VERSION "2021.24.4"

NS_ :

BS_:

BU_: VEH CH Receiver X

BO_ 691 VCRIGHT_logging1Hz: 8 VEH
 SG_ VCRIGHT_logging1HzIndex M : 0|4@1+ (1,0) [0|11] "" X
 SG_ VCRIGHT_LHPanelAirflowBlocked m3 : 54|1@1+ (1,0) [0|1] "" X
 SG_ VCRIGHT_RHPanelAirflowBlocked m3 : 55|1@1+ (1,0) [0|1] "" X
 SG_ VCRIGHT_cabinTempBreathLevel m1 : 56|8@1+ (0.5,-40) [-40|80] "C" X
 SG_ VCRIGHT_cabinTempFanCurrent m9 : 15|6@1- (0.001,0) [-0.01|0.05] "A" X
 SG_ VCRIGHT_cabinTempFanOutput m9 : 14|1@1+ (1,0) [0|1] "" X
 SG_ VCRIGHT_cabinTempGlassRoof m1 : 8|8@1+ (0.5,-40) [-40|80] "C" X
 SG_ VCRIGHT_cabinTempInterior m1 : 24|8@1+ (0.5,-40) [-40|80] "C" X
 SG_ VCRIGHT_cabinTempInteriorL2 m0 : 24|8@1+ (0.5,-40) [-40|80] "C" X
 SG_ VCRIGHT_cabinTempInteriorL3 m9 : 40|8@1+ (0.5,-40) [-40|80] "C" X
 SG_ VCRIGHT_cabinTempInteriorSunny m1 : 32|8@1+ (0.6,-40) [-40|100] "C" X
 SG_ VCRIGHT_cabinTempInteriorSunnyL2 m0 : 40|8@1+ (0.6,-40) [-40|100] "C" X
 SG_ VCRIGHT_cabinTempInteriorSunnyL3 m9 : 48|8@1+ (0.6,-40) [-40|100] "C" X
 SG_ VCRIGHT_cabinTempSideGlassLeft m1 : 40|8@1+ (0.5,-40) [-40|80] "C" X
 SG_ VCRIGHT_cabinTempSideGlassRight m1 : 48|8@1+ (0.5,-40) [-40|80] "C" X
 SG_ VCRIGHT_cabinTempTopPadAir m9 : 56|8@1+ (0.6,-40) [-40|100] "C" X
 SG_ VCRIGHT_cabinTempWindshield m1 : 16|8@1+ (0.5,-40) [-40|80] "C" X
 SG_ VCRIGHT_cloudinessProbability m9 : 33|7@1+ (1,0) [0|100] "%" X
 SG_ VCRIGHT_convectionDeliveredLeft m4 : 24|8@1+ (2,-254) [-254|256] "W/m2" X
 SG_ VCRIGHT_convectionDeliveredRight m4 : 32|8@1+ (2,-254) [-254|256] "W/m2" X
 SG_ VCRIGHT_convectionTargetLeft m4 : 8|8@1+ (2,-254) [-254|256] "W/m2" X
 SG_ VCRIGHT_convectionTargetRight m4 : 16|8@1+ (2,-254) [-254|256] "W/m2" X
 SG_ VCRIGHT_defrostAirflowBlocked m3 : 57|1@1+ (1,0) [0|1] "" X
 SG_ VCRIGHT_evapCondensationRate m10 : 47|9@1- (0.007,0) [-1|1] "g/s" X
 SG_ VCRIGHT_evapDryingRoutineRuntime m10 : 56|5@1+ (2,0) [0|60] "" X
 SG_ VCRIGHT_evapLoadInFresh m5 : 32|8@1+ (35,0) [0|8000] "W" X
 SG_ VCRIGHT_evapLoadInRecirc m5 : 40|8@1+ (35,0) [0|8000] "W" X
 SG_ VCRIGHT_evapWaterMass m10 : 40|7@1+ (6,0) [0|380] "Grams" X
 SG_ VCRIGHT_filterLifeBlowerTorque m9 : 4|10@1+ (0.006,-1.5) [-1.5|4.5] "Nm" X
 SG_ VCRIGHT_floorAirflowBlocked m3 : 56|1@1+ (1,0) [0|1] "" X
 SG_ VCRIGHT_hvacAirFlowModeRow1 m3 : 29|3@1+ (1,0) [0|7] "" X
 SG_ VCRIGHT_hvacAirFlowModeRow2 m3 : 32|3@1+ (1,0) [0|7] "" X
 SG_ VCRIGHT_hvacAirflowReason m3 : 48|4@1+ (1,0) [0|14] "" X
 SG_ VCRIGHT_hvacAutoTransitionReason m3 : 24|5@1+ (1,0) [0|19] "" X
 SG_ VCRIGHT_hvacCabOvrheatProtActive m9 : 30|1@1+ (1,0) [0|1] "" X
 SG_ VCRIGHT_hvacCabOvrheatProtAllowe m9 : 32|1@1+ (1,0) [0|1] "" X
 SG_ VCRIGHT_hvacCabinPurgeActive m9 : 29|1@1+ (1,0) [0|1] "" X
 SG_ VCRIGHT_hvacCabinPurgeAllowed m9 : 31|1@1+ (1,0) [0|1] "" X
 SG_ VCRIGHT_hvacIntakeEndStop m7 : 56|8@1+ (0.02,0) [0|5] "V" X
 SG_ VCRIGHT_hvacIntakeVoltage m6 : 56|8@1+ (0.02,0) [0|5] "V" X
 SG_ VCRIGHT_hvacIntakeZeroStop m8 : 56|8@1+ (0.02,0) [0|5] "V" X
 SG_ VCRIGHT_hvacLHBleedEndStop m7 : 8|8@1+ (0.02,0) [0|5] "V" X
 SG_ VCRIGHT_hvacLHBleedVoltage m6 : 8|8@1+ (0.02,0) [0|5] "V" X
 SG_ VCRIGHT_hvacLHBleedZeroStop m8 : 8|8@1+ (0.02,0) [0|5] "V" X
 SG_ VCRIGHT_hvacLHVaneEndStop m7 : 24|8@1+ (0.02,0) [0|5] "V" X
 SG_ VCRIGHT_hvacLHVaneVoltage m6 : 24|8@1+ (0.02,0) [0|5] "V" X
 SG_ VCRIGHT_hvacLHVaneZeroStop m8 : 24|8@1+ (0.02,0) [0|5] "V" X
 SG_ VCRIGHT_hvacLowerModeEndStop m7 : 48|8@1+ (0.02,0) [0|5] "V" X
 SG_ VCRIGHT_hvacLowerModeVoltage m6 : 48|8@1+ (0.02,0) [0|5] "V" X
 SG_ VCRIGHT_hvacLowerModeZeroStop m8 : 48|8@1+ (0.02,0) [0|5] "V" X
 SG_ VCRIGHT_hvacMassflowTarget m3 : 40|8@1+ (1,0) [0|200] "g/s" X
 SG_ VCRIGHT_hvacQdotFeedforward m5 : 16|16@1+ (1,-32767) [-32767|32767] "W" X
 SG_ VCRIGHT_hvacQdotLimitedLeft m3 : 52|1@1+ (1,0) [0|1] "" X
 SG_ VCRIGHT_hvacQdotLimitedRight m3 : 53|1@1+ (1,0) [0|1] "" X
 SG_ VCRIGHT_hvacRHBleedEndStop m7 : 16|8@1+ (0.02,0) [0|5] "V" X
 SG_ VCRIGHT_hvacRHBleedVoltage m6 : 16|8@1+ (0.02,0) [0|5] "V" X
 SG_ VCRIGHT_hvacRHBleedZeroStop m8 : 16|8@1+ (0.02,0) [0|5] "V" X
 SG_ VCRIGHT_hvacRHVaneEndStop m7 : 32|8@1+ (0.02,0) [0|5] "V" X
 SG_ VCRIGHT_hvacRHVaneVoltage m6 : 32|8@1+ (0.02,0) [0|5] "V" X
 SG_ VCRIGHT_hvacRHVaneZeroStop m8 : 32|8@1+ (0.02,0) [0|5] "V" X
 SG_ VCRIGHT_hvacSetTempActualLeft m3 : 8|8@1+ (0.1,15) [15|28] "C" X
 SG_ VCRIGHT_hvacSetTempActualRight m3 : 16|8@1+ (0.1,15) [15|28] "C" X
 SG_ VCRIGHT_hvacUpperModeEndStop m7 : 40|8@1+ (0.02,0) [0|5] "V" X
 SG_ VCRIGHT_hvacUpperModeVoltage m6 : 40|8@1+ (0.02,0) [0|5] "V" X
 SG_ VCRIGHT_hvacUpperModeZeroStop m8 : 40|8@1+ (0.02,0) [0|5] "V" X
 SG_ VCRIGHT_leftHeatOvertempProtect m10 : 61|1@1+ (1,0) [0|1] "" X
 SG_ VCRIGHT_pcbaTemperature m2 : 4|11@1+ (0.125,-40) [-40|150] "C" X
 SG_ VCRIGHT_ptcHeaterHvacActNotReady m5 : 7|1@1+ (1,0) [0|1] "" X
 SG_ VCRIGHT_ptcHeaterLAirPathBlocked m5 : 10|1@1+ (1,0) [0|1] "" X
 SG_ VCRIGHT_ptcHeaterNoAirflow m5 : 6|1@1+ (1,0) [0|1] "" X
 SG_ VCRIGHT_ptcHeaterNoHighVoltage m5 : 9|1@1+ (1,0) [0|1] "" X
 SG_ VCRIGHT_ptcHeaterNoUiRequest m5 : 8|1@1+ (1,0) [0|1] "" X
 SG_ VCRIGHT_ptcHeaterPwrDemandLeft m2 : 40|8@1+ (20,0) [0|5000] "W" X
 SG_ VCRIGHT_ptcHeaterPwrDemandRight m2 : 48|8@1+ (20,0) [0|5000] "W" X
 SG_ VCRIGHT_ptcHeaterRAirPathBlocked m5 : 11|1@1+ (1,0) [0|1] "" X
 SG_ VCRIGHT_ptcHeaterReqAirpathBlock m5 : 12|1@1+ (1,0) [0|1] "" X
 SG_ VCRIGHT_ptcHeaterTempDuctFault m5 : 5|1@1+ (1,0) [0|1] "" X
 SG_ VCRIGHT_ptcHeaterTempDuctHigh m5 : 4|1@1+ (1,0) [0|1] "" X
 SG_ VCRIGHT_rightHeatOvertempProtect m10 : 62|1@1+ (1,0) [0|1] "" X
 SG_ VCRIGHT_solarLoadLeftOccupant m4 : 48|7@1+ (2,0) [0|254] "W/m2" X
 SG_ VCRIGHT_solarLoadOnVehFiltered m9 : 21|8@1+ (4,0) [0|1020] "W/m2" X
 SG_ VCRIGHT_solarLoadOnVehicle m4 : 56|8@1+ (4,0) [0|1020] "W/m2" X
 SG_ VCRIGHT_solarLoadRightOccupant m4 : 40|7@1+ (2,0) [0|254] "W/m2" X
 SG_ VCRIGHT_tempDuctModeledLeft m10 : 4|9@1+ (0.3,-40) [-40|105] "C" X
 SG_ VCRIGHT_tempDuctModeledRight m10 : 13|9@1+ (0.3,-40) [-40|105] "C" X
 SG_ VCRIGHT_tempHtrSurfaceModeledL m10 : 22|9@1+ (0.3,-40) [-40|105] "C" X
 SG_ VCRIGHT_tempHtrSurfaceModeledR m10 : 31|9@1+ (0.3,-40) [-40|105] "C" X
 SG_ VCRIGHT_tempIncarCabinDeep m0 : 16|8@1+ (0.5,-40) [-40|85] "C" X
 SG_ VCRIGHT_tempIncarCabinMid m0 : 32|8@1+ (0.5,-40) [-40|85] "C" X
 SG_ VCRIGHT_tempIncarCabinProbe m0 : 8|8@1+ (0.5,-40) [-40|85] "C" X
 SG_ VCRIGHT_wattsHeaterLeftTotal m2 : 16|10@1+ (5,0) [0|4000] "W" X
 SG_ VCRIGHT_wattsHeaterRightTotal m2 : 26|10@1+ (5,0) [0|4000] "W" X

BO_ 1859 VCRIGHT_recallStatus: 1 VEH
 SG_ VCRIGHT_mirrorRecallStatus: 4|2@1+ (1,0) [0|0] "" X
 SG_ VCRIGHT_seatRecallStatus: 2|2@1+ (1,0) [0|0] "" X
 SG_ VCRIGHT_systemRecallStatus: 0|2@1+ (1,0) [0|0] "" X

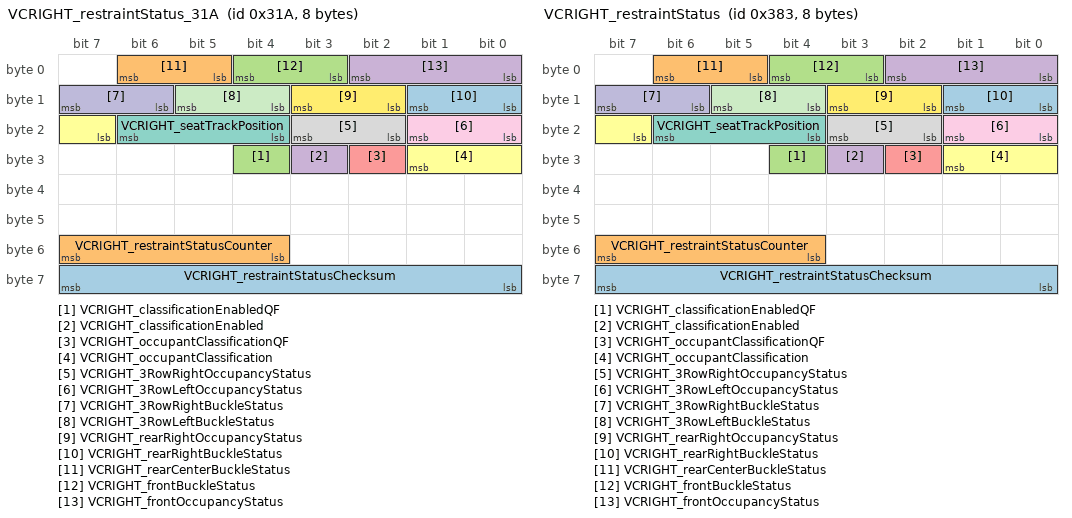
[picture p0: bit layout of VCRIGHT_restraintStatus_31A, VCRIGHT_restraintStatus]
BO_ 794 VCRIGHT_restraintStatus_31A: 8 Vector__XXX
 SG_ VCRIGHT_restraintStatusChecksum : 56|8@1+ (1,0) [0|0] "" Vector__XXX
 SG_ VCRIGHT_restraintStatusCounter : 52|4@1+ (1,0) [0|0] "" Vector__XXX
 SG_ VCRIGHT_classificationEnabledQF : 28|1@1+ (1,0) [0|0] "" Vector__XXX
 SG_ VCRIGHT_classificationEnabled : 27|1@1+ (1,0) [0|0] "" Vector__XXX
 SG_ VCRIGHT_occupantClassificationQF : 26|1@1+ (1,0) [0|0] "" Vector__XXX
 SG_ VCRIGHT_occupantClassification : 23|3@1+ (1,0) [0|0] "" Vector__XXX
 SG_ VCRIGHT_seatTrackPosition : 20|3@1+ (1,0) [0|0] "" Vector__XXX
 SG_ VCRIGHT_3RowRightOccupancyStatus : 18|2@1+ (1,0) [0|0] "" Vector__XXX
 SG_ VCRIGHT_3RowLeftOccupancyStatus : 16|2@1+ (1,0) [0|0] "" Vector__XXX
 SG_ VCRIGHT_3RowRightBuckleStatus : 14|2@1+ (1,0) [0|0] "" Vector__XXX
 SG_ VCRIGHT_3RowLeftBuckleStatus : 12|2@1+ (1,0) [0|0] "" Vector__XXX
 SG_ VCRIGHT_rearRightOccupancyStatus : 10|2@1+ (1,0) [0|0] "" Vector__XXX
 SG_ VCRIGHT_rearRightBuckleStatus : 8|2@1+ (1,0) [0|0] "" Vector__XXX
 SG_ VCRIGHT_rearCenterBuckleStatus : 5|2@1+ (1,0) [0|0] "" Vector__XXX
 SG_ VCRIGHT_frontBuckleStatus : 3|2@1+ (1,0) [0|0] "" Vector__XXX
 SG_ VCRIGHT_frontOccupancyStatus : 0|3@1+ (1,0) [0|0] "" Vector__XXX

BO_ 1251 VCRIGHT_seatStatus: 8 Vector__XXX
 SG_ VCRIGHT_lumbarDevMaxPumpPressB m4 : 60|1@1+ (1,0) [0|0] "" Vector__XXX
 SG_ VCRIGHT_lumbarDevMaxPumpPressA m4 : 59|1@1+ (1,0) [0|0] "" Vector__XXX
 SG_ VCRIGHT_lumbarGeneralErr m4 : 58|1@1+ (1,0) [0|0] "" Vector__XXX
 SG_ VCRIGHT_lumbarMinPErr m4 : 57|1@1+ (1,0) [0|0] "" Vector__XXX
 SG_ VCRIGHT_lumbarMaxOperatingPErr m4 : 56|1@1+ (1,0) [0|0] "" Vector__XXX
 SG_ VCRIGHT_frontSeatBackPercentage m1 : 55|7@1+ (1,0) [0|0] "" Vector__XXX
 SG_ VCRIGHT_frontSeatLiftPercentage m2 : 55|7@1+ (1,0) [0|0] "" Vector__XXX
 SG_ VCRIGHT_frontSeatTiltPercentage m3 : 55|7@1+ (1,0) [0|0] "" Vector__XXX
 SG_ VCRIGHT_frontSeatTrackPercentage m0 : 55|7@1+ (1,0) [0|0] "" Vector__XXX
 SG_ VCRIGHT_lumbarOvercurrentErr m4 : 55|1@1+ (1,0) [0|0] "" Vector__XXX
 SG_ VCRIGHT_lumbarMaxPErr m4 : 54|1@1+ (1,0) [0|0] "" Vector__XXX
 SG_ VCRIGHT_frontSeatBackBridgeSt m1 : 53|2@1+ (1,0) [0|0] "" Vector__XXX
 SG_ VCRIGHT_frontSeatLiftBridgeSt m2 : 53|2@1+ (1,0) [0|0] "" Vector__XXX
 SG_ VCRIGHT_frontSeatTiltBridgeSt m3 : 53|2@1+ (1,0) [0|0] "" Vector__XXX
 SG_ VCRIGHT_frontSeatTrackBridgeSt m0 : 53|2@1+ (1,0) [0|0] "" Vector__XXX
 SG_ VCRIGHT_lumbarActiveTooLongErr m4 : 53|1@1+ (1,0) [0|0] "" Vector__XXX
 SG_ VCRIGHT_frontSeatBackLog m1 : 52|1@1+ (1,0) [0|0] "" Vector__XXX
 SG_ VCRIGHT_frontSeatLiftLog m2 : 52|1@1+ (1,0) [0|0] "" Vector__XXX
 SG_ VCRIGHT_frontSeatTiltLog m3 : 52|1@1+ (1,0) [0|0] "" Vector__XXX
 SG_ VCRIGHT_frontSeatTrackLog m0 : 52|1@1+ (1,0) [0|0] "" Vector__XXX
 SG_ VCRIGHT_frontSeatBackCalibrated m1 : 51|1@1+ (1,0) [0|0] "" Vector__XXX
 SG_ VCRIGHT_frontSeatLiftCalibrated m2 : 51|1@1+ (1,0) [0|0] "" Vector__XXX
 SG_ VCRIGHT_frontSeatTiltCalibrated m3 : 51|1@1+ (1,0) [0|0] "" Vector__XXX
 SG_ VCRIGHT_frontSeatTrackCalibrated m0 : 51|1@1+ (1,0) [0|0] "" Vector__XXX
 SG_ VCRIGHT_frontSeatBackState m1 : 48|3@1+ (1,0) [0|0] "" Vector__XXX
 SG_ VCRIGHT_frontSeatLiftState m2 : 48|3@1+ (1,0) [0|0] "" Vector__XXX
 SG_ VCRIGHT_frontSeatTiltState m3 : 48|3@1+ (1,0) [0|0] "" Vector__XXX
 SG_ VCRIGHT_frontSeatTrackState m0 : 48|3@1+ (1,0) [0|0] "" Vector__XXX
 SG_ VCRIGHT_lumbarBPressureHpaFilt m4 : 43|10@1+ (1,0) [0|0] "" Vector__XXX
 SG_ VCRIGHT_frontSeatTiltPosOffset m6 : 40|12@1- (0.1,0) [0|0] "" Vector__XXX
 SG_ VCRIGHT_frontSeatTiltPosReal m5 : 40|12@1- (0.1,0) [0|0] "" Vector__XXX
 SG_ VCRIGHT_frontSeatBackDuty m1 : 36|12@1- (0.1,0) [0|0] "" Vector__XXX
 SG_ VCRIGHT_frontSeatLiftDuty m2 : 36|12@1- (0.1,0) [0|0] "" Vector__XXX
 SG_ VCRIGHT_frontSeatTiltDuty m3 : 36|12@1- (0.1,0) [0|0] "" Vector__XXX
 SG_ VCRIGHT_frontSeatTrackDuty m0 : 36|12@1- (0.1,0) [0|0] "" Vector__XXX
 SG_ VCRIGHT_lumbarBPressureHpa m4 : 31|12@1+ (1,0) [0|0] "" Vector__XXX
 SG_ VCRIGHT_frontSeatLiftPosOffset m6 : 28|12@1- (1,0) [0|0] "" Vector__XXX
 SG_ VCRIGHT_frontSeatLiftPosReal m5 : 28|12@1- (1,0) [0|0] "" Vector__XXX
 SG_ VCRIGHT_frontSeatBackCurrent m1 : 24|12@1- (0.01,0) [0|0] "" Vector__XXX
 SG_ VCRIGHT_frontSeatLiftCurrent m2 : 24|12@1- (0.01,0) [0|0] "" Vector__XXX
 SG_ VCRIGHT_frontSeatTiltCurrent m3 : 24|12@1- (0.01,0) [0|0] "" Vector__XXX
 SG_ VCRIGHT_frontSeatTrackCurrent m0 : 24|12@1- (0.01,0) [0|0] "" Vector__XXX
 SG_ VCRIGHT_lumbarAPressureHpaFilt m4 : 21|10@1+ (1,0) [0|0] "" Vector__XXX
 SG_ VCRIGHT_frontSeatBackPosOffset m6 : 16|12@1- (0.1,0) [0|0] "" Vector__XXX
 SG_ VCRIGHT_frontSeatBackPosReal m5 : 16|12@1- (0.1,0) [0|0] "" Vector__XXX
 SG_ VCRIGHT_lumbarBPressurePercentage m7 : 10|7@1+ (1,0) [0|0] "" Vector__XXX
 SG_ VCRIGHT_lumbarAPressureHpa m4 : 9|12@1+ (1,0) [0|0] "" Vector__XXX
 SG_ VCRIGHT_frontSeatBackPos m1 : 8|16@1- (1,0) [0|0] "" Vector__XXX
 SG_ VCRIGHT_frontSeatLiftPos m2 : 8|16@1- (1,0) [0|0] "" Vector__XXX
 SG_ VCRIGHT_frontSeatTiltPos m3 : 8|16@1- (1,0) [0|0] "" Vector__XXX
 SG_ VCRIGHT_frontSeatTrackPos m0 : 8|16@1- (1,0) [0|0] "" Vector__XXX
 SG_ VCRIGHT_lumbarBState m4 : 6|3@1+ (1,0) [0|0] "" Vector__XXX
 SG_ VC_AH_1RowRightSeatMovementHealth m0 : 5|3@1+ (1,0) [0|0] "" Vector__XXX
 SG_ VCRIGHT_frontSeatTrackPosOffset m6 : 3|12@1- (1,0) [0|0] "" Vector__XXX
 SG_ VCRIGHT_frontSeatTrackPosReal m5 : 3|12@1- (1,0) [0|0] "" Vector__XXX
 SG_ VCRIGHT_lumbarAPressurePercentage m7 : 3|7@1+ (1,0) [0|0] "" Vector__XXX
 SG_ VCRIGHT_lumbarAState m4 : 3|3@1+ (1,0) [0|0] "" Vector__XXX
 SG_ VCRIGHT_seatStatusIndex M : 0|3@1+ (1,0) [0|0] "" Vector__XXX

BO_ 899 VCRIGHT_restraintStatus: 8 Vector__XXX
 SG_ VCRIGHT_restraintStatusChecksum : 56|8@1+ (1,0) [0|0] "" Vector__XXX
 SG_ VCRIGHT_restraintStatusCounter : 52|4@1+ (1,0) [0|0] "" Vector__XXX
 SG_ VCRIGHT_classificationEnabledQF : 28|1@1+ (1,0) [0|0] "" Vector__XXX
 SG_ VCRIGHT_classificationEnabled : 27|1@1+ (1,0) [0|0] "" Vector__XXX
 SG_ VCRIGHT_occupantClassificationQF : 26|1@1+ (1,0) [0|0] "" Vector__XXX
 SG_ VCRIGHT_occupantClassification : 23|3@1+ (1,0) [0|0] "" Vector__XXX
 SG_ VCRIGHT_seatTrackPosition : 20|3@1+ (1,0) [0|0] "" Vector__XXX
 SG_ VCRIGHT_3RowRightOccupancyStatus : 18|2@1+ (1,0) [0|0] "" Vector__XXX
 SG_ VCRIGHT_3RowLeftOccupancyStatus : 16|2@1+ (1,0) [0|0] "" Vector__XXX
 SG_ VCRIGHT_3RowRightBuckleStatus : 14|2@1+ (1,0) [0|0] "" Vector__XXX
 SG_ VCRIGHT_3RowLeftBuckleStatus : 12|2@1+ (1,0) [0|0] "" Vector__XXX
 SG_ VCRIGHT_rearRightOccupancyStatus : 10|2@1+ (1,0) [0|0] "" Vector__XXX
 SG_ VCRIGHT_rearRightBuckleStatus : 8|2@1+ (1,0) [0|0] "" Vector__XXX
 SG_ VCRIGHT_rearCenterBuckleStatus : 5|2@1+ (1,0) [0|0] "" Vector__XXX
 SG_ VCRIGHT_frontBuckleStatus : 3|2@1+ (1,0) [0|0] "" Vector__XXX
 SG_ VCRIGHT_frontOccupancyStatus : 0|3@1+ (1,0) [0|0] "" Vector__XXX

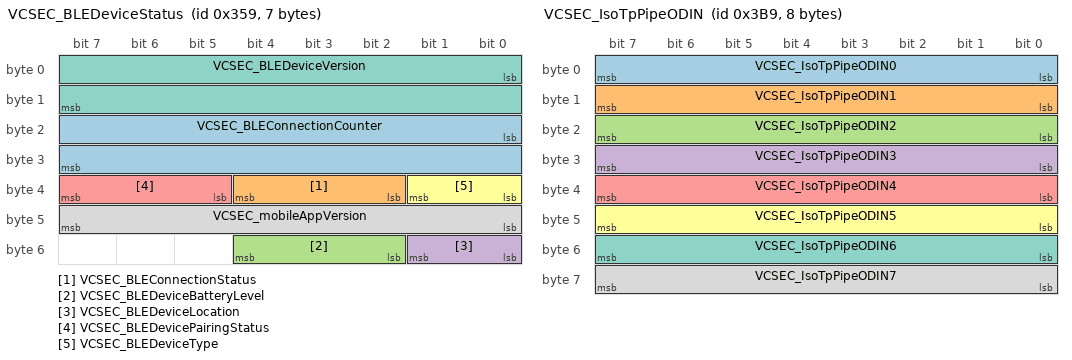
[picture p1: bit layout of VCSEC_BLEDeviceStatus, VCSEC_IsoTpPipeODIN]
BO_ 857 VCSEC_BLEDeviceStatus: 7 VEH
 SG_ VCSEC_BLEConnectionCounter: 16|16@1+ (1,0) [0|0] "" X
 SG_ VCSEC_BLEConnectionStatus: 34|3@1+ (1,0) [0|0] "" X
 SG_ VCSEC_BLEDeviceBatteryLevel: 50|3@1+ (1,0) [0|0] "" X
 SG_ VCSEC_BLEDeviceLocation: 48|2@1+ (1,0) [0|0] "" X
 SG_ VCSEC_BLEDevicePairingStatus: 37|3@1+ (1,0) [0|0] "" X
 SG_ VCSEC_BLEDeviceType: 32|2@1+ (1,0) [0|0] "" X
 SG_ VCSEC_BLEDeviceVersion: 0|16@1+ (1,0) [0|0] "" X
 SG_ VCSEC_mobileAppVersion: 40|8@1+ (1,0) [0|0] "" X

BO_ 969 VCSEC_BLEEndpointInfo: 8 Vector__XXX
 SG_ VCSEC_BLECENTERUsageID m1 : 40|16@1+ (1,0) [0|0] "" Vector__XXX
 SG_ VCSEC_BLELEFTUsageID m4 : 40|16@1+ (1,0) [0|0] "" Vector__XXX
 SG_ VCSEC_BLEREARUsageID m10 : 40|16@1+ (1,0) [0|0] "" Vector__XXX
 SG_ VCSEC_BLERIGHTUsageID m7 : 40|16@1+ (1,0) [0|0] "" Vector__XXX
 SG_ VCSEC_BLECENTERAssemblyID m1 : 32|8@1+ (1,0) [0|0] "" Vector__XXX
 SG_ VCSEC_BLELEFTAssemblyID m4 : 32|8@1+ (1,0) [0|0] "" Vector__XXX
 SG_ VCSEC_BLEREARAssemblyID m10 : 32|8@1+ (1,0) [0|0] "" Vector__XXX
 SG_ VCSEC_BLERIGHTAssemblyID m7 : 32|8@1+ (1,0) [0|0] "" Vector__XXX
 SG_ VCSEC_BLECENTERPcbaID m1 : 24|8@1+ (1,0) [0|0] "" Vector__XXX
 SG_ VCSEC_BLELEFTPcbaID m4 : 24|8@1+ (1,0) [0|0] "" Vector__XXX
 SG_ VCSEC_BLEREARPcbaID m10 : 24|8@1+ (1,0) [0|0] "" Vector__XXX
 SG_ VCSEC_BLERIGHTPcbaID m7 : 24|8@1+ (1,0) [0|0] "" Vector__XXX
 SG_ VCSEC_BLECENTERAppGitHashByte m0 : 8|56@1+ (1,0) [0|0] "" Vector__XXX
 SG_ VCSEC_BLECENTERComponentID m1 : 8|16@1+ (1,0) [0|0] "" Vector__XXX
 SG_ VCSEC_BLECENTERCrc m2 : 8|32@1+ (1,0) [0|0] "" Vector__XXX
 SG_ VCSEC_BLELEFTAppGitHashByte m3 : 8|56@1+ (1,0) [0|0] "" Vector__XXX
 SG_ VCSEC_BLELEFTComponentID m4 : 8|16@1+ (1,0) [0|0] "" Vector__XXX
 SG_ VCSEC_BLELEFTCrc m5 : 8|32@1+ (1,0) [0|0] "" Vector__XXX
 SG_ VCSEC_BLEREARAppGitHashByte m9 : 8|56@1+ (1,0) [0|0] "" Vector__XXX
 SG_ VCSEC_BLEREARComponentID m10 : 8|16@1+ (1,0) [0|0] "" Vector__XXX
 SG_ VCSEC_BLEREARCrc m11 : 8|32@1+ (1,0) [0|0] "" Vector__XXX
 SG_ VCSEC_BLERIGHTAppGitHashByte m6 : 8|56@1+ (1,0) [0|0] "" Vector__XXX
 SG_ VCSEC_BLERIGHTComponentID m7 : 8|16@1+ (1,0) [0|0] "" Vector__XXX
 SG_ VCSEC_BLERIGHTCrc m8 : 8|32@1+ (1,0) [0|0] "" Vector__XXX
 SG_ VCSEC_BLEEndpointInfoIndex M : 0|8@1+ (1,0) [0|0] "" Vector__XXX

BO_ 953 VCSEC_IsoTpPipeODIN: 8 VEH
 SG_ VCSEC_IsoTpPipeODIN0: 0|8@1+ (1,0) [0|0] "" X
 SG_ VCSEC_IsoTpPipeODIN1: 8|8@1+ (1,0) [0|0] "" X
 SG_ VCSEC_IsoTpPipeODIN2: 16|8@1+ (1,0) [0|0] "" X
 SG_ VCSEC_IsoTpPipeODIN3: 24|8@1+ (1,0) [0|0] "" X
 SG_ VCSEC_IsoTpPipeODIN4: 32|8@1+ (1,0) [0|0] "" X
 SG_ VCSEC_IsoTpPipeODIN5: 40|8@1+ (1,0) [0|0] "" X
 SG_ VCSEC_IsoTpPipeODIN6: 48|8@1+ (1,0) [0|0] "" X
 SG_ VCSEC_IsoTpPipeODIN7: 56|8@1+ (1,0) [0|0] "" X

BO_ 473 VCSEC_IsoTpUDPPipeUI: 3 Vector__XXX
 SG_ VCSEC_IsoTpUDPPipeUI2 : 16|8@1+ (1,0) [0|0] "" Vector__XXX
 SG_ VCSEC_IsoTpUDPPipeUI1 : 8|8@1+ (1,0) [0|0] "" Vector__XXX
 SG_ VCSEC_IsoTpUDPPipeUI0 : 0|8@1+ (1,0) [0|0] "" Vector__XXX

BO_ 1017 VCSEC_alertMatrix: 8 VEH
 SG_ VCSEC_matrixIndex M: 0|4@1+ (1,0) [0|0] "" X
 SG_ VCSEC_a001_WatchdogReset m0: 4|1@1+ (1,0) [0|0] "" X
 SG_ VCSEC_a002_PowerLossReset m0: 5|1@1+ (1,0) [0|0] "" X
 SG_ VCSEC_a003_SWAssertion m0: 6|1@1+ (1,0) [0|0] "" X
 SG_ VCSEC_a010_ExtSupplyVoltError m0: 13|1@1+ (1,0) [0|0] "" X
 SG_ VCSEC_a012_CPUReset m0: 15|1@1+ (1,0) [0|0] "" X
 SG_ VCSEC_a013_AlertManagerFault m0: 16|1@1+ (1,0) [0|0] "" X
 SG_ VCSEC_a015_NVMMAlert m0: 18|1@1+ (1,0) [0|0] "" X
 SG_ VCSEC_a021_TaskSchedulerError m0: 24|1@1+ (1,0) [0|0] "" X
 SG_ VCSEC_a022_TaskInitError m0: 25|1@1+ (1,0) [0|0] "" X
 SG_ VCSEC_a031_UDSActive m0: 34|1@1+ (1,0) [0|0] "" X
 SG_ VCSEC_a041_HighCPULoad m0: 44|1@1+ (1,0) [0|0] "" X
 SG_ VCSEC_a042_HighStackUsage m0: 45|1@1+ (1,0) [0|0] "" X
 SG_ VCSEC_a043_Task1msError m0: 46|1@1+ (1,0) [0|0] "" X
 SG_ VCSEC_a044_Task10msError m0: 47|1@1+ (1,0) [0|0] "" X
 SG_ VCSEC_a045_Task100msError m0: 48|1@1+ (1,0) [0|0] "" X
 SG_ VCSEC_a046_Task1000msError m0: 49|1@1+ (1,0) [0|0] "" X
 SG_ VCSEC_a059_inputResistanceHigh m0: 62|1@1+ (1,0) [0|0] "" X
 SG_ VCSEC_a060_engineeringBuild m0: 63|1@1+ (1,0) [0|0] "" X
 SG_ VCSEC_a061_XCPConnected m1: 4|1@1+ (1,0) [0|0] "" X
 SG_ VCSEC_a062_XCPWasConnected m1: 5|1@1+ (1,0) [0|0] "" X
 SG_ VCSEC_a063_SwitchFault m1: 6|1@1+ (1,0) [0|0] "" X
 SG_ VCSEC_a064_busSleepReqTimeout m1: 7|1@1+ (1,0) [0|0] "" X
 SG_ VCSEC_a097_CMP_MIA m1: 40|1@1+ (1,0) [0|0] "" X
 SG_ VCSEC_a098_DI_THERMAL_MIA m1: 41|1@1+ (1,0) [0|0] "" X
 SG_ VCSEC_a099_PARK_MIA m1: 42|1@1+ (1,0) [0|0] "" X
 SG_ VCSEC_a100_CANbus_MIA m1: 43|1@1+ (1,0) [0|0] "" X
 SG_ VCSEC_a101_PM_MIA m1: 44|1@1+ (1,0) [0|0] "" X
 SG_ VCSEC_a102_PTC_MIA m1: 45|1@1+ (1,0) [0|0] "" X
 SG_ VCSEC_a103_CP_MIA m1: 46|1@1+ (1,0) [0|0] "" X
 SG_ VCSEC_a104_DAS_MIA m1: 47|1@1+ (1,0) [0|0] "" X
 SG_ VCSEC_a105_TAS_MIA m1: 48|1@1+ (1,0) [0|0] "" X
 SG_ VCSEC_a106_PCS_MIA m1: 49|1@1+ (1,0) [0|0] "" X
 SG_ VCSEC_a107_BMS_MIA m1: 50|1@1+ (1,0) [0|0] "" X
 SG_ VCSEC_a108_DIS_MIA m1: 51|1@1+ (1,0) [0|0] "" X
 SG_ VCSEC_a109_RCM_MIA m1: 52|1@1+ (1,0) [0|0] "" X
 SG_ VCSEC_a110_GTW_MIA m1: 53|1@1+ (1,0) [0|0] "" X
 SG_ VCSEC_a111_EPBR_MIA m1: 54|1@1+ (1,0) [0|0] "" X
 SG_ VCSEC_a112_EPBL_MIA m1: 55|1@1+ (1,0) [0|0] "" X
 SG_ VCSEC_a113_UI_MIA m1: 56|1@1+ (1,0) [0|0] "" X
 SG_ VCSEC_a114_ESP_MIA m1: 57|1@1+ (1,0) [0|0] "" X
 SG_ VCSEC_a115_VCSEC_MIA m1: 58|1@1+ (1,0) [0|0] "" X
 SG_ VCSEC_a116_VCRIGHT_MIA m1: 59|1@1+ (1,0) [0|0] "" X
 SG_ VCSEC_a117_VCLEFT_MIA m1: 60|1@1+ (1,0) [0|0] "" X
 SG_ VCSEC_a118_VCFRONT_MIA m1: 61|1@1+ (1,0) [0|0] "" X
 SG_ VCSEC_a119_SCCM_MIA m1: 62|1@1+ (1,0) [0|0] "" X
 SG_ VCSEC_a120_DI_DRIVE_MIA m1: 63|1@1+ (1,0) [0|0] "" X
 SG_ VCSEC_a133_alarmTriggered m2: 16|1@1+ (1,0) [0|0] "" X
 SG_ VCSEC_a134_badCertificate m2: 17|1@1+ (1,0) [0|0] "" X
 SG_ VCSEC_a135_centerEndpointMIA m2: 18|1@1+ (1,0) [0|0] "" X
 SG_ VCSEC_a136_leftEndpointMIA m2: 19|1@1+ (1,0) [0|0] "" X
 SG_ VCSEC_a137_rightEndpointMIA m2: 20|1@1+ (1,0) [0|0] "" X
 SG_ VCSEC_a138_rearEndpointMIA m2: 21|1@1+ (1,0) [0|0] "" X
 SG_ VCSEC_a140_nfcAuthentication m2: 23|1@1+ (1,0) [0|0] "" X
 SG_ VCSEC_a141_tooFewKeysOnWhitelist m2: 24|1@1+ (1,0) [0|0] "" X
 SG_ VCSEC_a142_bleGattAlertC m2: 25|1@1+ (1,0) [0|0] "" X
 SG_ VCSEC_a143_bleGattAlertL m2: 26|1@1+ (1,0) [0|0] "" X
 SG_ VCSEC_a144_bleGattAlertR m2: 27|1@1+ (1,0) [0|0] "" X
 SG_ VCSEC_a145_bleGattAlertRe m2: 28|1@1+ (1,0) [0|0] "" X
 SG_ VCSEC_a147_protobufRXTimeout m2: 30|1@1+ (1,0) [0|0] "" X
 SG_ VCSEC_a148_keyWhitelistFull m2: 31|1@1+ (1,0) [0|0] "" X
 SG_ VCSEC_a149_attrsWentMissingL m2: 32|1@1+ (1,0) [0|0] "" X
 SG_ VCSEC_a150_attrsWentMissingR m2: 33|1@1+ (1,0) [0|0] "" X
 SG_ VCSEC_a151_attrsWentMissingRe m2: 34|1@1+ (1,0) [0|0] "" X
 SG_ VCSEC_a153_srvcCmdTimeoutC m2: 36|1@1+ (1,0) [0|0] "" X
 SG_ VCSEC_a154_srvcCmdTimeoutL m2: 37|1@1+ (1,0) [0|0] "" X
 SG_ VCSEC_a155_srvcCmdTimeoutR m2: 38|1@1+ (1,0) [0|0] "" X
 SG_ VCSEC_a156_srvcCmdTimeoutRe m2: 39|1@1+ (1,0) [0|0] "" X
 SG_ VCSEC_a158_hciFaultC m2: 41|1@1+ (1,0) [0|0] "" X
 SG_ VCSEC_a159_hciFaultL m2: 42|1@1+ (1,0) [0|0] "" X
 SG_ VCSEC_a161_hciFaultR m2: 44|1@1+ (1,0) [0|0] "" X
 SG_ VCSEC_a162_hciFaultRe m2: 45|1@1+ (1,0) [0|0] "" X
 SG_ VCSEC_a164_attrsWentMissingC m2: 47|1@1+ (1,0) [0|0] "" X
 SG_ VCSEC_a165_ephemeralKeyGenerated m2: 48|1@1+ (1,0) [0|0] "" X
 SG_ VCSEC_a166_BLECenterPowerCycled m2: 49|1@1+ (1,0) [0|0] "" X
 SG_ VCSEC_a167_BLECenterSoftReset m2: 50|1@1+ (1,0) [0|0] "" X
 SG_ VCSEC_a168_BLELeftSoftReset m2: 51|1@1+ (1,0) [0|0] "" X
 SG_ VCSEC_a169_BLERightSoftReset m2: 52|1@1+ (1,0) [0|0] "" X
 SG_ VCSEC_a170_BLERearSoftReset m2: 53|1@1+ (1,0) [0|0] "" X
 SG_ VCSEC_a172_BLEUnexpectedResetC m2: 55|1@1+ (1,0) [0|0] "" X
 SG_ VCSEC_a173_BLEUnexpectedResetL m2: 56|1@1+ (1,0) [0|0] "" X
 SG_ VCSEC_a174_BLEUnexpectedResetRi m2: 57|1@1+ (1,0) [0|0] "" X
 SG_ VCSEC_a175_BLEUnexpectedResetRe m2: 58|1@1+ (1,0) [0|0] "" X
 SG_ VCSEC_a177_whitelistAddedKey m2: 60|1@1+ (1,0) [0|0] "" X
 SG_ VCSEC_a178_whitelistRemovedKey m2: 61|1@1+ (1,0) [0|0] "" X
 SG_ VCSEC_a179_wlistAddedPermission m2: 62|1@1+ (1,0) [0|0] "" X
 SG_ VCSEC_a180_wlistRemovedPermission m2: 63|1@1+ (1,0) [0|0] "" X
 SG_ VCSEC_a181_signedMessageFault m3: 4|1@1+ (1,0) [0|0] "" X
 SG_ VCSEC_a182_cryptoHighStackUsage m3: 5|1@1+ (1,0) [0|0] "" X
 SG_ VCSEC_a183_centerEndpointRFMia m3: 6|1@1+ (1,0) [0|0] "" X
 SG_ VCSEC_a184_driverEndpointRFMia m3: 7|1@1+ (1,0) [0|0] "" X
 SG_ VCSEC_a185_passengerEndpointRFMia m3: 8|1@1+ (1,0) [0|0] "" X
 SG_ VCSEC_a186_rearEndpointRFMia m3: 9|1@1+ (1,0) [0|0] "" X
 SG_ VCSEC_a187_badConnectionDropped m3: 10|1@1+ (1,0) [0|0] "" X
 SG_ VCSEC_a188_protobufDecodeError m3: 11|1@1+ (1,0) [0|0] "" X
 SG_ VCSEC_a189_protoExpLengthTooLarge m3: 12|1@1+ (1,0) [0|0] "" X
 SG_ VCSEC_a190_protoTooManyBytes m3: 13|1@1+ (1,0) [0|0] "" X
 SG_ VCSEC_a191_macIDWlistingFailedC m3: 14|1@1+ (1,0) [0|0] "" X
 SG_ VCSEC_a192_macIDWlistingFailedL m3: 15|1@1+ (1,0) [0|0] "" X
 SG_ VCSEC_a193_macIDWlistingFailedRi m3: 16|1@1+ (1,0) [0|0] "" X
 SG_ VCSEC_a194_macIDWlistingFailedRe m3: 17|1@1+ (1,0) [0|0] "" X
 SG_ VCSEC_a195_keyMissingInDrive m3: 18|1@1+ (1,0) [0|0] "" X
 SG_ VCSEC_a196_protobufTXTimeout m3: 19|1@1+ (1,0) [0|0] "" X
 SG_ VCSEC_a197_indicationFault m3: 20|1@1+ (1,0) [0|0] "" X
 SG_ VCSEC_a198_BPillarNFCReaderMIA m3: 21|1@1+ (1,0) [0|0] "" X
 SG_ VCSEC_a199_CenterNFCReaderMIA m3: 22|1@1+ (1,0) [0|0] "" X
 SG_ VCSEC_a200_centerEndpointLostComm m3: 23|1@1+ (1,0) [0|0] "" X
 SG_ VCSEC_a201_leftEndpointLostComm m3: 24|1@1+ (1,0) [0|0] "" X
 SG_ VCSEC_a202_rightEndpointLostComm m3: 25|1@1+ (1,0) [0|0] "" X
 SG_ VCSEC_a203_rearEndpointLostComm m3: 26|1@1+ (1,0) [0|0] "" X
 SG_ VCSEC_a204_SharedSecretsWritten m3: 27|1@1+ (1,0) [0|0] "" X
 SG_ VCSEC_a205_MTUUpdateNotConfirmed m3: 28|1@1+ (1,0) [0|0] "" X
 SG_ VCSEC_a206_BLELeftAssertFailure m3: 29|1@1+ (1,0) [0|0] "" X
 SG_ VCSEC_a207_BLERightAssertFailure m3: 30|1@1+ (1,0) [0|0] "" X
 SG_ VCSEC_a208_BLERearAssertFailure m3: 31|1@1+ (1,0) [0|0] "" X
 SG_ VCSEC_a209_BLECenterAssertFailure m3: 32|1@1+ (1,0) [0|0] "" X

BO_ 825 VCSEC_authentication: 8 VEH
 SG_ VCSEC_MCUCommandType: 36|3@1+ (1,0) [0|0] "" X
 SG_ VCSEC_alarmStatus: 43|4@1+ (1,0) [0|0] "" X
 SG_ VCSEC_authRequested: 60|1@1+ (1,0) [0|0] "" X
 SG_ VCSEC_authenticationStatus: 16|2@1+ (1,0) [0|0] "" X
 SG_ VCSEC_chargePortLockStatus: 18|1@1+ (1,0) [0|0] "" X
 SG_ VCSEC_frunkRequest: 34|2@1+ (1,0) [0|0] "" X
 SG_ VCSEC_immobilizerState: 48|3@1+ (1,0) [0|0] "" X
 SG_ VCSEC_keyChannelIndexed: 56|4@1+ (1,0) [0|0] "" X
 SG_ VCSEC_leftFrontLockStatus: 19|1@1+ (1,0) [0|0] "" X
 SG_ VCSEC_leftRearLockStatus: 20|1@1+ (1,0) [0|0] "" X
 SG_ VCSEC_lockIndicationRequest: 51|3@1+ (1,0) [0|0] "" X
 SG_ VCSEC_lockRequestType: 24|5@1+ (1,0) [0|0] "" X
 SG_ VCSEC_numberOfPubKeysOnWhitelist: 6|5@1+ (1,0) [0|0] "" X
 SG_ VCSEC_prsntRsnDeltaD: 3|1@1+ (1,0) [0|0] "" X
 SG_ VCSEC_prsntRsnDeltaP: 39|1@1+ (1,0) [0|0] "" X
 SG_ VCSEC_prsntRsnDeltaR: 4|1@1+ (1,0) [0|0] "" X
 SG_ VCSEC_prsntRsnHighThresholdC: 0|1@1+ (1,0) [0|0] "" X
 SG_ VCSEC_prsntRsnHighThresholdD: 1|1@1+ (1,0) [0|0] "" X
 SG_ VCSEC_prsntRsnHighThresholdP: 2|1@1+ (1,0) [0|0] "" X
 SG_ VCSEC_prsntRsnHighThresholdR: 5|1@1+ (1,0) [0|0] "" X
 SG_ VCSEC_rightFrontLockStatus: 21|1@1+ (1,0) [0|0] "" X
 SG_ VCSEC_rightRearLockStatus: 22|1@1+ (1,0) [0|0] "" X
 SG_ VCSEC_simpleLockStatus: 54|2@1+ (1,0) [0|0] "" X
 SG_ VCSEC_summonRequest: 29|3@1+ (1,0) [0|0] "" X
 SG_ VCSEC_trunkLockStatus: 23|1@1+ (1,0) [0|0] "" X
 SG_ VCSEC_trunkRequest: 32|2@1+ (1,0) [0|0] "" X
 SG_ VCSEC_usingModifiedMACAddress: 40|1@1+ (1,0) [0|0] "" X
 SG_ VCSEC_vehicleLockStatus: 12|4@1+ (1,0) [0|0] "" X

BO_ 793 VCSEC_info: 8 Vector__XXX
 SG_ VCSEC_infoComponentId m10 : 48|16@1+ (1,0) [0|0] "" Vector__XXX
 SG_ VCSEC_infoSubUsageId m11 : 48|16@1+ (1,0) [0|0] "" Vector__XXX
 SG_ VCSEC_infoAppCrc m13 : 32|32@1+ (1,0) [0|0] "" Vector__XXX
 SG_ VCSEC_infoHardwareId m10 : 32|16@1+ (1,0) [0|0] "" Vector__XXX
 SG_ VCSEC_infoSubcomponent1 m16 : 32|32@1+ (1,0) [0|0] "" Vector__XXX
 SG_ VCSEC_infoSubcomponent10 m37 : 32|32@1+ (1,0) [0|0] "" Vector__XXX
 SG_ VCSEC_infoSubcomponent11 m38 : 32|32@1+ (1,0) [0|0] "" Vector__XXX
 SG_ VCSEC_infoSubcomponent12 m39 : 32|32@1+ (1,0) [0|0] "" Vector__XXX
 SG_ VCSEC_infoSubcomponent13 m40 : 32|32@1+ (1,0) [0|0] "" Vector__XXX
 SG_ VCSEC_infoSubcomponent14 m41 : 32|32@1+ (1,0) [0|0] "" Vector__XXX
 SG_ VCSEC_infoSubcomponent2 m23 : 32|32@1+ (1,0) [0|0] "" Vector__XXX
 SG_ VCSEC_infoSubcomponent3 m24 : 32|32@1+ (1,0) [0|0] "" Vector__XXX
 SG_ VCSEC_infoSubcomponent4 m31 : 32|32@1+ (1,0) [0|0] "" Vector__XXX
 SG_ VCSEC_infoSubcomponent5 m32 : 32|32@1+ (1,0) [0|0] "" Vector__XXX
 SG_ VCSEC_infoSubcomponent6 m33 : 32|32@1+ (1,0) [0|0] "" Vector__XXX
 SG_ VCSEC_infoSubcomponent7 m34 : 32|32@1+ (1,0) [0|0] "" Vector__XXX
 SG_ VCSEC_infoSubcomponent8 m35 : 32|32@1+ (1,0) [0|0] "" Vector__XXX
 SG_ VCSEC_infoSubcomponent9 m36 : 32|32@1+ (1,0) [0|0] "" Vector__XXX
 SG_ VCSEC_infoUsageId m11 : 32|16@1+ (1,0) [0|0] "" Vector__XXX
 SG_ VCSEC_infoBootCrc m20 : 24|32@1+ (1,0) [0|0] "" Vector__XXX
 SG_ VCSEC_infoAssemblyId m11 : 16|8@1+ (1,0) [0|0] "" Vector__XXX
 SG_ VCSEC_infoBuildConfigId m10 : 16|16@1+ (1,0) [0|0] "" Vector__XXX
 SG_ VCSEC_infoAppGitHash m17 : 8|56@1+ (1,0) [0|0] "" Vector__XXX
 SG_ VCSEC_infoBootGitHash m18 : 8|56@1+ (1,0) [0|0] "" Vector__XXX
 SG_ VCSEC_infoBootUdsProtoVersion m20 : 8|16@1+ (1,0) [0|0] "" Vector__XXX
 SG_ VCSEC_infoBuildType m10 : 8|3@1+ (1,0) [0|0] "" Vector__XXX
 SG_ VCSEC_infoPcbaId m11 : 8|8@1+ (1,0) [0|0] "" Vector__XXX
 SG_ VCSEC_infoPlatformType m19 : 8|8@1+ (1,0) [0|0] "" Vector__XXX
 SG_ VCSEC_infoIndex M : 0|8@1+ (1,0) [0|0] "" Vector__XXX

BO_ 505 VCSEC_requests: 8 Vector__XXX
 SG_ VCSEC_frontTrunkRequestReason : 54|3@1+ (1,0) [0|0] "" Vector__XXX
 SG_ VCSEC_frontTrunkClosureRequest : 51|3@1+ (1,0) [0|0] "" Vector__XXX
 SG_ VCSEC_chargeportRequestReason : 47|3@1+ (1,0) [0|0] "" Vector__XXX
 SG_ VCSEC_snapshotRequested : 43|4@1+ (1,0) [0|0] "" Vector__XXX
 SG_ VCSEC_closeAllStatus : 41|2@1+ (1,0) [0|0] "" Vector__XXX
 SG_ VCSEC_driveAttemptedWithoutAuth : 36|4@1+ (1,0) [0|0] "" Vector__XXX
 SG_ VCSEC_rdMapDumpRequested : 35|1@1+ (1,0) [0|0] "" Vector__XXX
 SG_ VCSEC_rearTrunkRequestReason : 32|3@1+ (1,0) [0|0] "" Vector__XXX
 SG_ VCSEC_rearRightRequestReason : 29|3@1+ (1,0) [0|0] "" Vector__XXX
 SG_ VCSEC_rearLeftRequestReason : 26|3@1+ (1,0) [0|0] "" Vector__XXX
 SG_ VCSEC_frontRightRequestReason : 23|3@1+ (1,0) [0|0] "" Vector__XXX
 SG_ VCSEC_frontLeftRequestReason : 20|3@1+ (1,0) [0|0] "" Vector__XXX
 SG_ VCSEC_rearTrunkClosureRequest : 17|3@1+ (1,0) [0|0] "" Vector__XXX
 SG_ VCSEC_rearRightClosureRequest : 14|3@1+ (1,0) [0|0] "" Vector__XXX
 SG_ VCSEC_rearLeftClosureRequest : 11|3@1+ (1,0) [0|0] "" Vector__XXX
 SG_ VCSEC_frontRightClosureRequest : 8|3@1+ (1,0) [0|0] "" Vector__XXX
 SG_ VCSEC_frontLeftClosureRequest : 5|3@1+ (1,0) [0|0] "" Vector__XXX
 SG_ VCSEC_presentHandles : 4|1@1+ (1,0) [0|0] "" Vector__XXX
 SG_ VCSEC_chargePortRequest : 0|2@1+ (1,0) [0|0] "" Vector__XXX

BO_ 1657 UI_ambientLightingCtrls: 8 VEH
 SG_ UI_ambientLightingRed : 8|8@1+ (1,0) [0|255] "" X
 SG_ UI_ambientLightingGreen : 16|8@1+ (1,0) [0|255] "" X
 SG_ UI_ambientLightingBlue : 24|8@1+ (1,0) [0|255] "" X
 SG_ UI_ambientLightingBrightness : 32|7@1+ (1,0) [0|100] "%" X

BA_DEF_ BO_ "GenMsgSendType" ENUM "Cyclic";
BA_DEF_ BO_ "GenMsgCycleTime" INT 0 10000;

BA_ "GenMsgSendType" BO_ 691 0;
BA_ "GenMsgCycleTime" BO_ 691 90;

BA_ "GenMsgSendType" BO_ 1859 0;
BA_ "GenMsgCycleTime" BO_ 1859 1000;

BA_ "GenMsgSendType" BO_ 794 0;
BA_ "GenMsgCycleTime" BO_ 794 50;

BA_ "GenMsgSendType" BO_ 1251 0;
BA_ "GenMsgCycleTime" BO_ 1251 100;

BA_ "GenMsgSendType" BO_ 899 0;
BA_ "GenMsgCycleTime" BO_ 899 100;

BA_ "GenMsgSendType" BO_ 857 0;
BA_ "GenMsgCycleTime" BO_ 857 100;

BA_ "GenMsgSendType" BO_ 969 0;
BA_ "GenMsgCycleTime" BO_ 969 1000;

BA_ "GenMsgSendType" BO_ 1017 0;
BA_ "GenMsgCycleTime" BO_ 1017 100;

BA_ "GenMsgSendType" BO_ 825 0;
BA_ "GenMsgCycleTime" BO_ 825 100;

BA_ "GenMsgSendType" BO_ 793 0;
BA_ "GenMsgCycleTime" BO_ 793 1000;

BA_ "GenMsgSendType" BO_ 505 0;
BA_ "GenMsgCycleTime" BO_ 505 100;

VAL_ 691 VCRIGHT_logging1HzIndex 0 "HVAC_TEMP_SENSORS_AND_ESTIMATES_1" 1 "HVAC_TEMP_SENSORS_AND_ESTIMATES_2" 2 "HVAC_HUMIDITY_HEATER" 3 "HVAC_STATUS_AIRFLOW" 4 "HVAC_COMFORT_SOLAR" 5 "HEATER_AND_DUCT_TARGETS" 6 "HVAC_ACTUATOR_VOLTAGES" 7 "HVAC_ACTUATOR_ENDSTOP" 8 "HVAC_ACTUATOR_ZEROSTOP" 9 "HVAC_MISCELLANEOUS_1" 10 "HVAC_MISCELLANEOUS_2" 11 "END";
VAL_ 691 VCRIGHT_tempIncarCabinProbe 255 "SNA";
VAL_ 691 VCRIGHT_tempIncarCabinMid 250 "SNA";
VAL_ 691 VCRIGHT_tempIncarCabinDeep 255 "SNA";
VAL_ 691 VCRIGHT_cabinTempInteriorL2 240 "SNA";
VAL_ 691 VCRIGHT_cabinTempInteriorSunnyL2 240 "SNA";
VAL_ 691 VCRIGHT_cabinTempGlassRoof 255 "SNA";
VAL_ 691 VCRIGHT_cabinTempWindshield 255 "SNA";
VAL_ 691 VCRIGHT_cabinTempInterior 240 "SNA";
VAL_ 691 VCRIGHT_cabinTempInteriorSunny 240 "SNA";
VAL_ 691 VCRIGHT_cabinTempSideGlassLeft 255 "SNA";
VAL_ 691 VCRIGHT_cabinTempSideGlassRight 255 "SNA";
VAL_ 691 VCRIGHT_cabinTempBreathLevel 255 "SNA";
VAL_ 691 VCRIGHT_hvacAutoTransitionReason 0 "NONE" 1 "HUMIDITY_HIGH" 2 "HUMIDITY_MODERATE" 3 "HUMIDITY_LOW" 4 "TEMP_TARGET_BELOW_THRESHOLD" 5 "TEMP_TARGET_ABOVE_THRESHOLD" 6 "EXCESS_OCCUPANT_CONVECTION" 7 "OCCUPANT_CONVECTION_REQUIREMENT" 8 "TEMP_TARGET_LOW" 9 "DUCTS_COLD" 10 "BI_LEVEL_LANDING" 11 "DEFOG_OVERRIDE" 12 "SET_TEMP_LO" 13 "SET_TEMP_HI" 14 "CABIN_PURGE" 15 "EVAP_DRYING" 16 "HVAC_OFF" 17 "END";
VAL_ 691 VCRIGHT_hvacAirFlowModeRow1 0 "NONE" 1 "FLOOR" 2 "PANEL" 3 "PANEL_FLOOR" 4 "DEFROST" 5 "DEFROST_FLOOR" 6 "DEFROST_PANEL" 7 "DEFROST_PANEL_FLOOR";
VAL_ 691 VCRIGHT_hvacAirFlowModeRow2 0 "NONE" 1 "FLOOR" 2 "PANEL" 3 "PANEL_FLOOR" 4 "DEFROST" 5 "DEFROST_FLOOR" 6 "DEFROST_PANEL" 7 "DEFROST_PANEL_FLOOR";
VAL_ 691 VCRIGHT_hvacAirflowReason 0 "HVAC_OFF" 1 "MANUAL_FAN_SPEED" 2 "UI_SHORTCUT" 3 "CABIN_TEMPERATURE_CONTROL" 4 "MINIMUM_AUTO_AIRFLOW" 5 "STRATIFICATION_GLASS_ROOF" 6 "STRATIFICATION_INTERIOR_SURFACES" 7 "OCCUPANT_CONVECTION_REQUIREMENT" 8 "COLD_DUCT_LOCKOUT" 9 "CABIN_PURGE" 10 "CABIN_OVERHEAT_PROTECT" 11 "SCREEN_PROTECTION" 12 "EVAP_DRYING" 13 "NONE";
VAL_ 691 VCRIGHT_convectionTargetLeft 255 "SNA";
VAL_ 691 VCRIGHT_convectionTargetRight 255 "SNA";
VAL_ 691 VCRIGHT_convectionDeliveredLeft 255 "SNA";
VAL_ 691 VCRIGHT_convectionDeliveredRight 255 "SNA";
VAL_ 691 VCRIGHT_solarLoadRightOccupant 255 "SNA";
VAL_ 691 VCRIGHT_solarLoadLeftOccupant 255 "SNA";
VAL_ 691 VCRIGHT_solarLoadOnVehicle 255 "SNA";
VAL_ 691 VCRIGHT_solarLoadOnVehFiltered 255 "SNA";
VAL_ 691 VCRIGHT_cabinTempInteriorL3 240 "SNA";
VAL_ 691 VCRIGHT_cabinTempInteriorSunnyL3 240 "SNA";
VAL_ 691 VCRIGHT_cabinTempTopPadAir 240 "SNA";
VAL_ 691 VCRIGHT_tempDuctModeledLeft 511 "SNA";
VAL_ 691 VCRIGHT_tempDuctModeledRight 511 "SNA";
VAL_ 691 VCRIGHT_tempHtrSurfaceModeledL 511 "SNA";
VAL_ 691 VCRIGHT_tempHtrSurfaceModeledR 511 "SNA";

VAL_ 1859 VCRIGHT_mirrorRecallStatus 0 "SNA" 1 "IN_PROGRESS" 2 "COMPLETE" 3 "INTERRUPTED";
VAL_ 1859 VCRIGHT_seatRecallStatus 0 "SNA" 1 "IN_PROGRESS" 2 "COMPLETE" 3 "INTERRUPTED";
VAL_ 1859 VCRIGHT_systemRecallStatus 0 "SNA" 1 "IN_PROGRESS" 2 "COMPLETE" 3 "INTERRUPTED";

VAL_ 857 VCSEC_BLEConnectionStatus 0 "NOT_CONNECTED" 1 "CONNECTED" 2 "WRITE" 3 "NOTIFICATION" 4 "READ" 5 "UPDATE_SPEED";
VAL_ 857 VCSEC_BLEDeviceLocation 0 "NOT_PRESENT" 1 "CONNECTION_RANGE" 2 "AUTHENTICATION_RANGE";
VAL_ 857 VCSEC_BLEDevicePairingStatus 0 "IDLE" 1 "STEP1" 2 "STEP2" 3 "STEP3" 4 "SUCCESS" 5 "FAILURE";
VAL_ 857 VCSEC_BLEDeviceType 0 "UNKNOWN" 1 "ANDROID" 2 "IOS" 3 "OTHER";

VAL_ 1017 VCSEC_matrixIndex 0 "AlertMatrix0" 1 "AlertMatrix1" 2 "AlertMatrix2" 3 "AlertMatrix3";

VAL_ 825 VCSEC_MCUCommandType 0 "NONE" 1 "REMOTE_UNLOCK" 2 "REMOTE_START" 3 "COMMAND3" 4 "COMMAND4" 5 "COMMAND5";
VAL_ 825 VCSEC_alarmStatus 0 "DISARMED" 1 "ARMED" 2 "PARTIAL_ARMED" 3 "TRIGGERED_FLASH_ACTIVE" 4 "ERROR" 5 "TRIGGERED_FLASH_INACTIVE" 6 "IMMINENT" 7 "DEFAULT" 15 "SNA";
VAL_ 825 VCSEC_authenticationStatus 0 "NONE" 1 "AUTHENTICATED_FOR_UNLOCK" 2 "AUTHENTICATED_FOR_DRIVE";
VAL_ 825 VCSEC_chargePortLockStatus 0 "UNLOCKED" 1 "LOCKED";
VAL_ 825 VCSEC_frunkRequest 0 "NONE" 1 "OPEN" 2 "SNA";
VAL_ 825 VCSEC_immobilizerState 0 "IDLE" 1 "PREPARE" 2 "ENCRYPT_BEGIN" 3 "ENCRYPT" 4 "SEND_AUTH_RESPONSE" 5 "SEND_NO_GO_AUTH_RESPONSE";
VAL_ 825 VCSEC_keyChannelIndexed 15 "SNA";
VAL_ 825 VCSEC_leftFrontLockStatus 0 "UNLOCKED" 1 "LOCKED";
VAL_ 825 VCSEC_leftRearLockStatus 0 "UNLOCKED" 1 "LOCKED";
VAL_ 825 VCSEC_lockIndicationRequest 0 "NONE_SNA" 1 "SINGLE" 2 "DOUBLE" 3 "TRIPLE" 4 "HOLD";
VAL_ 825 VCSEC_lockRequestType 0 "NONE" 1 "PASSIVE_SHIFT_TO_P_UNLOCK" 2 "PASSIVE_PARKBUTTON_UNLOCK" 3 "PASSIVE_INTERNAL_HANDLE_UNLOCK" 4 "PASSIVE_DRIVE_AWAY_LOCK" 5 "PASSIVE_BLE_WALKUP_UNLOCK" 6 "PASSIVE_BLE_EXTERIOR_CHARGEHANDLEBUTTON_UNLOCK" 7 "PASSIVE_BLE_EXTERIOR_HANDLE_UNLOCK" 8 "PASSIVE_BLE_INTERIOR_HANDLE_UNLOCK" 9 "PASSIVE_BLE_LOCK" 10 "CRASH_UNLOCK" 11 "ACTIVE_UI_BUTTON_UNLOCK" 12 "ACTIVE_UI_BUTTON_LOCK" 13 "ACTIVE_REMOTE_UNLOCK" 14 "ACTIVE_REMOTE_LOCK" 15 "ACTIVE_NFC_UNLOCK" 16 "ACTIVE_NFC_LOCK" 17 "ACTIVE_BLE_UNLOCK" 18 "ACTIVE_BLE_LOCK" 19 "PASSIVE_INTERNAL_LOCK_PROMOTION";
VAL_ 825 VCSEC_rightFrontLockStatus 0 "UNLOCKED" 1 "LOCKED";
VAL_ 825 VCSEC_rightRearLockStatus 0 "UNLOCKED" 1 "LOCKED";
VAL_ 825 VCSEC_simpleLockStatus 0 "SNA" 1 "UNLOCKED" 2 "LOCKED";
VAL_ 825 VCSEC_summonRequest 0 "IDLE" 1 "PRIME" 2 "FORWARD" 3 "BACKWARD" 4 "STOP" 5 "SNA";
VAL_ 825 VCSEC_trunkLockStatus 0 "UNLOCKED" 1 "LOCKED";
VAL_ 825 VCSEC_trunkRequest 0 "NONE" 1 "OPEN" 2 "SNA";
VAL_ 825 VCSEC_vehicleLockStatus 0 "SNA" 1 "ACTIVE_NFC_UNLOCKED" 2 "ACTIVE_NFC_LOCKED" 3 "PASSIVE_SELECTIVE_UNLOCKED" 4 "PASSIVE_BLE_UNLOCKED" 5 "PASSIVE_BLE_LOCKED" 6 "ACTIVE_SELECTIVE_UNLOCKED" 7 "ACTIVE_BLE_UNLOCKED" 8 "ACTIVE_BLE_LOCKED" 9 "ACTIVE_UI_UNLOCKED" 10 "ACTIVE_UI_LOCKED" 11 "ACTIVE_REMOTE_UNLOCKED" 12 "ACTIVE_REMOTE_LOCKED" 13 "CRASH_UNLOCKED" 14 "PASSIVE_INTERNAL_UNLOCKED" 15 "PASSIVE_INTERNAL_LOCKED";

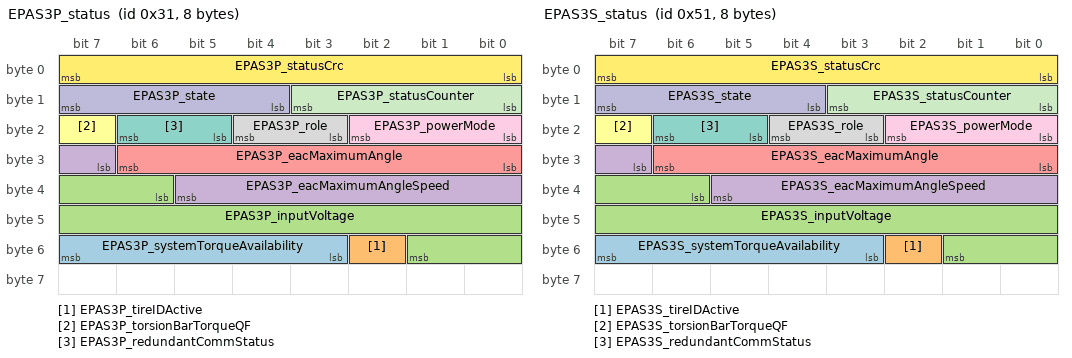
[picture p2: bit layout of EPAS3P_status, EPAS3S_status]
BO_ 49 EPAS3P_status: 8 Vector__XXX
 SG_ EPAS3P_systemTorqueAvailability : 51|5@1+ (5,0) [0|0] "" Vector__XXX
 SG_ EPAS3P_tireIDActive : 50|1@1+ (1,0) [0|0] "" Vector__XXX
 SG_ EPAS3P_inputVoltage : 38|12@1+ (0.0073,0) [0|0] "" Vector__XXX
 SG_ EPAS3P_eacMaximumAngleSpeed : 31|7@1+ (10,0) [0|0] "" Vector__XXX
 SG_ EPAS3P_eacMaximumAngle : 24|7@1+ (10,0) [0|0] "" Vector__XXX
 SG_ EPAS3P_torsionBarTorqueQF : 23|1@1+ (1,0) [0|0] "" Vector__XXX
 SG_ EPAS3P_redundantCommStatus : 21|2@1+ (1,0) [0|0] "" Vector__XXX
 SG_ EPAS3P_role : 19|2@1+ (1,0) [0|0] "" Vector__XXX
 SG_ EPAS3P_powerMode : 16|3@1+ (1,0) [0|0] "" Vector__XXX
 SG_ EPAS3P_state : 12|4@1+ (1,0) [0|0] "" Vector__XXX
 SG_ EPAS3P_statusCounter : 8|4@1+ (1,0) [0|0] "" Vector__XXX
 SG_ EPAS3P_statusCrc : 0|8@1+ (1,0) [0|0] "" Vector__XXX

BO_ 81 EPAS3S_status: 8 Vector__XXX
 SG_ EPAS3S_systemTorqueAvailability : 51|5@1+ (5,0) [0|0] "" Vector__XXX
 SG_ EPAS3S_tireIDActive : 50|1@1+ (1,0) [0|0] "" Vector__XXX
 SG_ EPAS3S_inputVoltage : 38|12@1+ (0.0073,0) [0|0] "" Vector__XXX
 SG_ EPAS3S_eacMaximumAngleSpeed : 31|7@1+ (10,0) [0|0] "" Vector__XXX
 SG_ EPAS3S_eacMaximumAngle : 24|7@1+ (10,0) [0|0] "" Vector__XXX
 SG_ EPAS3S_torsionBarTorqueQF : 23|1@1+ (1,0) [0|0] "" Vector__XXX
 SG_ EPAS3S_redundantCommStatus : 21|2@1+ (1,0) [0|0] "" Vector__XXX
 SG_ EPAS3S_role : 19|2@1+ (1,0) [0|0] "" Vector__XXX
 SG_ EPAS3S_powerMode : 16|3@1+ (1,0) [0|0] "" Vector__XXX
 SG_ EPAS3S_state : 12|4@1+ (1,0) [0|0] "" Vector__XXX
 SG_ EPAS3S_statusCounter : 8|4@1+ (1,0) [0|0] "" Vector__XXX
 SG_ EPAS3S_statusCrc : 0|8@1+ (1,0) [0|0] "" Vector__XXX

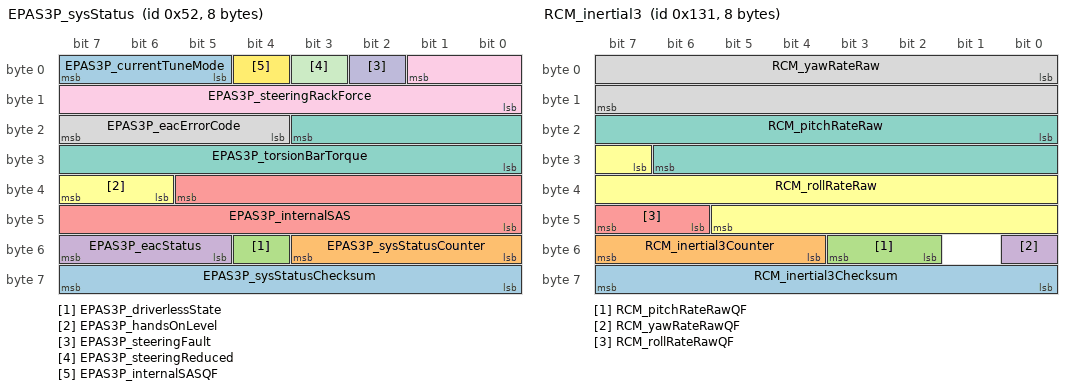
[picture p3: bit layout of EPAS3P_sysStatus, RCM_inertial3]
BO_ 82 EPAS3P_sysStatus: 8 Vector__XXX
 SG_ EPAS3P_sysStatusChecksum : 63|8@0+ (1,0) [0|0] "" Vector__XXX
 SG_ EPAS3P_sysStatusCounter : 51|4@0+ (1,0) [0|0] "" Vector__XXX
 SG_ EPAS3P_driverlessState : 52|1@0+ (1,0) [0|0] "" Vector__XXX
 SG_ EPAS3P_eacStatus : 55|3@0+ (1,0) [0|0] "" Vector__XXX
 SG_ EPAS3P_internalSAS : 37|14@0+ (0.1,-819.2) [0|0] "" Vector__XXX
 SG_ EPAS3P_handsOnLevel : 39|2@0+ (1,0) [0|0] "" Vector__XXX
 SG_ EPAS3P_torsionBarTorque : 19|12@0+ (0.01,-20.5) [0|0] "" Vector__XXX
 SG_ EPAS3P_eacErrorCode : 23|4@0+ (1,0) [0|0] "" Vector__XXX
 SG_ EPAS3P_steeringRackForce : 1|10@0+ (50,-25575) [0|0] "" Vector__XXX
 SG_ EPAS3P_steeringFault : 2|1@0+ (1,0) [0|0] "" Vector__XXX
 SG_ EPAS3P_steeringReduced : 3|1@0+ (1,0) [0|0] "" Vector__XXX
 SG_ EPAS3P_internalSASQF : 4|1@0+ (1,0) [0|0] "" Vector__XXX
 SG_ EPAS3P_currentTuneMode : 7|3@0+ (1,0) [0|0] "" Vector__XXX

BO_ 290 VCLEFT_doorStatus2: 8 Vector__XXX
 SG_ VCLEFT_mirrorTiltYOffset m1 : 56|8@1- (0.02,0) [0|0] "" Vector__XXX
 SG_ VCLEFT_rearHandlePWM m0 : 56|7@1+ (1,0) [0|0] "" Vector__XXX
 SG_ VCLEFT_frontHandlePWM m0 : 48|7@1+ (1,0) [0|0] "" Vector__XXX
 SG_ VCLEFT_mirrorTiltXOffset m1 : 48|8@1- (0.02,0) [0|0] "" Vector__XXX
 SG_ VCLEFT_mirrorDimmed m0 : 47|1@1+ (1,0) [0|0] "" Vector__XXX
 SG_ VCLEFT_BPillarCameraHeaterCurrent m1 : 40|6@1+ (0.02,0) [0|0] "" Vector__XXX
 SG_ VCLEFT_mirrorFoldCurrent m0 : 40|7@1- (0.05,0) [0|0] "" Vector__XXX
 SG_ VCLEFT_rearHandle5vEnable m0 : 39|1@1+ (1,0) [0|0] "" Vector__XXX
 SG_ VCLEFT_frontHandle5vEnable m0 : 38|1@1+ (1,0) [0|0] "" Vector__XXX
 SG_ VCLEFT_rearHandleDebounceStatus m0 : 35|3@1+ (1,0) [0|0] "" Vector__XXX
 SG_ VCLEFT_frontHandleDebounceStatus m0 : 32|3@1+ (1,0) [0|0] "" Vector__XXX
 SG_ VCLEFT_mirrorFoldType m0 : 30|2@1+ (1,0) [0|0] "" Vector__XXX
 SG_ VCLEFT_rearHandleRawStatus m0 : 27|3@1+ (1,0) [0|0] "" Vector__XXX
 SG_ VCLEFT_frontHandleRawStatus m0 : 24|3@1+ (1,0) [0|0] "" Vector__XXX
 SG_ VCLEFT_rearDoorState m0 : 20|3@1+ (1,0) [0|0] "" Vector__XXX
 SG_ VCLEFT_frontDoorState m0 : 17|3@1+ (1,0) [0|0] "" Vector__XXX
 SG_ VCLEFT_BPillarCameraHeaterState m1 : 16|3@1+ (1,0) [0|0] "" Vector__XXX
 SG_ VCLEFT_vehicleInMotion m0 : 16|1@1+ (1,0) [0|0] "" Vector__XXX
 SG_ VCLEFT_frontLatchRelDuty m1 : 8|8@1+ (1,0) [0|0] "" Vector__XXX
 SG_ VCLEFT_rearLatchRelDuty m0 : 8|8@1+ (1,0) [0|0] "" Vector__XXX
 SG_ VCLEFT_doorStatus2Index M : 0|1@1+ (1,0) [0|0] "" Vector__XXX

BO_ 296 DI_systemLimits: 6 Vector__XXX
 SG_ DI_immobilizerAuthLevel : 33|2@1+ (1,0) [0|0] "" Vector__XXX
 SG_ DI_undersideAbuse : 32|1@1+ (1,0) [0|0] "" Vector__XXX
 SG_ DI_limitClosureNotClosed : 31|1@1+ (1,0) [0|0] "" Vector__XXX
 SG_ DI_proximity : 30|1@1+ (1,0) [0|0] "" Vector__XXX
 SG_ DI_vehicleSpeedLimitReason : 25|5@1+ (1,0) [0|0] "" Vector__XXX
 SG_ DI_vehicleSpeedLimit : 16|9@1+ (1,0) [0|0] "" Vector__XXX
 SG_ DI_vehicleSpeedLimitType : 14|2@1+ (1,0) [0|0] "" Vector__XXX
 SG_ DI_limitCdp : 13|1@1+ (1,0) [0|0] "" Vector__XXX
 SG_ DI_limitSystemSpinDownLearning : 12|1@1+ (1,0) [0|0] "" Vector__XXX
 SG_ DI_limitBmsMiaFreeze : 11|1@1+ (1,0) [0|0] "" Vector__XXX
 SG_ DI_limitVehicleSpeed : 10|1@1+ (1,0) [0|0] "" Vector__XXX
 SG_ DI_limitRegenTorque : 9|1@1+ (1,0) [0|0] "" Vector__XXX
 SG_ DI_limitDriveTorque : 8|1@1+ (1,0) [0|0] "" Vector__XXX
 SG_ DI_limitShift : 7|1@1+ (1,0) [0|0] "" Vector__XXX
 SG_ DI_limitSystemGPO : 6|1@1+ (1,0) [0|0] "" Vector__XXX
 SG_ DI_limitSystemLimp : 5|1@1+ (1,0) [0|0] "" Vector__XXX
 SG_ DI_limitObstacleDetection : 4|1@1+ (1,0) [0|0] "" Vector__XXX
 SG_ DI_limitVBatHigh : 3|1@1+ (1,0) [0|0] "" Vector__XXX
 SG_ DI_limitVBatLow : 2|1@1+ (1,0) [0|0] "" Vector__XXX
 SG_ DI_limitIBat : 1|1@1+ (1,0) [0|0] "" Vector__XXX
 SG_ DI_limitRegenPower : 0|1@1+ (1,0) [0|0] "" Vector__XXX

BO_ 305 RCM_inertial3: 8 Vector__XXX
 SG_ RCM_inertial3Checksum : 56|8@1+ (1,0) [0|0] "" Vector__XXX
 SG_ RCM_inertial3Counter : 52|4@1+ (1,0) [0|0] "" Vector__XXX
 SG_ RCM_pitchRateRawQF : 50|2@1+ (1,0) [0|0] "" Vector__XXX
 SG_ RCM_yawRateRawQF : 48|1@1+ (1,0) [0|0] "" Vector__XXX
 SG_ RCM_rollRateRawQF : 46|2@1+ (1,0) [0|0] "" Vector__XXX
 SG_ RCM_rollRateRaw : 31|15@1- (0.00025,0) [0|0] "" Vector__XXX
 SG_ RCM_pitchRateRaw : 16|15@1- (0.00025,0) [0|0] "" Vector__XXX
 SG_ RCM_yawRateRaw : 0|16@1- (0.0001,0) [0|0] "" Vector__XXX

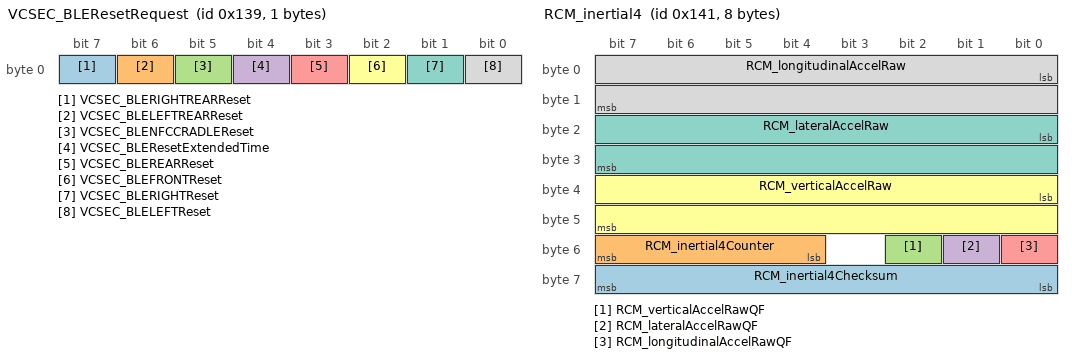
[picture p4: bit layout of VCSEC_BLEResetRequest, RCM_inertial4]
BO_ 313 VCSEC_BLEResetRequest: 1 Vector__XXX
 SG_ VCSEC_BLERIGHTREARReset : 7|1@1+ (1,0) [0|0] "" Vector__XXX
 SG_ VCSEC_BLELEFTREARReset : 6|1@1+ (1,0) [0|0] "" Vector__XXX
 SG_ VCSEC_BLENFCCRADLEReset : 5|1@1+ (1,0) [0|0] "" Vector__XXX
 SG_ VCSEC_BLEResetExtendedTime : 4|1@1+ (1,0) [0|0] "" Vector__XXX
 SG_ VCSEC_BLEREARReset : 3|1@1+ (1,0) [0|0] "" Vector__XXX
 SG_ VCSEC_BLEFRONTReset : 2|1@1+ (1,0) [0|0] "" Vector__XXX
 SG_ VCSEC_BLERIGHTReset : 1|1@1+ (1,0) [0|0] "" Vector__XXX
 SG_ VCSEC_BLELEFTReset : 0|1@1+ (1,0) [0|0] "" Vector__XXX

BO_ 321 RCM_inertial4: 8 Vector__XXX
 SG_ RCM_inertial4Checksum : 56|8@1+ (1,0) [0|0] "" Vector__XXX
 SG_ RCM_inertial4Counter : 52|4@1+ (1,0) [0|0] "" Vector__XXX
 SG_ RCM_verticalAccelRawQF : 50|1@1+ (1,0) [0|0] "" Vector__XXX
 SG_ RCM_lateralAccelRawQF : 49|1@1+ (1,0) [0|0] "" Vector__XXX
 SG_ RCM_longitudinalAccelRawQF : 48|1@1+ (1,0) [0|0] "" Vector__XXX
 SG_ RCM_verticalAccelRaw : 32|16@1- (0.00125,0) [0|0] "" Vector__XXX
 SG_ RCM_lateralAccelRaw : 16|16@1- (0.00125,0) [0|0] "" Vector__XXX
 SG_ RCM_longitudinalAccelRaw : 0|16@1- (0.00125,0) [0|0] "" Vector__XXX

BO_ 326 ESP_redundantBrakingStatus: 8 Vector__XXX
 SG_ ESP_longitudinalStabilityControlAvailable : 15|1@1+ (1,0) [0|0] "" Vector__XXX
 SG_ ESP_redundantBrakingSystemStatus : 12|3@1+ (1,0) [0|0] "" Vector__XXX
 SG_ ESP_redundantBrakingStatusCounter : 8|4@1+ (1,0) [0|0] "" Vector__XXX
 SG_ ESP_redundantBrakingStatusChecksum : 0|8@1+ (1,0) [0|0] "" Vector__XXX

BO_ 329 IBST_redundantBrakingStatus: 8 Vector__XXX
 SG_ IBST_brakeTorqueTarget : 15|13@1+ (3,0) [0|0] "" Vector__XXX
 SG_ IBST_redundantBrakingSystemStatus : 12|3@1+ (1,0) [0|0] "" Vector__XXX
 SG_ IBST_redundantBrakingStatusCounter : 8|4@1+ (1,0) [0|0] "" Vector__XXX
 SG_ IBST_redundantBrakingStatusChecksum : 0|8@1+ (1,0) [0|0] "" Vector__XXX

BO_ 337 UNK_151: 8 Vector__XXX
 SG_ UNK_151_state : 48|2@1+ (1,0) [0|3] "" Vector__XXX

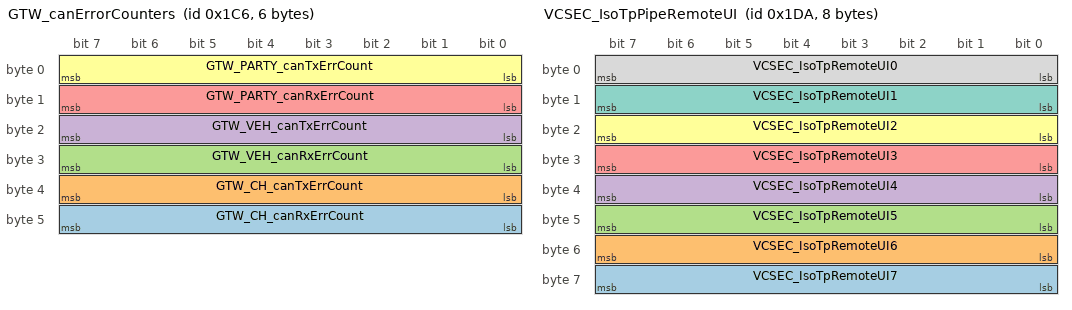
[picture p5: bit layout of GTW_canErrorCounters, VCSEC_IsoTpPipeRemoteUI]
BO_ 454 GTW_canErrorCounters: 6 Vector__XXX
 SG_ GTW_CH_canRxErrCount : 40|8@1+ (1,0) [0|0] "" Vector__XXX
 SG_ GTW_CH_canTxErrCount : 32|8@1+ (1,0) [0|0] "" Vector__XXX
 SG_ GTW_VEH_canRxErrCount : 24|8@1+ (1,0) [0|0] "" Vector__XXX
 SG_ GTW_VEH_canTxErrCount : 16|8@1+ (1,0) [0|0] "" Vector__XXX
 SG_ GTW_PARTY_canRxErrCount : 8|8@1+ (1,0) [0|0] "" Vector__XXX
 SG_ GTW_PARTY_canTxErrCount : 0|8@1+ (1,0) [0|0] "" Vector__XXX

BO_ 474 VCSEC_IsoTpPipeRemoteUI: 8 Vector__XXX
 SG_ VCSEC_IsoTpRemoteUI7 : 56|8@1+ (1,0) [0|0] "" Vector__XXX
 SG_ VCSEC_IsoTpRemoteUI6 : 48|8@1+ (1,0) [0|0] "" Vector__XXX
 SG_ VCSEC_IsoTpRemoteUI5 : 40|8@1+ (1,0) [0|0] "" Vector__XXX
 SG_ VCSEC_IsoTpRemoteUI4 : 32|8@1+ (1,0) [0|0] "" Vector__XXX
 SG_ VCSEC_IsoTpRemoteUI3 : 24|8@1+ (1,0) [0|0] "" Vector__XXX
 SG_ VCSEC_IsoTpRemoteUI2 : 16|8@1+ (1,0) [0|0] "" Vector__XXX
 SG_ VCSEC_IsoTpRemoteUI1 : 8|8@1+ (1,0) [0|0] "" Vector__XXX
 SG_ VCSEC_IsoTpRemoteUI0 : 0|8@1+ (1,0) [0|0] "" Vector__XXX

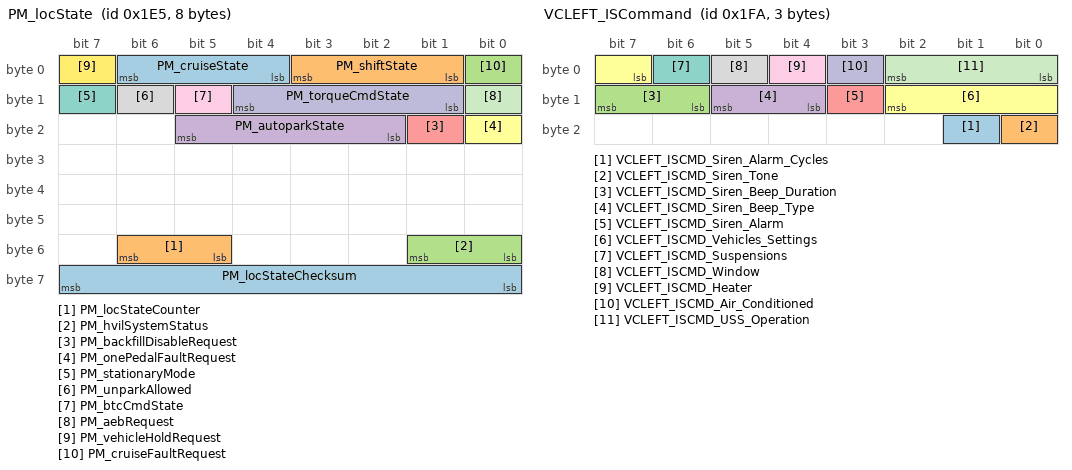
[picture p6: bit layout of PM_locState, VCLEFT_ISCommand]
BO_ 485 PM_locState: 8 Vector__XXX
 SG_ PM_locStateChecksum : 56|8@1+ (1,0) [0|0] "" Vector__XXX
 SG_ PM_locStateCounter : 53|2@1+ (1,0) [0|0] "" Vector__XXX
 SG_ PM_hvilSystemStatus : 48|2@1+ (1,0) [0|0] "" Vector__XXX
 SG_ PM_autoparkState : 18|4@1+ (1,0) [0|0] "" Vector__XXX
 SG_ PM_backfillDisableRequest : 17|1@1+ (1,0) [0|0] "" Vector__XXX
 SG_ PM_onePedalFaultRequest : 16|1@1+ (1,0) [0|0] "" Vector__XXX
 SG_ PM_stationaryMode : 15|1@1+ (1,0) [0|0] "" Vector__XXX
 SG_ PM_unparkAllowed : 14|1@1+ (1,0) [0|0] "" Vector__XXX
 SG_ PM_btcCmdState : 13|1@1+ (1,0) [0|0] "" Vector__XXX
 SG_ PM_torqueCmdState : 9|4@1+ (1,0) [0|0] "" Vector__XXX
 SG_ PM_aebRequest : 8|1@1+ (1,0) [0|0] "" Vector__XXX
 SG_ PM_vehicleHoldRequest : 7|1@1+ (1,0) [0|0] "" Vector__XXX
 SG_ PM_cruiseState : 4|3@1+ (1,0) [0|0] "" Vector__XXX
 SG_ PM_shiftState : 1|3@1+ (1,0) [0|0] "" Vector__XXX
 SG_ PM_cruiseFaultRequest : 0|1@1+ (1,0) [0|0] "" Vector__XXX

BO_ 504 VCLEFT_intrusionSensorStatus: 4 Vector__XXX
 SG_ VCLEFT_intrusionUltraTripped : 26|1@1+ (1,0) [0|0] "" Vector__XXX
 SG_ VCLEFT_intrusionTiltTripped : 25|1@1+ (1,0) [0|0] "" Vector__XXX
 SG_ VCLEFT_sirenMIA : 24|1@1+ (1,0) [0|0] "" Vector__XXX
 SG_ VCLEFT_DBG_System_Error : 23|1@1+ (1,0) [0|0] "" Vector__XXX
 SG_ VCLEFT_DBG_LM_SelfTest_Status : 22|1@1+ (1,0) [0|0] "" Vector__XXX
 SG_ VCLEFT_DBG_USS_SelfTest_Status : 21|1@1+ (1,0) [0|0] "" Vector__XXX
 SG_ VCLEFT_DBG_Eeprom_ST_Status : 20|1@1+ (1,0) [0|0] "" Vector__XXX
 SG_ VCLEFT_DBG_Reserved_08 : 19|1@1+ (1,0) [0|0] "" Vector__XXX
 SG_ VCLEFT_DBG_Reserved_07 : 18|1@1+ (1,0) [0|0] "" Vector__XXX
 SG_ VCLEFT_DBG_Siren_is_sounding : 17|1@1+ (1,0) [0|0] "" Vector__XXX
 SG_ VCLEFT_DBG_Invalid_Parameter : 16|1@1+ (1,0) [0|0] "" Vector__XXX
 SG_ VCLEFT_DBG_Siren_Int_Trigger : 15|1@1+ (1,0) [0|0] "" Vector__XXX
 SG_ VCLEFT_DBG_Siren_ST_Status : 14|1@1+ (1,0) [0|0] "" Vector__XXX
 SG_ VCLEFT_DBG_LM_Alarm_Status : 13|1@1+ (1,0) [0|0] "" Vector__XXX
 SG_ VCLEFT_DBG_USS_Alarm_Status : 12|1@1+ (1,0) [0|0] "" Vector__XXX
 SG_ VCLEFT_DBG_Veh_Settings_Status : 8|4@1+ (1,0) [0|0] "" Vector__XXX
 SG_ VCLEFT_DBG_SelfTest_Status : 7|1@1+ (1,0) [0|0] "" Vector__XXX
 SG_ VCLEFT_DBG_Suspensions_Status : 6|1@1+ (1,0) [0|0] "" Vector__XXX
 SG_ VCLEFT_DBG_Window_Status : 5|1@1+ (1,0) [0|0] "" Vector__XXX
 SG_ VCLEFT_DBG_Heater_Status : 4|1@1+ (1,0) [0|0] "" Vector__XXX
 SG_ VCLEFT_DBG_Air_Cond_Status : 3|1@1+ (1,0) [0|0] "" Vector__XXX
 SG_ VCLEFT_DBG_System_Status : 0|3@1+ (1,0) [0|0] "" Vector__XXX

BO_ 506 VCLEFT_ISCommand: 3 Vector__XXX
 SG_ VCLEFT_ISCMD_Siren_Alarm_Cycles : 17|1@1+ (1,0) [0|0] "" Vector__XXX
 SG_ VCLEFT_ISCMD_Siren_Tone : 16|1@1+ (1,0) [0|0] "" Vector__XXX
 SG_ VCLEFT_ISCMD_Siren_Beep_Duration : 14|2@1+ (1,0) [0|0] "" Vector__XXX
 SG_ VCLEFT_ISCMD_Siren_Beep_Type : 12|2@1+ (1,0) [0|0] "" Vector__XXX
 SG_ VCLEFT_ISCMD_Siren_Alarm : 11|1@1+ (1,0) [0|0] "" Vector__XXX
 SG_ VCLEFT_ISCMD_Vehicles_Settings : 7|4@1+ (1,0) [0|0] "" Vector__XXX
 SG_ VCLEFT_ISCMD_Suspensions : 6|1@1+ (1,0) [0|0] "" Vector__XXX
 SG_ VCLEFT_ISCMD_Window : 5|1@1+ (1,0) [0|0] "" Vector__XXX
 SG_ VCLEFT_ISCMD_Heater : 4|1@1+ (1,0) [0|0] "" Vector__XXX
 SG_ VCLEFT_ISCMD_Air_Conditioned : 3|1@1+ (1,0) [0|0] "" Vector__XXX
 SG_ VCLEFT_ISCMD_USS_Operation : 0|3@1+ (1,0) [0|0] "" Vector__XXX

BO_ 507 VCLEFT_TLCStatus: 8 Vector__XXX
 SG_ VCLEFT_TLCTotalCurrent m0 : 56|8@1+ (0.1,0) [0|0] "" Vector__XXX
 SG_ VCLEFT_TLCReverseCurrent m0 : 48|8@1+ (0.1,0) [0|0] "" Vector__XXX
 SG_ VCLEFT_TLCState_Reverse m1 : 41|3@1+ (1,0) [0|0] "" Vector__XXX
 SG_ VCLEFT_TLCFogCurrent m0 : 40|8@1+ (0.1,0) [0|0] "" Vector__XXX
 SG_ VCLEFT_TLCState_Fog m1 : 38|3@1+ (1,0) [0|0] "" Vector__XXX
 SG_ VCLEFT_TLCState_Stop m1 : 35|3@1+ (1,0) [0|0] "" Vector__XXX
 SG_ VCLEFT_TLCState_Tail m1 : 32|3@1+ (1,0) [0|0] "" Vector__XXX
 SG_ VCLEFT_TLCStopCurrent m0 : 32|8@1+ (0.1,0) [0|0] "" Vector__XXX
 SG_ VCLEFT_TLCState_RightTurn m1 : 29|3@1+ (1,0) [0|0] "" Vector__XXX
 SG_ VCLEFT_TLCState_LeftTurn m1 : 26|3@1+ (1,0) [0|0] "" Vector__XXX
 SG_ VCLEFT_TLCTailCurrent m0 : 24|8@1+ (0.1,0) [0|0] "" Vector__XXX
 SG_ VCLEFT_TLCRightTurnVoltage m1 : 18|8@1+ (0.1,0) [0|0] "" Vector__XXX
 SG_ VCLEFT_TLCRightTurnCurrent m0 : 16|8@1+ (0.1,0) [0|0] "" Vector__XXX
 SG_ VCLEFT_TLCLeftTurnVoltage m1 : 10|8@1+ (0.1,0) [0|0] "" Vector__XXX
 SG_ VCLEFT_TLCLeftTurnCurrent m0 : 8|8@1+ (0.1,0) [0|0] "" Vector__XXX
 SG_ VCLEFT_TLCTemperature m1 : 2|8@1- (1,68) [0|0] "" Vector__XXX
 SG_ VCLEFT_TLCStatusIndex M : 0|2@1+ (1,0) [0|0] "" Vector__XXX

BO_ 521 DAS_longControl: 8 Vector__XXX
 SG_ DAS_longControlStack M : 61|3@1+ (1,0) [0|0] "" Vector__XXX
 SG_ DAS_velocityProfile_calcDelay m3 : 58|3@1+ (0.006666666666666667,0) [0|0] "" Vector__XXX
 SG_ DAS_torqueProfiler_jerkMaxPed m2 : 53|8@1+ (0.059,0) [0|0] "" Vector__XXX
 SG_ DAS_velocityProfile_maxAllowedTargetErrorReg m3 : 52|6@1- (0.1,1.1) [0|0] "" Vector__XXX
 SG_ DAS_pedalControl_speedMax m5 : 51|8@1+ (1,0) [0|0] "" Vector__XXX
 SG_ DAS_pedalControl_noGradeAccelMax m5 : 45|6@1+ (0.25,0) [0|0] "" Vector__XXX
 SG_ DAS_torqueProfiler_jerkMinPed m2 : 44|9@1+ (0.03,-15.232) [0|0] "" Vector__XXX
 SG_ DAS_velocityProfile_jerkFwd_t1t2 m3 : 44|8@1- (0.12,0) [0|0] "" Vector__XXX
 SG_ DAS_pedalControl_brakeTorqueCommand m5 : 32|13@1+ (3.5,0) [0|0] "" Vector__XXX
 SG_ DAS_torqueControl_standstillRequest m6 : 32|1@1+ (1,0) [0|0] "" Vector__XXX
 SG_ DAS_torqueProfiler_targetSpeedPed m2 : 32|12@1+ (0.1,0) [0|0] "" Vector__XXX
 SG_ DAS_velocityProfile_futureTargetSpeedFwd m3 : 32|12@1- (0.08,80.08) [0|0] "" Vector__XXX
 SG_ DAS_velocityProfile_jerkFwd_t0t1 m3 : 24|8@1- (0.12,0) [0|0] "" Vector__XXX
 SG_ DAS_torqueProfiler_accelMaxPed m2 : 23|9@1+ (0.04,-15) [0|0] "" Vector__XXX
 SG_ DAS_aebControl_targetAccelDis m4 : 18|11@1- (0.01,-7.5) [0|0] "" Vector__XXX
 SG_ DAS_aebControl_active m4 : 16|2@1+ (1,0) [0|0] "" Vector__XXX
 SG_ DAS_pedalControl_accelPedalPos m5 : 16|12@1+ (0.025,0) [0|0] "" Vector__XXX
 SG_ DAS_torqueControl_sysTorqueCommandFwd m6 : 16|15@1- (2,0) [0|0] "" Vector__XXX
 SG_ DAS_torqueProfiler_accelMinPed m2 : 14|9@1+ (0.04,-15) [0|0] "" Vector__XXX
 SG_ DAS_velocityProfile_accelFwd_t0 m3 : 13|11@1- (0.012,-0.216) [0|0] "" Vector__XXX
 SG_ DAS_gearRequest : 11|2@1+ (1,0) [0|0] "" Vector__XXX
 SG_ DAS_longControlCounter : 8|3@1+ (1,0) [0|0] "" Vector__XXX
 SG_ DAS_longControlChecksum : 0|8@1+ (1,0) [0|0] "" Vector__XXX

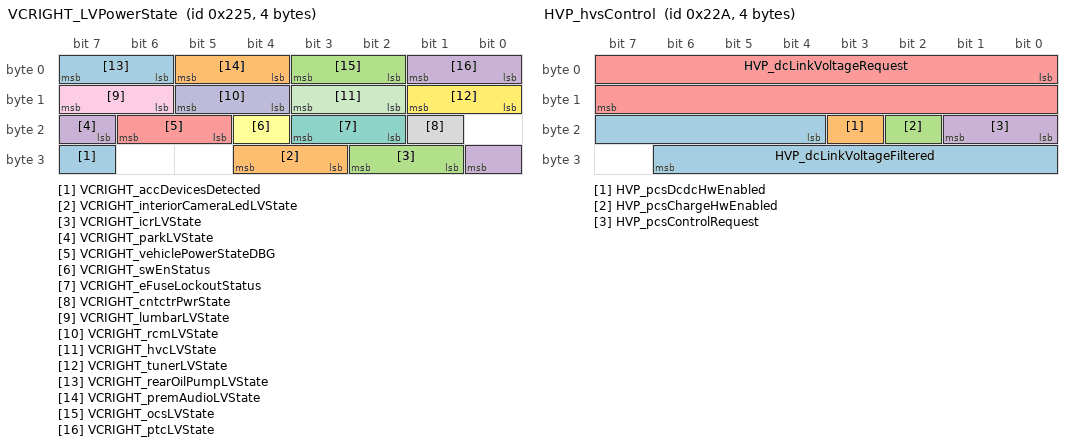
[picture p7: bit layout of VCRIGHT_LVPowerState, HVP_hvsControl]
BO_ 549 VCRIGHT_LVPowerState: 4 Vector__XXX
 SG_ VCRIGHT_accDevicesDetected : 31|1@1+ (1,0) [0|0] "" Vector__XXX
 SG_ VCRIGHT_interiorCameraLedLVState : 27|2@1+ (1,0) [0|0] "" Vector__XXX
 SG_ VCRIGHT_icrLVState : 25|2@1+ (1,0) [0|0] "" Vector__XXX
 SG_ VCRIGHT_parkLVState : 23|2@1+ (1,0) [0|0] "" Vector__XXX
 SG_ VCRIGHT_vehiclePowerStateDBG : 21|2@1+ (1,0) [0|0] "" Vector__XXX
 SG_ VCRIGHT_swEnStatus : 20|1@1+ (1,0) [0|0] "" Vector__XXX
 SG_ VCRIGHT_eFuseLockoutStatus : 18|2@1+ (1,0) [0|0] "" Vector__XXX
 SG_ VCRIGHT_cntctrPwrState : 17|1@1+ (1,0) [0|0] "" Vector__XXX
 SG_ VCRIGHT_lumbarLVState : 14|2@1+ (1,0) [0|0] "" Vector__XXX
 SG_ VCRIGHT_rcmLVState : 12|2@1+ (1,0) [0|0] "" Vector__XXX
 SG_ VCRIGHT_hvcLVState : 10|2@1+ (1,0) [0|0] "" Vector__XXX
 SG_ VCRIGHT_tunerLVState : 8|2@1+ (1,0) [0|0] "" Vector__XXX
 SG_ VCRIGHT_rearOilPumpLVState : 6|2@1+ (1,0) [0|0] "" Vector__XXX
 SG_ VCRIGHT_premAudioLVState : 4|2@1+ (1,0) [0|0] "" Vector__XXX
 SG_ VCRIGHT_ocsLVState : 2|2@1+ (1,0) [0|0] "" Vector__XXX
 SG_ VCRIGHT_ptcLVState : 0|2@1+ (1,0) [0|0] "" Vector__XXX

BO_ 551 OCS1P_debugCushionMutCNT: 8 Vector__XXX
 SG_ OCS1P_cushionMutCNTFreqMed : 48|16@1+ (10,0) [0|0] "" Vector__XXX
 SG_ OCS1P_cushionMutCNTDuty : 32|16@1+ (1,0) [0|0] "" Vector__XXX
 SG_ OCS1P_cushionMutCNTFreq : 0|32@1+ (1,0) [0|0] "" Vector__XXX

BO_ 554 HVP_hvsControl: 4 Vector__XXX
 SG_ HVP_dcLinkVoltageFiltered : 20|11@1- (1,0) [0|0] "" Vector__XXX
 SG_ HVP_pcsDcdcHwEnabled : 19|1@1+ (1,0) [0|0] "" Vector__XXX
 SG_ HVP_pcsChargeHwEnabled : 18|1@1+ (1,0) [0|0] "" Vector__XXX
 SG_ HVP_pcsControlRequest : 16|2@1+ (1,0) [0|0] "" Vector__XXX
 SG_ HVP_dcLinkVoltageRequest : 0|16@1- (0.1,0) [0|0] "" Vector__XXX

BO_ 555 DAS_matrixHighBeamRequest: 8 Vector__XXX
 SG_ DAS_azimuthSegmentLightRequests : 0|64@1+ (1,0) [0|0] "" Vector__XXX

BO_ 561 OCS1P_debugSeatbackSelfCNT: 8 Vector__XXX
 SG_ OCS1P_seatbackSelfCNTFreqMed : 48|16@1+ (10,0) [0|0] "" Vector__XXX
 SG_ OCS1P_seatbackSelfCNTDuty : 32|16@1+ (1,0) [0|0] "" Vector__XXX
 SG_ OCS1P_seatbackSelfCNTFreq : 0|32@1+ (1,0) [0|0] "" Vector__XXX

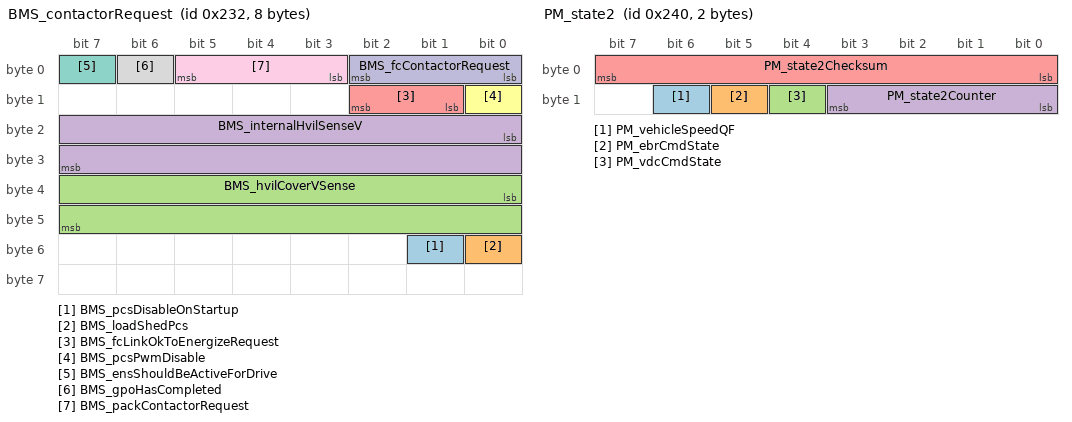
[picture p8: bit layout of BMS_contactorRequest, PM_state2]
BO_ 562 BMS_contactorRequest: 8 Vector__XXX
 SG_ BMS_pcsDisableOnStartup : 49|1@1+ (1,0) [0|0] "" Vector__XXX
 SG_ BMS_loadShedPcs : 48|1@1+ (1,0) [0|0] "" Vector__XXX
 SG_ BMS_hvilCoverVSense : 32|16@1+ (0.001,0) [0|0] "" Vector__XXX
 SG_ BMS_internalHvilSenseV : 16|16@1+ (0.001,0) [0|0] "" Vector__XXX
 SG_ BMS_fcLinkOkToEnergizeRequest : 9|2@1+ (1,0) [0|0] "" Vector__XXX
 SG_ BMS_pcsPwmDisable : 8|1@1+ (1,0) [0|0] "" Vector__XXX
 SG_ BMS_ensShouldBeActiveForDrive : 7|1@1+ (1,0) [0|0] "" Vector__XXX
 SG_ BMS_gpoHasCompleted : 6|1@1+ (1,0) [0|0] "" Vector__XXX
 SG_ BMS_packContactorRequest : 3|3@1+ (1,0) [0|0] "" Vector__XXX
 SG_ BMS_fcContactorRequest : 0|3@1+ (1,0) [0|0] "" Vector__XXX

BO_ 564 DCDC_power: 8 Vector__XXX
 SG_ DCDC_powerChecksum : 56|8@1+ (1,0) [0|0] "" Vector__XXX
 SG_ DCDC_powerCounter : 52|4@1+ (1,0) [0|0] "" Vector__XXX
 SG_ DCDC_powerMuxIndex M : 50|2@1+ (1,0) [0|0] "" Vector__XXX
 SG_ DCDC_type m0 : 45|2@1+ (1,0) [0|0] "" Vector__XXX
 SG_ DCDC_auxiliaryStageSaturationWarning m0 : 44|1@1+ (1,0) [0|0] "" Vector__XXX
 SG_ DCDC_packSideContLvOutputPowerLimit m1 : 40|10@1+ (10,0) [0|0] "" Vector__XXX
 SG_ DCDC_instantLvOutputPowerLimit m0 : 34|10@1+ (10,0) [0|0] "" Vector__XXX
 SG_ DCDC_minTargetContLvOutputPowerLimit m1 : 30|10@1+ (10,0) [0|0] "" Vector__XXX
 SG_ DCDC_continuousLvOutputPowerLimit m0 : 24|10@1+ (10,0) [0|0] "" Vector__XXX
 SG_ DCDC_severeOvLvInputPowerLimit m1 : 20|10@1+ (10,0) [0|0] "" Vector__XXX
 SG_ DCDC_filteredLvOutputPowerEstimated m0 : 12|12@1- (10,0) [0|0] "" Vector__XXX
 SG_ DCDC_severeUvLvOutputPowerLimit m1 : 10|10@1+ (10,0) [0|0] "" Vector__XXX
 SG_ DCDC_instantLvOutputPowerEstimated m0 : 0|12@1- (10,0) [0|0] "" Vector__XXX
 SG_ DCDC_transientLvOutputPowerLimit m1 : 0|10@1+ (10,0) [0|0] "" Vector__XXX

BO_ 565 OCS1P_debugTHS: 4 Vector__XXX
 SG_ OCS1P_humidity : 16|16@1+ (0.1,0) [0|0] "" Vector__XXX
 SG_ OCS1P_temperature : 0|16@1- (0.1,0) [0|0] "" Vector__XXX

BO_ 576 PM_state2: 2 Vector__XXX
 SG_ PM_vehicleSpeedQF : 14|1@1+ (1,0) [0|0] "" Vector__XXX
 SG_ PM_ebrCmdState : 13|1@1+ (1,0) [0|0] "" Vector__XXX
 SG_ PM_vdcCmdState : 12|1@1+ (1,0) [0|0] "" Vector__XXX
 SG_ PM_state2Counter : 8|4@1+ (1,0) [0|0] "" Vector__XXX
 SG_ PM_state2Checksum : 0|8@1+ (1,0) [0|0] "" Vector__XXX

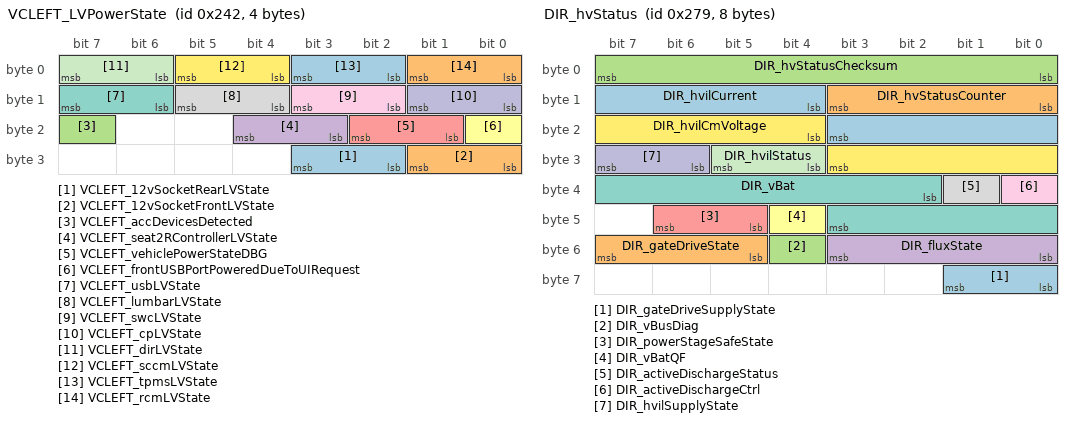
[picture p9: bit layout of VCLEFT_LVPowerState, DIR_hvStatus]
BO_ 578 VCLEFT_LVPowerState: 4 Vector__XXX
 SG_ VCLEFT_12vSocketRearLVState : 26|2@1+ (1,0) [0|0] "" Vector__XXX
 SG_ VCLEFT_12vSocketFrontLVState : 24|2@1+ (1,0) [0|0] "" Vector__XXX
 SG_ VCLEFT_accDevicesDetected : 23|1@1+ (1,0) [0|0] "" Vector__XXX
 SG_ VCLEFT_seat2RControllerLVState : 19|2@1+ (1,0) [0|0] "" Vector__XXX
 SG_ VCLEFT_vehiclePowerStateDBG : 17|2@1+ (1,0) [0|0] "" Vector__XXX
 SG_ VCLEFT_frontUSBPortPoweredDueToUIRequest : 16|1@1+ (1,0) [0|0] "" Vector__XXX
 SG_ VCLEFT_usbLVState : 14|2@1+ (1,0) [0|0] "" Vector__XXX
 SG_ VCLEFT_lumbarLVState : 12|2@1+ (1,0) [0|0] "" Vector__XXX
 SG_ VCLEFT_swcLVState : 10|2@1+ (1,0) [0|0] "" Vector__XXX
 SG_ VCLEFT_cpLVState : 8|2@1+ (1,0) [0|0] "" Vector__XXX
 SG_ VCLEFT_dirLVState : 6|2@1+ (1,0) [0|0] "" Vector__XXX
 SG_ VCLEFT_sccmLVState : 4|2@1+ (1,0) [0|0] "" Vector__XXX
 SG_ VCLEFT_tpmsLVState : 2|2@1+ (1,0) [0|0] "" Vector__XXX
 SG_ VCLEFT_rcmLVState : 0|2@1+ (1,0) [0|0] "" Vector__XXX

BO_ 608 UNK_260: 8 Vector__XXX
 SG_ UNK_260_flag : 0|1@1+ (1,0) [0|1] "" Vector__XXX
 SG_ UNK_260_counter : 52|4@1+ (1,0) [0|15] "" Vector__XXX
 SG_ UNK_260_checksum : 56|8@1+ (1,0) [0|255] "" Vector__XXX

BO_ 633 DIR_hvStatus: 8 Vector__XXX
 SG_ DIR_gateDriveSupplyState : 56|2@1+ (1,0) [0|0] "" Vector__XXX
 SG_ DIR_gateDriveState : 53|3@1+ (1,0) [0|0] "" Vector__XXX
 SG_ DIR_vBusDiag : 52|1@1+ (1,0) [0|0] "" Vector__XXX
 SG_ DIR_fluxState : 48|4@1+ (1,0) [0|0] "" Vector__XXX
 SG_ DIR_powerStageSafeState : 45|2@1+ (1,0) [0|0] "" Vector__XXX
 SG_ DIR_vBatQF : 44|1@1+ (1,0) [0|0] "" Vector__XXX
 SG_ DIR_vBat : 34|10@1+ (1,0) [0|0] "" Vector__XXX
 SG_ DIR_activeDischargeStatus : 33|1@1+ (1,0) [0|0] "" Vector__XXX
 SG_ DIR_activeDischargeCtrl : 32|1@1+ (1,0) [0|0] "" Vector__XXX
 SG_ DIR_hvilSupplyState : 30|2@1+ (1,0) [0|0] "" Vector__XXX
 SG_ DIR_hvilStatus : 28|2@1+ (1,0) [0|0] "" Vector__XXX
 SG_ DIR_hvilCmVoltage : 20|8@1+ (0.08,0) [0|0] "" Vector__XXX
 SG_ DIR_hvilCurrent : 12|8@1+ (0.1,0) [0|0] "" Vector__XXX
 SG_ DIR_hvStatusCounter : 8|4@1+ (1,0) [0|0] "" Vector__XXX
 SG_ DIR_hvStatusChecksum : 0|8@1+ (1,0) [0|0] "" Vector__XXX

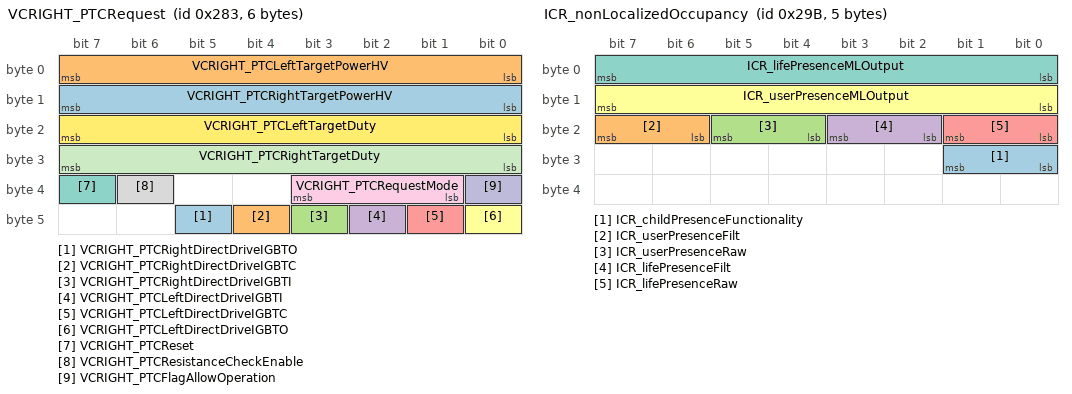
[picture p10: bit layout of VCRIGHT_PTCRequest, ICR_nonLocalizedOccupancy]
BO_ 643 VCRIGHT_PTCRequest: 6 Vector__XXX
 SG_ VCRIGHT_PTCRightDirectDriveIGBTO : 45|1@1+ (1,0) [0|0] "" Vector__XXX
 SG_ VCRIGHT_PTCRightDirectDriveIGBTC : 44|1@1+ (1,0) [0|0] "" Vector__XXX
 SG_ VCRIGHT_PTCRightDirectDriveIGBTI : 43|1@1+ (1,0) [0|0] "" Vector__XXX
 SG_ VCRIGHT_PTCLeftDirectDriveIGBTI : 42|1@1+ (1,0) [0|0] "" Vector__XXX
 SG_ VCRIGHT_PTCLeftDirectDriveIGBTC : 41|1@1+ (1,0) [0|0] "" Vector__XXX
 SG_ VCRIGHT_PTCLeftDirectDriveIGBTO : 40|1@1+ (1,0) [0|0] "" Vector__XXX
 SG_ VCRIGHT_PTCReset : 39|1@1+ (1,0) [0|0] "" Vector__XXX
 SG_ VCRIGHT_PTCResistanceCheckEnable : 38|1@1+ (1,0) [0|0] "" Vector__XXX
 SG_ VCRIGHT_PTCRequestMode : 33|3@1+ (1,0) [0|0] "" Vector__XXX
 SG_ VCRIGHT_PTCFlagAllowOperation : 32|1@1+ (1,0) [0|0] "" Vector__XXX
 SG_ VCRIGHT_PTCRightTargetDuty : 24|8@1+ (0.5,0) [0|0] "" Vector__XXX
 SG_ VCRIGHT_PTCLeftTargetDuty : 16|8@1+ (0.5,0) [0|0] "" Vector__XXX
 SG_ VCRIGHT_PTCRightTargetPowerHV : 8|8@1+ (30,0) [0|0] "" Vector__XXX
 SG_ VCRIGHT_PTCLeftTargetPowerHV : 0|8@1+ (30,0) [0|0] "" Vector__XXX

BO_ 649 VCLEFT_logging10Hz: 8 Vector__XXX
 SG_ VCLEFT_hvacBlowerRsOnlineActive m0 : 63|1@1+ (1,0) [0|0] "" Vector__XXX
 SG_ VCLEFT_hvacBlowerSpiError m0 : 62|1@1+ (1,0) [0|0] "" Vector__XXX
 SG_ VCLEFT_hvacBlowerITerm m0 : 55|7@1+ (0.05,-1.5) [0|0] "" Vector__XXX
 SG_ VCLEFT_hvacBlowerCBCCtrlState m0 : 52|3@1+ (1,0) [0|0] "" Vector__XXX
 SG_ VCLEFT_hvacBlowerCBCEstState m0 : 48|4@1+ (1,0) [0|0] "" Vector__XXX
 SG_ VCLEFT_hvacBlower_IO_CBC_numUartErr m0 : 40|8@1+ (1,0) [0|0] "" Vector__XXX
 SG_ VCLEFT_hvacBlower_IO_CBC_Status m0 : 39|1@1+ (1,0) [0|0] "" Vector__XXX
 SG_ VCLEFT_hvacBlower_IO_CBC_TAIL_valid m0 : 38|1@1+ (1,0) [0|0] "" Vector__XXX
 SG_ VCLEFT_hvacBlower_IO_CBC_TAIL m0 : 34|4@1+ (1,0) [0|0] "" Vector__XXX
 SG_ VCLEFT_hvacBlower_IO_CBC_HEAD m0 : 30|4@1+ (1,0) [0|0] "" Vector__XXX
 SG_ VCLEFT_hvacBlowerIPhase2 m0 : 23|7@1+ (0.4,0) [0|0] "" Vector__XXX
 SG_ VCLEFT_hvacBlowerIPhase1 m0 : 16|7@1+ (0.4,0) [0|0] "" Vector__XXX
 SG_ VCLEFT_hvacBlowerIPhase0 m0 : 9|7@1+ (0.4,0) [0|0] "" Vector__XXX
 SG_ VCLEFT_hvacBlowerRs m0 : 1|8@1+ (0.25,0) [0|0] "" Vector__XXX
 SG_ VCLEFT_logging10HzIndex M : 0|1@1+ (1,0) [0|0] "" Vector__XXX

BO_ 654 UNK_28E_alive: 8 Vector__XXX
 SG_ UNK_28E_checksum : 0|8@1+ (1,0) [0|255] "" Vector__XXX
 SG_ UNK_28E_counter : 8|4@1+ (1,0) [0|15] "" Vector__XXX

BO_ 655 UNK_28F_alive: 8 Vector__XXX
 SG_ UNK_28F_checksum : 0|8@1+ (1,0) [0|255] "" Vector__XXX
 SG_ UNK_28F_counter : 8|4@1+ (1,0) [0|15] "" Vector__XXX

BO_ 660 UI_vehicleControl3: 8 Vector__XXX
 SG_ UI_selfParkStandingBy : 62|1@1+ (1,0) [0|0] "" Vector__XXX
 SG_ UI_derivedLoadshedFeature : 59|1@1+ (1,0) [0|0] "" Vector__XXX
 SG_ UI_closeTrunkRequest : 55|1@1+ (1,0) [0|0] "" Vector__XXX
 SG_ UI_windowRequest : 52|3@1+ (1,0) [0|0] "" Vector__XXX
 SG_ UI_windowRequestedRR : 51|1@1+ (1,0) [0|0] "" Vector__XXX
 SG_ UI_windowRequestedRL : 50|1@1+ (1,0) [0|0] "" Vector__XXX
 SG_ UI_windowRequestedFR : 49|1@1+ (1,0) [0|0] "" Vector__XXX
 SG_ UI_windowRequestedFL : 48|1@1+ (1,0) [0|0] "" Vector__XXX
 SG_ UI_windowPercentageRequest : 42|6@1- (5,0) [0|0] "" Vector__XXX
 SG_ UI_keepOnAccessoryPortsReq : 38|1@1+ (1,0) [0|0] "" Vector__XXX
 SG_ UI_blindSpotIndicatorLightRequest : 35|1@1+ (1,0) [0|0] "" Vector__XXX
 SG_ UI_displayRedShiftActive : 24|1@1+ (1,0) [0|0] "" Vector__XXX
 SG_ UI_UMC3UpdateInhibit : 22|1@1+ (1,0) [0|0] "" Vector__XXX
 SG_ UI_packTempLoggingRequest : 18|1@1+ (1,0) [0|0] "" Vector__XXX
 SG_ UI_shortHornRequest : 17|1@1+ (1,0) [0|0] "" Vector__XXX
 SG_ UI_VCSECFeature5 : 16|1@1+ (1,0) [0|0] "" Vector__XXX
 SG_ UI_VCSECFeature4 : 15|1@1+ (1,0) [0|0] "" Vector__XXX
 SG_ UI_VCSECFeature3 : 14|1@1+ (1,0) [0|0] "" Vector__XXX
 SG_ UI_VCSECFeature2 : 13|1@1+ (1,0) [0|0] "" Vector__XXX
 SG_ UI_headlightPulseRequest : 12|1@1+ (1,0) [0|0] "" Vector__XXX
 SG_ UI_steeringWheelHeatLevelReq : 10|2@1+ (1,0) [0|0] "" Vector__XXX
 SG_ UI_steeringWheelHeatAutoReq : 9|1@1+ (1,0) [0|0] "" Vector__XXX
 SG_ UI_lightShowClosuresEnabled : 8|1@1+ (1,0) [0|0] "" Vector__XXX
 SG_ UI_keyPairResponse : 6|2@1+ (1,0) [0|0] "" Vector__XXX
 SG_ UI_drivingSideVEH : 4|2@1+ (1,0) [0|0] "" Vector__XXX
 SG_ UI_phoneCallActive : 3|1@1+ (1,0) [0|0] "" Vector__XXX
 SG_ UI_keylessDrivingEnabled : 2|1@1+ (1,0) [0|0] "" Vector__XXX
 SG_ UI_lightFlashRequest : 0|2@1+ (1,0) [0|0] "" Vector__XXX

BO_ 661 UI_powerRationalityConfig: 8 Vector__XXX
 SG_ UI_powerRationalityConfigIndex M : 56|8@1+ (1,0) [0|0] "" Vector__XXX
 SG_ UI_vcleftCfgCutoffDynamicC m8 : 32|16@1- (50,0) [0|0] "" Vector__XXX
 SG_ UI_vcleftCfgCutoffStaticC m7 : 32|16@1- (50,0) [0|0] "" Vector__XXX
 SG_ UI_vcleftCfgRationalityDynamicC m2 : 32|16@1- (50,0) [0|0] "" Vector__XXX
 SG_ UI_vcleftCfgRationalityStaticC m1 : 32|16@1- (50,0) [0|0] "" Vector__XXX
 SG_ UI_vcrightCfgCutoffDynamicC m11 : 32|16@1- (50,0) [0|0] "" Vector__XXX
 SG_ UI_vcrightCfgCutoffStaticC m10 : 32|16@1- (50,0) [0|0] "" Vector__XXX
 SG_ UI_vcrightCfgRationalityDynamicC m5 : 32|16@1- (50,0) [0|0] "" Vector__XXX
 SG_ UI_vcrightCfgRationalityStaticC m4 : 32|16@1- (50,0) [0|0] "" Vector__XXX
 SG_ UI_vcleftCfgCutoffDynamicB m8 : 16|16@1- (1,0) [0|0] "" Vector__XXX
 SG_ UI_vcleftCfgCutoffStaticB m7 : 16|16@1- (1,0) [0|0] "" Vector__XXX
 SG_ UI_vcleftCfgRationalityDynamicB m2 : 16|16@1- (1,0) [0|0] "" Vector__XXX
 SG_ UI_vcleftCfgRationalityStaticB m1 : 16|16@1- (1,0) [0|0] "" Vector__XXX
 SG_ UI_vcrightCfgCutoffDynamicB m11 : 16|16@1- (1,0) [0|0] "" Vector__XXX
 SG_ UI_vcrightCfgCutoffStaticB m10 : 16|16@1- (1,0) [0|0] "" Vector__XXX
 SG_ UI_vcrightCfgRationalityDynamicB m5 : 16|16@1- (1,0) [0|0] "" Vector__XXX
 SG_ UI_vcrightCfgRationalityStaticB m4 : 16|16@1- (1,0) [0|0] "" Vector__XXX
 SG_ UI_vcleftCfgCutoffTime1 m6 : 12|4@1+ (1,0) [0|0] "" Vector__XXX
 SG_ UI_vcleftCfgRationalityTime1 m0 : 12|4@1+ (1,0) [0|0] "" Vector__XXX
 SG_ UI_vcrightCfgCutoffTime1 m9 : 12|4@1+ (1,0) [0|0] "" Vector__XXX
 SG_ UI_vcrightCfgRationalityTime1 m3 : 12|4@1+ (1,0) [0|0] "" Vector__XXX
 SG_ UI_vcleftCfgCutoffThreshold1 m6 : 8|4@1+ (1,0) [0|0] "" Vector__XXX
 SG_ UI_vcleftCfgRationalityThreshold1 m0 : 8|4@1+ (1,0) [0|0] "" Vector__XXX
 SG_ UI_vcrightCfgCutoffThreshold1 m9 : 8|4@1+ (1,0) [0|0] "" Vector__XXX
 SG_ UI_vcrightCfgRationalityThreshold1 m3 : 8|4@1+ (1,0) [0|0] "" Vector__XXX
 SG_ UI_vcleftCfgCutoffTime0 m6 : 4|4@1+ (1,0) [0|0] "" Vector__XXX
 SG_ UI_vcleftCfgRationalityTime0 m0 : 4|4@1+ (1,0) [0|0] "" Vector__XXX
 SG_ UI_vcrightCfgCutoffTime0 m9 : 4|4@1+ (1,0) [0|0] "" Vector__XXX
 SG_ UI_vcrightCfgRationalityTime0 m3 : 4|4@1+ (1,0) [0|0] "" Vector__XXX
 SG_ UI_vcleftCfgCutoffDynamicA m8 : 0|16@1+ (50,0) [0|0] "" Vector__XXX
 SG_ UI_vcleftCfgCutoffStaticA m7 : 0|16@1+ (50,0) [0|0] "" Vector__XXX
 SG_ UI_vcleftCfgCutoffThreshold0 m6 : 0|4@1+ (1,0) [0|0] "" Vector__XXX
 SG_ UI_vcleftCfgRationalityDynamicA m2 : 0|16@1+ (50,0) [0|0] "" Vector__XXX
 SG_ UI_vcleftCfgRationalityStaticA m1 : 0|16@1+ (50,0) [0|0] "" Vector__XXX
 SG_ UI_vcleftCfgRationalityThreshold0 m0 : 0|4@1+ (1,0) [0|0] "" Vector__XXX
 SG_ UI_vcrightCfgCutoffDynamicA m11 : 0|16@1+ (50,0) [0|0] "" Vector__XXX
 SG_ UI_vcrightCfgCutoffStaticA m10 : 0|16@1+ (50,0) [0|0] "" Vector__XXX
 SG_ UI_vcrightCfgCutoffThreshold0 m9 : 0|4@1+ (1,0) [0|0] "" Vector__XXX
 SG_ UI_vcrightCfgRationalityDynamicA m5 : 0|16@1+ (50,0) [0|0] "" Vector__XXX
 SG_ UI_vcrightCfgRationalityStaticA m4 : 0|16@1+ (50,0) [0|0] "" Vector__XXX
 SG_ UI_vcrightCfgRationalityThreshold0 m3 : 0|4@1+ (1,0) [0|0] "" Vector__XXX

BO_ 667 ICR_nonLocalizedOccupancy: 5 Vector__XXX
 SG_ ICR_childPresenceFunctionality : 24|2@1+ (1,0) [0|0] "" Vector__XXX
 SG_ ICR_userPresenceFilt : 22|2@1+ (1,0) [0|0] "" Vector__XXX
 SG_ ICR_userPresenceRaw : 20|2@1+ (1,0) [0|0] "" Vector__XXX
 SG_ ICR_lifePresenceFilt : 18|2@1+ (1,0) [0|0] "" Vector__XXX
 SG_ ICR_lifePresenceRaw : 16|2@1+ (1,0) [0|0] "" Vector__XXX
 SG_ ICR_userPresenceMLOutput : 8|8@1+ (0.004,0) [0|0] "" Vector__XXX
 SG_ ICR_lifePresenceMLOutput : 0|8@1+ (0.004,0) [0|0] "" Vector__XXX

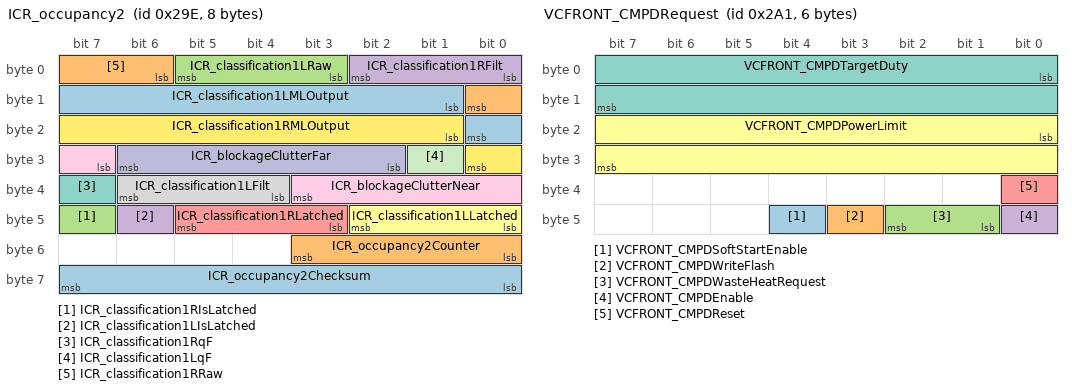
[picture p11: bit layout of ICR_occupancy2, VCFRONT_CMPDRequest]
BO_ 670 ICR_occupancy2: 8 Vector__XXX
 SG_ ICR_occupancy2Checksum : 56|8@1+ (1,0) [0|0] "" Vector__XXX
 SG_ ICR_occupancy2Counter : 48|4@1+ (1,0) [0|0] "" Vector__XXX
 SG_ ICR_classification1RIsLatched : 47|1@1+ (1,0) [0|0] "" Vector__XXX
 SG_ ICR_classification1LIsLatched : 46|1@1+ (1,0) [0|0] "" Vector__XXX
 SG_ ICR_classification1RLatched : 43|3@1+ (1,0) [0|0] "" Vector__XXX
 SG_ ICR_classification1LLatched : 40|3@1+ (1,0) [0|0] "" Vector__XXX
 SG_ ICR_classification1RqF : 39|1@1+ (1,0) [0|0] "" Vector__XXX
 SG_ ICR_classification1LFilt : 36|3@1+ (1,0) [0|0] "" Vector__XXX
 SG_ ICR_blockageClutterNear : 31|5@1- (0.5,-1.5) [0|0] "" Vector__XXX
 SG_ ICR_blockageClutterFar : 26|5@1- (0.5,-1.5) [0|0] "" Vector__XXX
 SG_ ICR_classification1LqF : 25|1@1+ (1,0) [0|0] "" Vector__XXX
 SG_ ICR_classification1RMLOutput : 17|8@1+ (0.004,0) [0|0] "" Vector__XXX
 SG_ ICR_classification1LMLOutput : 9|8@1+ (0.004,0) [0|0] "" Vector__XXX
 SG_ ICR_classification1RRaw : 6|3@1+ (1,0) [0|0] "" Vector__XXX
 SG_ ICR_classification1LRaw : 3|3@1+ (1,0) [0|0] "" Vector__XXX
 SG_ ICR_classification1RFilt : 0|3@1+ (1,0) [0|0] "" Vector__XXX

BO_ 673 VCFRONT_CMPDRequest: 6 Vector__XXX
 SG_ VCFRONT_CMPDSoftStartEnable : 44|1@1+ (1,0) [0|0] "" Vector__XXX
 SG_ VCFRONT_CMPDWriteFlash : 43|1@1+ (1,0) [0|0] "" Vector__XXX
 SG_ VCFRONT_CMPDWasteHeatRequest : 41|2@1+ (1,0) [0|0] "" Vector__XXX
 SG_ VCFRONT_CMPDEnable : 40|1@1+ (1,0) [0|0] "" Vector__XXX
 SG_ VCFRONT_CMPDReset : 32|1@1+ (1,0) [0|0] "" Vector__XXX
 SG_ VCFRONT_CMPDPowerLimit : 16|16@1+ (1,0) [0|0] "" Vector__XXX
 SG_ VCFRONT_CMPDTargetDuty : 0|16@1+ (0.1,0) [0|0] "" Vector__XXX

BO_ 678 CMPD_motorState: 8 Vector__XXX
 SG_ CMPD_motorOverloadCountdown : 16|13@1+ (1,0) [0|0] "" Vector__XXX
 SG_ CMPD_motorCurrent : 0|16@1+ (0.1,0) [0|0] "" Vector__XXX

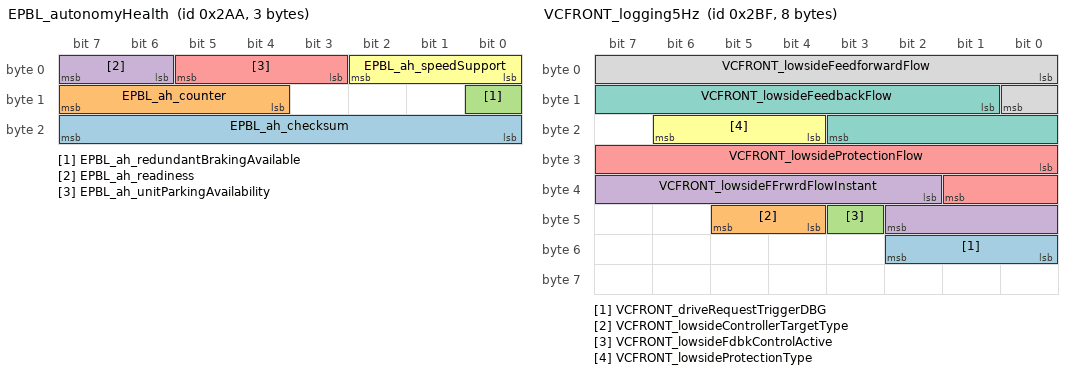
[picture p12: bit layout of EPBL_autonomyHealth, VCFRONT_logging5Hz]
BO_ 682 EPBL_autonomyHealth: 3 Vector__XXX
 SG_ EPBL_ah_checksum : 16|8@1+ (1,0) [0|0] "" Vector__XXX
 SG_ EPBL_ah_counter : 12|4@1+ (1,0) [0|0] "" Vector__XXX
 SG_ EPBL_ah_redundantBrakingAvailable : 8|1@1+ (1,0) [0|0] "" Vector__XXX
 SG_ EPBL_ah_readiness : 6|2@1+ (1,0) [0|0] "" Vector__XXX
 SG_ EPBL_ah_unitParkingAvailability : 3|3@1+ (1,0) [0|0] "" Vector__XXX
 SG_ EPBL_ah_speedSupport : 0|3@1+ (1,0) [0|0] "" Vector__XXX

BO_ 703 VCFRONT_logging5Hz: 8 Vector__XXX
 SG_ VCFRONT_driveRequestTriggerDBG : 48|3@1+ (1,0) [0|0] "" Vector__XXX
 SG_ VCFRONT_lowsideControllerTargetType : 44|2@1+ (1,0) [0|0] "" Vector__XXX
 SG_ VCFRONT_lowsideFdbkControlActive : 43|1@1+ (1,0) [0|0] "" Vector__XXX
 SG_ VCFRONT_lowsideFFrwrdFlowInstant : 34|9@1+ (0.2,0) [0|0] "" Vector__XXX
 SG_ VCFRONT_lowsideProtectionFlow : 24|10@1+ (0.1,0) [0|0] "" Vector__XXX
 SG_ VCFRONT_lowsideProtectionType : 20|3@1+ (1,0) [0|0] "" Vector__XXX
 SG_ VCFRONT_lowsideFeedbackFlow : 9|11@1- (0.1,0) [0|0] "" Vector__XXX
 SG_ VCFRONT_lowsideFeedforwardFlow : 0|9@1+ (0.2,0) [0|0] "" Vector__XXX

BO_ 706 VCLEFT_windowStatus: 8 Vector__XXX
 SG_ VCLEFT_windowCalibratedLR m0 : 63|1@1+ (1,0) [0|0] "" Vector__XXX
 SG_ VCLEFT_windowSpeedTableStatusLR m1 : 62|2@1+ (1,0) [0|0] "" Vector__XXX
 SG_ VCLEFT_windowSpeedTableStatusLF m1 : 60|2@1+ (1,0) [0|0] "" Vector__XXX
 SG_ VCLEFT_windowVehGearStateLR m1 : 58|2@1+ (1,0) [0|0] "" Vector__XXX
 SG_ VCLEFT_windowVehGearStateLF m1 : 56|2@1+ (1,0) [0|0] "" Vector__XXX
 SG_ VCLEFT_windowPositionLR m0 : 54|9@1- (1.25,265) [0|0] "" Vector__XXX
 SG_ VCLEFT_windowPositionStateLR m1 : 52|3@1+ (1,0) [0|0] "" Vector__XXX
 SG_ VCLEFT_windowPositionStateLF m1 : 49|3@1+ (1,0) [0|0] "" Vector__XXX
 SG_ VCLEFT_windowCurrentLR m0 : 48|6@1- (0.5,0) [0|0] "" Vector__XXX
 SG_ VCLEFT_windowCtrlUnavailableLR m1 : 45|3@1+ (1,0) [0|0] "" Vector__XXX
 SG_ VCLEFT_windowControlStateLR m1 : 42|2@1+ (1,0) [0|0] "" Vector__XXX
 SG_ VCLEFT_windowDutyLR m0 : 40|6@1- (5,0) [0|0] "" Vector__XXX
 SG_ VCLEFT_windowCtrlUnavailableLF m1 : 38|3@1+ (1,0) [0|0] "" Vector__XXX
 SG_ VCLEFT_windowControlStateLF m1 : 35|2@1+ (1,0) [0|0] "" Vector__XXX
 SG_ VCLEFT_windowStateLR m0 : 33|4@1+ (1,0) [0|0] "" Vector__XXX
 SG_ VCLEFT_windowCalibratedLF m0 : 32|1@1+ (1,0) [0|0] "" Vector__XXX
 SG_ VCLEFT_windowStopReqReasonLR m1 : 31|4@1+ (1,0) [0|0] "" Vector__XXX
 SG_ VCLEFT_windowStopReasonLR m1 : 28|3@1+ (1,0) [0|0] "" Vector__XXX
 SG_ VCLEFT_windowThermalModeLR m1 : 26|2@1+ (1,0) [0|0] "" Vector__XXX
 SG_ VCLEFT_windowPositionLF m0 : 22|9@1- (1.25,265) [0|0] "" Vector__XXX
 SG_ VCLEFT_windowThermalTCLR m1 : 18|8@1+ (1,0) [0|0] "" Vector__XXX
 SG_ VCLEFT_windowCurrentLF m0 : 16|6@1- (0.5,0) [0|0] "" Vector__XXX
 SG_ VCLEFT_windowStopReqReasonLF m1 : 14|4@1+ (1,0) [0|0] "" Vector__XXX
 SG_ VCLEFT_windowTrimClearActiveRequest m0 : 14|2@1+ (1,0) [0|0] "" Vector__XXX
 SG_ VCLEFT_windowStopReasonLF m1 : 11|3@1+ (1,0) [0|0] "" Vector__XXX
 SG_ VCLEFT_windowThermalModeLF m1 : 9|2@1+ (1,0) [0|0] "" Vector__XXX
 SG_ VCLEFT_windowDutyLF m0 : 8|6@1- (5,0) [0|0] "" Vector__XXX
 SG_ VCLEFT_windowTrimClearMoveRequest m0 : 5|2@1+ (1,0) [0|0] "" Vector__XXX
 SG_ VCLEFT_windowStateLF m0 : 1|4@1+ (1,0) [0|0] "" Vector__XXX
 SG_ VCLEFT_windowThermalTCLF m1 : 1|8@1+ (1,0) [0|0] "" Vector__XXX
 SG_ VCLEFT_windowStatusIndex M : 0|1@1+ (1,0) [0|0] "" Vector__XXX

BO_ 707 VCRIGHT_windowStatus: 8 Vector__XXX
 SG_ VCRIGHT_windowCalibratedRR m0 : 63|1@1+ (1,0) [0|0] "" Vector__XXX
 SG_ VCRIGHT_windowSpeedTableStatusRR m1 : 62|2@1+ (1,0) [0|0] "" Vector__XXX
 SG_ VCRIGHT_windowSpeedTableStatusRF m1 : 60|2@1+ (1,0) [0|0] "" Vector__XXX
 SG_ VCRIGHT_windowVehGearStateRR m1 : 58|2@1+ (1,0) [0|0] "" Vector__XXX
 SG_ VCRIGHT_windowVehGearStateRF m1 : 56|2@1+ (1,0) [0|0] "" Vector__XXX
 SG_ VCRIGHT_windowPositionRR m0 : 54|9@1- (1.25,265) [0|0] "" Vector__XXX
 SG_ VCRIGHT_windowPositionStateRR m1 : 52|3@1+ (1,0) [0|0] "" Vector__XXX
 SG_ VCRIGHT_windowPositionStateRF m1 : 49|3@1+ (1,0) [0|0] "" Vector__XXX
 SG_ VCRIGHT_windowCurrentRR m0 : 48|6@1- (0.5,0) [0|0] "" Vector__XXX
 SG_ VCRIGHT_windowCtrlUnavailableRR m1 : 45|3@1+ (1,0) [0|0] "" Vector__XXX
 SG_ VCRIGHT_windowControlStateRR m1 : 42|2@1+ (1,0) [0|0] "" Vector__XXX
 SG_ VCRIGHT_windowDutyRR m0 : 40|6@1- (5,0) [0|0] "" Vector__XXX
 SG_ VCRIGHT_windowCtrlUnavailableRF m1 : 38|3@1+ (1,0) [0|0] "" Vector__XXX
 SG_ VCRIGHT_windowControlStateRF m1 : 35|2@1+ (1,0) [0|0] "" Vector__XXX
 SG_ VCRIGHT_windowStateRR m0 : 33|4@1+ (1,0) [0|0] "" Vector__XXX
 SG_ VCRIGHT_windowCalibratedRF m0 : 32|1@1+ (1,0) [0|0] "" Vector__XXX
 SG_ VCRIGHT_windowStopReqReasonRR m1 : 31|4@1+ (1,0) [0|0] "" Vector__XXX
 SG_ VCRIGHT_windowStopReasonRR m1 : 28|3@1+ (1,0) [0|0] "" Vector__XXX
 SG_ VCRIGHT_windowThermalModeRR m1 : 26|2@1+ (1,0) [0|0] "" Vector__XXX
 SG_ VCRIGHT_windowPositionRF m0 : 22|9@1- (1.25,265) [0|0] "" Vector__XXX
 SG_ VCRIGHT_windowThermalTCRR m1 : 18|8@1+ (1,0) [0|0] "" Vector__XXX
 SG_ VCRIGHT_windowCurrentRF m0 : 16|6@1- (0.5,0) [0|0] "" Vector__XXX
 SG_ VCRIGHT_windowStopReqReasonRF m1 : 14|4@1+ (1,0) [0|0] "" Vector__XXX
 SG_ VCRIGHT_windowTrimClearActiveRequest m0 : 14|2@1+ (1,0) [0|0] "" Vector__XXX
 SG_ VCRIGHT_windowStopReasonRF m1 : 11|3@1+ (1,0) [0|0] "" Vector__XXX
 SG_ VCRIGHT_windowThermalModeRF m1 : 9|2@1+ (1,0) [0|0] "" Vector__XXX
 SG_ VCRIGHT_windowDutyRF m0 : 8|6@1- (5,0) [0|0] "" Vector__XXX
 SG_ VCRIGHT_windowTrimClearMoveRequest m0 : 5|2@1+ (1,0) [0|0] "" Vector__XXX
 SG_ VCRIGHT_windowStateRF m0 : 1|4@1+ (1,0) [0|0] "" Vector__XXX
 SG_ VCRIGHT_windowThermalTCRF m1 : 1|8@1+ (1,0) [0|0] "" Vector__XXX
 SG_ VCRIGHT_windowStatusIndex M : 0|1@1+ (1,0) [0|0] "" Vector__XXX

BO_ 711 CMPD_faultsAndExtras: 8 Vector__XXX
 SG_ CMPD_inputLVVoltage : 56|8@1+ (0.1,0) [0|0] "" Vector__XXX
 SG_ CMPD_inverterTemperature : 48|8@1+ (1,-40) [0|0] "" Vector__XXX
 SG_ CMPD_IGBTTemperature : 40|8@1+ (1,-40) [0|0] "" Vector__XXX
 SG_ CMPD_overloadDetectionOfSpeed : 32|1@1+ (1,0) [0|0] "" Vector__XXX
 SG_ CMPD_overloadRestrictionCurrent : 31|1@1+ (1,0) [0|0] "" Vector__XXX
 SG_ CMPD_overloadLossOfSync : 30|1@1+ (1,0) [0|0] "" Vector__XXX
 SG_ CMPD_overloadStartFaultDetection : 29|1@1+ (1,0) [0|0] "" Vector__XXX
 SG_ CMPD_overloadStatus : 27|2@1+ (1,0) [0|0] "" Vector__XXX
 SG_ CMPD_overCurrent : 26|1@1+ (1,0) [0|0] "" Vector__XXX
 SG_ CMPD_failedStartRepeated : 25|1@1+ (1,0) [0|0] "" Vector__XXX
 SG_ CMPD_failedStart : 24|1@1+ (1,0) [0|0] "" Vector__XXX
 SG_ CMPD_underTemperature : 23|1@1+ (1,0) [0|0] "" Vector__XXX
 SG_ CMPD_overTemperature : 22|1@1+ (1,0) [0|0] "" Vector__XXX
 SG_ CMPD_warnOverTemperature : 21|1@1+ (1,0) [0|0] "" Vector__XXX
 SG_ CMPD_shortCircuit : 20|1@1+ (1,0) [0|0] "" Vector__XXX
 SG_ CMPD_inverterOpenCircuit : 19|1@1+ (1,0) [0|0] "" Vector__XXX
 SG_ CMPD_internalPowerSupplyFault : 18|1@1+ (1,0) [0|0] "" Vector__XXX
 SG_ CMPD_selfTestFailCPU : 17|1@1+ (1,0) [0|0] "" Vector__XXX
 SG_ CMPD_currentSnsError : 16|1@1+ (1,0) [0|0] "" Vector__XXX
 SG_ CMPD_tempSnsFaultCPU : 15|1@1+ (1,0) [0|0] "" Vector__XXX
 SG_ CMPD_tempSnsFaultIPM2 : 14|1@1+ (1,0) [0|0] "" Vector__XXX
 SG_ CMPD_tempSnsFaultIPM1 : 13|1@1+ (1,0) [0|0] "" Vector__XXX
 SG_ CMPD_HVUnderVoltage : 12|1@1+ (1,0) [0|0] "" Vector__XXX
 SG_ CMPD_HVOverVoltage : 11|1@1+ (1,0) [0|0] "" Vector__XXX
 SG_ CMPD_LVOverVoltage : 10|1@1+ (1,0) [0|0] "" Vector__XXX
 SG_ CMPD_LVUnderVoltage : 9|1@1+ (1,0) [0|0] "" Vector__XXX
 SG_ CMPD_VCFRONTCANTimeout : 8|1@1+ (1,0) [0|0] "" Vector__XXX
 SG_ CMPD_limitOverCurrentHVDC : 2|1@1+ (1,0) [0|0] "" Vector__XXX
 SG_ CMPD_limitOverCurrentPhase : 1|1@1+ (1,0) [0|0] "" Vector__XXX
 SG_ CMPD_limitUnderVoltage : 0|1@1+ (1,0) [0|0] "" Vector__XXX

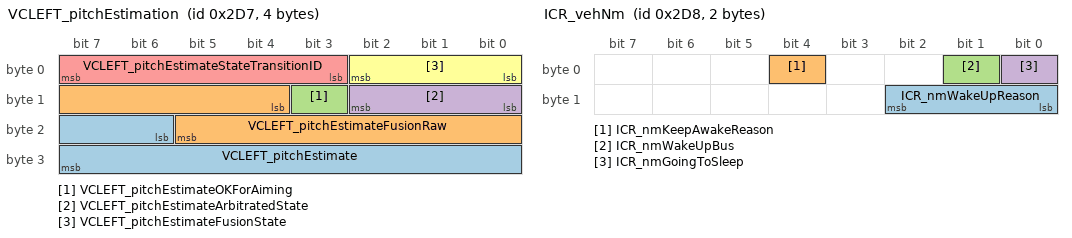
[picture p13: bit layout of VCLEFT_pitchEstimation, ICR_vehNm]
BO_ 727 VCLEFT_pitchEstimation: 4 Vector__XXX
 SG_ VCLEFT_pitchEstimate : 22|10@1- (0.0002,0) [0|0] "" Vector__XXX
 SG_ VCLEFT_pitchEstimateFusionRaw : 12|10@1- (0.0002,0) [0|0] "" Vector__XXX
 SG_ VCLEFT_pitchEstimateOKForAiming : 11|1@1+ (1,0) [0|0] "" Vector__XXX
 SG_ VCLEFT_pitchEstimateArbitratedState : 8|3@1+ (1,0) [0|0] "" Vector__XXX
 SG_ VCLEFT_pitchEstimateStateTransitionID : 3|5@1+ (1,0) [0|0] "" Vector__XXX
 SG_ VCLEFT_pitchEstimateFusionState : 0|3@1+ (1,0) [0|0] "" Vector__XXX

BO_ 728 ICR_vehNm: 2 Vector__XXX
 SG_ ICR_nmWakeUpReason : 8|3@1+ (1,0) [0|0] "" Vector__XXX
 SG_ ICR_nmKeepAwakeReason : 4|1@1+ (1,0) [0|0] "" Vector__XXX
 SG_ ICR_nmWakeUpBus : 1|1@1+ (1,0) [0|0] "" Vector__XXX
 SG_ ICR_nmGoingToSleep : 0|1@1+ (1,0) [0|0] "" Vector__XXX

BO_ 738 VCLEFT_seatStatus2: 8 Vector__XXX
 SG_ VC_AH_1RowLeftSeatHeatVentHealth m0 : 62|2@1+ (1,0) [0|0] "" Vector__XXX
 SG_ VC_AH_2RowCenterSeatHeatVentHealth m4 : 62|2@1+ (1,0) [0|0] "" Vector__XXX
 SG_ VC_AH_2RowLeftSeatHeatVentHealth m3 : 62|2@1+ (1,0) [0|0] "" Vector__XXX
 SG_ VC_AH_2RowRightSeatHeatVentHealth m5 : 62|2@1+ (1,0) [0|0] "" Vector__XXX
 SG_ VCLEFT_2RowSeatCenterSwitchVoltage m7 : 54|10@1+ (0.01,0) [0|0] "" Vector__XXX
 SG_ VCLEFT_rearCenterBuckleVoltage m2 : 52|8@1+ (0.02,0) [0|0] "" Vector__XXX
 SG_ VCLEFT_frontSeatHeatPowered m0 : 45|1@1+ (1,0) [0|0] "" Vector__XXX
 SG_ VCLEFT_rearCHeatPowered m4 : 45|1@1+ (1,0) [0|0] "" Vector__XXX
 SG_ VCLEFT_rearLBackHeatPowered m1 : 45|1@1+ (1,0) [0|0] "" Vector__XXX
 SG_ VCLEFT_rearLHeatPowered m3 : 45|1@1+ (1,0) [0|0] "" Vector__XXX
 SG_ VCLEFT_rearRCushionHeatPowered m5 : 45|1@1+ (1,0) [0|0] "" Vector__XXX
 SG_ VCLEFT_2RowSeatEasyEntrySwitchVoltage m7 : 44|10@1+ (0.01,0) [0|0] "" Vector__XXX
 SG_ VCLEFT_frontSeatHeatInhibited m0 : 44|1@1+ (1,0) [0|0] "" Vector__XXX
 SG_ VCLEFT_rearCHeatInhibited m4 : 44|1@1+ (1,0) [0|0] "" Vector__XXX
 SG_ VCLEFT_rearLBackHeatInhibited m1 : 44|1@1+ (1,0) [0|0] "" Vector__XXX
 SG_ VCLEFT_rearLHeatInhibited m3 : 44|1@1+ (1,0) [0|0] "" Vector__XXX
 SG_ VCLEFT_rearRCushionHeatInhibited m5 : 44|1@1+ (1,0) [0|0] "" Vector__XXX
 SG_ VCLEFT_rearRightOccupancyVoltage m2 : 44|8@1+ (0.02,0) [0|0] "" Vector__XXX
 SG_ VCLEFT_2RowSeatCenterActuatorDuty m6 : 40|12@1- (0.1,0) [0|0] "" Vector__XXX
 SG_ VCLEFT_frontSeatHeatTmpTarget m0 : 36|8@1- (0.5,0) [0|0] "" Vector__XXX
 SG_ VCLEFT_rearCHeatTmpTarget m4 : 36|8@1- (0.5,0) [0|0] "" Vector__XXX
 SG_ VCLEFT_rearCenterOccupancyVoltage m2 : 36|8@1+ (0.02,0) [0|0] "" Vector__XXX
 SG_ VCLEFT_rearLBackHeatTmpTarget m1 : 36|8@1- (0.5,0) [0|0] "" Vector__XXX
 SG_ VCLEFT_rearLHeatTmpTarget m3 : 36|8@1- (0.5,0) [0|0] "" Vector__XXX
 SG_ VCLEFT_rearRCushionHeatTmpTarget m5 : 36|8@1- (0.5,0) [0|0] "" Vector__XXX
 SG_ VCLEFT_2RowSeatReclineSwitchVoltage m7 : 34|10@1+ (0.01,0) [0|0] "" Vector__XXX
 SG_ VCLEFT_2RowSeatTrackPositionSwitch m9 : 31|2@1+ (1,0) [0|0] "" Vector__XXX
 SG_ VCLEFT_2RowSeatCenterActuatorCurrent m6 : 28|12@1- (0.01,0) [0|0] "" Vector__XXX
 SG_ VCLEFT_2RowSeatEasyEntryState m9 : 28|3@1+ (1,0) [0|0] "" Vector__XXX
 SG_ VCLEFT_rearLeftOccupancyVoltage m2 : 28|8@1+ (0.02,0) [0|0] "" Vector__XXX
 SG_ VCLEFT_frontSeatHeatTmp m0 : 24|12@1- (0.05,0) [0|0] "" Vector__XXX
 SG_ VCLEFT_frontSeatLiftTiltSwitchVoltage m7 : 24|10@1+ (0.01,0) [0|0] "" Vector__XXX
 SG_ VCLEFT_rearCHeatTmp m4 : 24|12@1- (0.05,0) [0|0] "" Vector__XXX
 SG_ VCLEFT_rearLBackHeatTmp m1 : 24|12@1- (0.05,0) [0|0] "" Vector__XXX
 SG_ VCLEFT_rearLHeatTmp m3 : 24|12@1- (0.05,0) [0|0] "" Vector__XXX
 SG_ VCLEFT_rearRCushionHeatTmp m5 : 24|12@1- (0.05,0) [0|0] "" Vector__XXX
 SG_ VCLEFT_rearLeftBuckleVoltage m2 : 20|8@1+ (0.02,0) [0|0] "" Vector__XXX
 SG_ VCLEFT_2RowSeatReclineActuatorDuty m6 : 16|12@1- (0.1,0) [0|0] "" Vector__XXX
 SG_ VCLEFT_2RowSeatTrackActuatorDuty m9 : 16|12@1- (0.1,0) [0|0] "" Vector__XXX
 SG_ VCLEFT_frontSeatHeatDuty m0 : 16|8@1+ (1,0) [0|0] "" Vector__XXX
 SG_ VCLEFT_rearCHeatDuty m4 : 16|8@1+ (1,0) [0|0] "" Vector__XXX
 SG_ VCLEFT_rearLBackHeatDuty m1 : 16|8@1+ (1,0) [0|0] "" Vector__XXX
 SG_ VCLEFT_rearLHeatDuty m3 : 16|8@1+ (1,0) [0|0] "" Vector__XXX
 SG_ VCLEFT_rearRCushionHeatDuty m5 : 16|8@1+ (1,0) [0|0] "" Vector__XXX
 SG_ VCLEFT_frontSeatLumbarSwitchVoltage m7 : 14|10@1+ (0.01,0) [0|0] "" Vector__XXX
 SG_ VCLEFT_trunkFoldFlatRightSwitchVoltage m8 : 14|10@1+ (0.01,0) [0|0] "" Vector__XXX
 SG_ VCLEFT_frontBuckleVoltage m2 : 12|8@1+ (0.02,0) [0|0] "" Vector__XXX
 SG_ VCLEFT_2RowSeatReclineActuatorCurrent m6 : 4|12@1- (0.01,0) [0|0] "" Vector__XXX
 SG_ VCLEFT_2RowSeatTrackActuatorCurrent m9 : 4|12@1- (0.01,0) [0|0] "" Vector__XXX
 SG_ VCLEFT_frontOccupancyVoltage m2 : 4|8@1+ (0.02,0) [0|0] "" Vector__XXX
 SG_ VCLEFT_frontSeatHeatCurrent m0 : 4|12@1+ (0.01,0) [0|0] "" Vector__XXX
 SG_ VCLEFT_frontSeatTrackBackrestSwitchVoltage m7 : 4|10@1+ (0.01,0) [0|0] "" Vector__XXX
 SG_ VCLEFT_rearCHeatCurrent m4 : 4|12@1+ (0.01,0) [0|0] "" Vector__XXX
 SG_ VCLEFT_rearLBackHeatCurrent m1 : 4|12@1+ (0.01,0) [0|0] "" Vector__XXX
 SG_ VCLEFT_rearLHeatCurrent m3 : 4|12@1+ (0.01,0) [0|0] "" Vector__XXX
 SG_ VCLEFT_rearRCushionHeatCurrent m5 : 4|12@1+ (0.01,0) [0|0] "" Vector__XXX
 SG_ VCLEFT_trunkFoldFlatLeftSwitchVoltage m8 : 4|10@1+ (0.004887585532746823,0) [0|0] "" Vector__XXX
 SG_ VCLEFT_seatStatus2Index M : 0|4@1+ (1,0) [0|0] "" Vector__XXX

BO_ 739 VCRIGHT_seatStatus2: 7 Vector__XXX
 SG_ VC_AH_1RowRightSeatHeatVentHealth m0 : 54|2@1+ (1,0) [0|0] "" Vector__XXX
 SG_ VCRIGHT_occupantClassificationHoldState m4 : 46|2@1+ (1,0) [0|0] "" Vector__XXX
 SG_ VCRIGHT_frontSeatHeatPowered m0 : 45|1@1+ (1,0) [0|0] "" Vector__XXX
 SG_ VCRIGHT_rearCSeatHeatPowered m2 : 45|1@1+ (1,0) [0|0] "" Vector__XXX
 SG_ VCRIGHT_rearLSeatHeatPowered m1 : 45|1@1+ (1,0) [0|0] "" Vector__XXX
 SG_ VCRIGHT_rearRSeatHeatPowered m3 : 45|1@1+ (1,0) [0|0] "" Vector__XXX
 SG_ VCRIGHT_2RowSeatEasyEntrySwitchVoltage m7 : 44|10@1+ (0.01,0) [0|0] "" Vector__XXX
 SG_ VCRIGHT_frontSeatHeatInhibited m0 : 44|1@1+ (1,0) [0|0] "" Vector__XXX
 SG_ VCRIGHT_rearCSeatHeatInhibited m2 : 44|1@1+ (1,0) [0|0] "" Vector__XXX
 SG_ VCRIGHT_rearLSeatHeatInhibited m1 : 44|1@1+ (1,0) [0|0] "" Vector__XXX
 SG_ VCRIGHT_rearRSeatHeatInhibited m3 : 44|1@1+ (1,0) [0|0] "" Vector__XXX
 SG_ VCRIGHT_frontSeatHeatTmpTarget m0 : 36|8@1- (0.5,0) [0|0] "" Vector__XXX
 SG_ VCRIGHT_rearCSeatHeatTmpTarget m2 : 36|8@1- (0.5,0) [0|0] "" Vector__XXX
 SG_ VCRIGHT_rearLSeatHeatTmpTarget m1 : 36|8@1- (0.5,0) [0|0] "" Vector__XXX
 SG_ VCRIGHT_rearRSeatHeatTmpTarget m3 : 36|8@1- (0.5,0) [0|0] "" Vector__XXX
 SG_ VCRIGHT_2RowSeatReclineSwitchVoltage m7 : 34|10@1+ (0.01,0) [0|0] "" Vector__XXX
 SG_ VCRIGHT_rearRightBuckleVoltage m4 : 34|10@1+ (0.01,0) [0|0] "" Vector__XXX
 SG_ VCRIGHT_ocsIEEState m10 : 32|3@1+ (1,0) [0|0] "" Vector__XXX
 SG_ VCRIGHT_2RowSeatTrackPositionSwitch m9 : 31|2@1+ (1,0) [0|0] "" Vector__XXX
 SG_ VCRIGHT_2RowSeatEasyEntryState m9 : 28|3@1+ (1,0) [0|0] "" Vector__XXX
 SG_ VCRIGHT_3RUSBPortsCurrentAvg m6 : 28|8@1+ (0.01,0) [0|0] "" Vector__XXX
 SG_ VCRIGHT_frontSeatHeatTmp m0 : 24|12@1- (0.05,0) [0|0] "" Vector__XXX
 SG_ VCRIGHT_frontSeatLiftTiltSwitchVoltage m7 : 24|10@1+ (0.01,0) [0|0] "" Vector__XXX
 SG_ VCRIGHT_rearCSeatHeatTmp m2 : 24|12@1- (0.05,0) [0|0] "" Vector__XXX
 SG_ VCRIGHT_rearCenterBuckleVoltage m4 : 24|10@1+ (0.01,0) [0|0] "" Vector__XXX
 SG_ VCRIGHT_rearLSeatHeatTmp m1 : 24|12@1- (0.05,0) [0|0] "" Vector__XXX
 SG_ VCRIGHT_rearRSeatHeatTmp m3 : 24|12@1- (0.05,0) [0|0] "" Vector__XXX
 SG_ VCRIGHT_ocsIEEPowerCurrent m10 : 20|12@1+ (0.001,0) [0|0] "" Vector__XXX
 SG_ VCRIGHT_ocsIEESnsrPassSeatCalRespSts m10 : 18|2@1+ (1,0) [0|0] "" Vector__XXX
 SG_ VCRIGHT_ocsIEEReqOfClrOfFlt m10 : 17|1@1+ (1,0) [0|0] "" Vector__XXX
 SG_ VCRIGHT_2RowSeatReclineActuatorDuty m6 : 16|12@1- (0.1,0) [0|0] "" Vector__XXX
 SG_ VCRIGHT_2RowSeatTrackActuatorDuty m9 : 16|12@1- (0.1,0) [0|0] "" Vector__XXX
 SG_ VCRIGHT_frontSeatHeatDuty m0 : 16|8@1+ (1,0) [0|0] "" Vector__XXX
 SG_ VCRIGHT_ocsIEEReqOfPassSeatCal m10 : 16|1@1+ (1,0) [0|0] "" Vector__XXX
 SG_ VCRIGHT_rearCSeatHeatDuty m2 : 16|8@1+ (1,0) [0|0] "" Vector__XXX
 SG_ VCRIGHT_rearLSeatHeatDuty m1 : 16|8@1+ (1,0) [0|0] "" Vector__XXX
 SG_ VCRIGHT_rearRSeatHeatDuty m3 : 16|8@1+ (1,0) [0|0] "" Vector__XXX
 SG_ VCRIGHT_ocsIEEFltResp8 m10 : 15|1@1+ (1,0) [0|0] "" Vector__XXX
 SG_ VCRIGHT_3RowSeatRightReclineSwitchVoltage m8 : 14|10@1+ (0.01,0) [0|0] "" Vector__XXX
 SG_ VCRIGHT_frontBuckleVoltage m4 : 14|10@1+ (0.01,0) [0|0] "" Vector__XXX
 SG_ VCRIGHT_frontSeatLumbarSwitchVoltage m7 : 14|10@1+ (0.01,0) [0|0] "" Vector__XXX
 SG_ VCRIGHT_ocsIEEFltResp7 m10 : 14|1@1+ (1,0) [0|0] "" Vector__XXX
 SG_ VCRIGHT_ocsIEEFltResp6 m10 : 13|1@1+ (1,0) [0|0] "" Vector__XXX
 SG_ VCRIGHT_ocsIEEFltResp5 m10 : 12|1@1+ (1,0) [0|0] "" Vector__XXX
 SG_ VCRIGHT_ocsIEEFltResp4 m10 : 11|1@1+ (1,0) [0|0] "" Vector__XXX
 SG_ VCRIGHT_ocsIEEFltResp3 m10 : 10|1@1+ (1,0) [0|0] "" Vector__XXX
 SG_ VCRIGHT_ocsIEEFltResp2 m10 : 9|1@1+ (1,0) [0|0] "" Vector__XXX
 SG_ VCRIGHT_ocsIEEFltResp1 m10 : 8|1@1+ (1,0) [0|0] "" Vector__XXX
 SG_ VCRIGHT_ocsIEEMIA m10 : 7|1@1+ (1,0) [0|0] "" Vector__XXX
 SG_ VCRIGHT_ocsIEEEcuFailr m10 : 6|1@1+ (1,0) [0|0] "" Vector__XXX
 SG_ VCRIGHT_2RowSeatReclineActuatorCurrent m6 : 4|12@1- (0.01,0) [0|0] "" Vector__XXX
 SG_ VCRIGHT_2RowSeatTrackActuatorCurrent m9 : 4|12@1- (0.01,0) [0|0] "" Vector__XXX
 SG_ VCRIGHT_3RowSeatLeftReclineSwitchVoltage m8 : 4|10@1+ (0.01,0) [0|0] "" Vector__XXX
 SG_ VCRIGHT_frontOccupancyVoltage m4 : 4|10@1+ (0.01,0) [0|0] "" Vector__XXX
 SG_ VCRIGHT_frontSeatHeatCurrent m0 : 4|12@1+ (0.01,0) [0|0] "" Vector__XXX
 SG_ VCRIGHT_frontSeatTrackBackrestSwitchVoltage m7 : 4|10@1+ (0.01,0) [0|0] "" Vector__XXX
 SG_ VCRIGHT_ocsIEEAirbAllwdSts m10 : 4|2@1+ (1,0) [0|0] "" Vector__XXX
 SG_ VCRIGHT_rearCSeatHeatCurrent m2 : 4|12@1+ (0.01,0) [0|0] "" Vector__XXX
 SG_ VCRIGHT_rearLSeatHeatCurrent m1 : 4|12@1+ (0.01,0) [0|0] "" Vector__XXX
 SG_ VCRIGHT_rearRSeatHeatCurrent m3 : 4|12@1+ (0.01,0) [0|0] "" Vector__XXX
 SG_ VCRIGHT_seatStatus2Index M : 0|4@1+ (1,0) [0|0] "" Vector__XXX

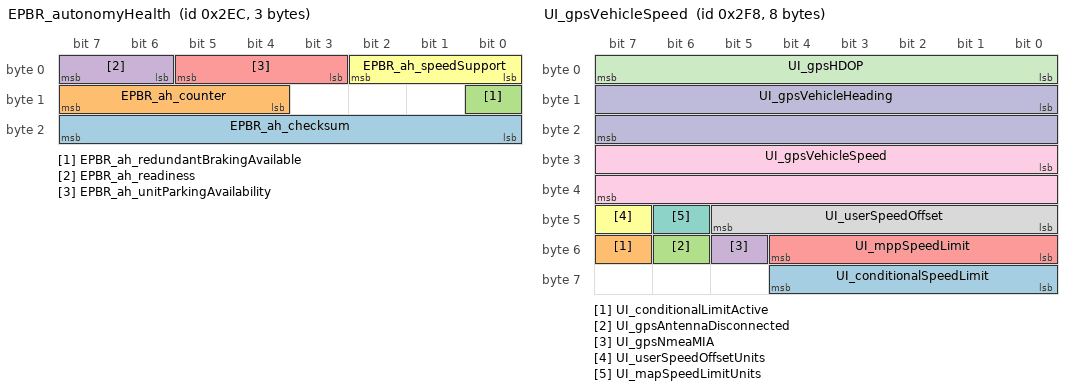
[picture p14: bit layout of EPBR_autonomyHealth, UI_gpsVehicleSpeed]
BO_ 748 EPBR_autonomyHealth: 3 Vector__XXX
 SG_ EPBR_ah_checksum : 16|8@1+ (1,0) [0|0] "" Vector__XXX
 SG_ EPBR_ah_counter : 12|4@1+ (1,0) [0|0] "" Vector__XXX
 SG_ EPBR_ah_redundantBrakingAvailable : 8|1@1+ (1,0) [0|0] "" Vector__XXX
 SG_ EPBR_ah_readiness : 6|2@1+ (1,0) [0|0] "" Vector__XXX
 SG_ EPBR_ah_unitParkingAvailability : 3|3@1+ (1,0) [0|0] "" Vector__XXX
 SG_ EPBR_ah_speedSupport : 0|3@1+ (1,0) [0|0] "" Vector__XXX

BO_ 760 UI_gpsVehicleSpeed: 8 Vector__XXX
 SG_ UI_conditionalSpeedLimit : 56|5@1+ (5,0) [0|0] "" Vector__XXX
 SG_ UI_conditionalLimitActive : 55|1@1+ (1,0) [0|0] "" Vector__XXX
 SG_ UI_gpsAntennaDisconnected : 54|1@1+ (1,0) [0|0] "" Vector__XXX
 SG_ UI_gpsNmeaMIA : 53|1@1+ (1,0) [0|0] "" Vector__XXX
 SG_ UI_mppSpeedLimit : 48|5@1+ (5,0) [0|0] "" Vector__XXX
 SG_ UI_userSpeedOffsetUnits : 47|1@1+ (1,0) [0|0] "" Vector__XXX
 SG_ UI_mapSpeedLimitUnits : 46|1@1+ (1,0) [0|0] "" Vector__XXX
 SG_ UI_userSpeedOffset : 40|6@1+ (1,-30) [0|0] "" Vector__XXX
 SG_ UI_gpsVehicleSpeed : 24|16@1+ (0.00390625,0) [0|0] "" Vector__XXX
 SG_ UI_gpsVehicleHeading : 8|16@1+ (0.0078125,0) [0|0] "" Vector__XXX
 SG_ UI_gpsHDOP : 0|8@1+ (0.1,0) [0|0] "" Vector__XXX

BO_ 761 VCSEC_additionalAuthInfo: 8 Vector__XXX
 SG_ VCSEC_NFCAuthFromCenterConsoleFormFactor m5 : 35|3@1+ (1,0) [0|0] "" Vector__XXX
 SG_ VCSEC_BLEDeviceWithinSummonRange m4 : 32|32@1+ (1,0) [0|0] "" Vector__XXX
 SG_ VCSEC_NFCAuthFromBPillarFormFactor m5 : 32|3@1+ (1,0) [0|0] "" Vector__XXX
 SG_ VCSEC_activeKeySHA1 m0 : 32|32@1+ (1,0) [0|0] "" Vector__XXX
 SG_ VCSEC_keyWithinSummonRange0 m1 : 32|32@1+ (1,0) [0|0] "" Vector__XXX
 SG_ VCSEC_keyWithinSummonRange1 m2 : 32|32@1+ (1,0) [0|0] "" Vector__XXX
 SG_ VCSEC_keyWithinSummonRange2 m3 : 32|32@1+ (1,0) [0|0] "" Vector__XXX
 SG_ VCSEC_AdditionalAuthInfoIndex M : 27|3@1+ (1,0) [0|0] "" Vector__XXX
 SG_ VCSEC_activeKeyReason m0 : 24|3@1+ (1,0) [0|0] "" Vector__XXX
 SG_ VCSEC_bleConnetionAttemptWLEntry : 19|5@1+ (1,0) [0|0] "" Vector__XXX
 SG_ VCSEC_bleDisconnectionReason : 11|8@1+ (1,0) [0|0] "" Vector__XXX
 SG_ VCSEC_bleChannelDisconnected : 7|4@1+ (1,0) [0|0] "" Vector__XXX
 SG_ VCSEC_activeKeyDebug : 2|5@1+ (1,0) [0|0] "" Vector__XXX
 SG_ VCSEC_algoUsedForSummonRange0 m1 : 0|1@1+ (1,0) [0|0] "" Vector__XXX
 SG_ VCSEC_algoUsedForSummonRange1 m2 : 0|1@1+ (1,0) [0|0] "" Vector__XXX
 SG_ VCSEC_algoUsedForSummonRange2 m3 : 0|1@1+ (1,0) [0|0] "" Vector__XXX

BO_ 776 OCS1P_status: 8 Vector__XXX
 SG_ OCS1P_statusChecksum : 56|8@1+ (1,0) [0|0] "" Vector__XXX
 SG_ OCS1P_statusCounter : 52|4@1+ (1,0) [0|0] "" Vector__XXX
 SG_ OCS1P_classificationHeldCap : 51|1@1+ (1,0) [0|0] "" Vector__XXX
 SG_ OCS1P_seatbackStableCap : 50|1@1+ (1,0) [0|0] "" Vector__XXX
 SG_ OCS1P_cushionStableCap : 49|1@1+ (1,0) [0|0] "" Vector__XXX
 SG_ OCS1P_sandwichStable : 48|1@1+ (1,0) [0|0] "" Vector__XXX
 SG_ OCS1P_seatbackStable : 47|1@1+ (1,0) [0|0] "" Vector__XXX
 SG_ OCS1P_occupiedStateCap : 45|2@1+ (1,0) [0|0] "" Vector__XXX
 SG_ OCS1P_sbrBoundaryType : 43|1@1+ (1,0) [0|0] "" Vector__XXX
 SG_ OCS1P_sandwichBoundaryType : 42|1@1+ (1,0) [0|0] "" Vector__XXX
 SG_ OCS1P_noSandwichType : 40|2@1+ (1,0) [0|0] "" Vector__XXX
 SG_ OCS1P_sandwichDisabled : 39|1@1+ (1,0) [0|0] "" Vector__XXX
 SG_ OCS1P_classificationVariant : 36|3@1+ (1,0) [0|0] "" Vector__XXX
 SG_ OCS1P_classificationHoldState : 33|3@1+ (1,0) [0|0] "" Vector__XXX
 SG_ OCS1P_classificationExtHold : 32|1@1+ (1,0) [0|0] "" Vector__XXX
 SG_ OCS1P_cushionStable : 31|1@1+ (1,0) [0|0] "" Vector__XXX
 SG_ OCS1P_classificationHeld : 30|1@1+ (1,0) [0|0] "" Vector__XXX
 SG_ OCS1P_occupantClassificationCap : 25|3@1+ (1,0) [0|0] "" Vector__XXX
 SG_ OCS1P_occupantClassificationRawCap : 22|3@1+ (1,0) [0|0] "" Vector__XXX
 SG_ OCS1P_occupantClassificationSelf : 19|3@1+ (1,0) [0|0] "" Vector__XXX
 SG_ OCS1P_occupantClassificationRaw : 16|3@1+ (1,0) [0|0] "" Vector__XXX
 SG_ OCS1P_triggerSnapshot : 11|5@1+ (1,0) [0|0] "" Vector__XXX
 SG_ OCS1P_occupiedState : 9|2@1+ (1,0) [0|0] "" Vector__XXX
 SG_ OCS1P_occupantClassificationQF : 8|1@1+ (1,0) [0|0] "" Vector__XXX
 SG_ OCS1P_occupantClassification : 0|8@1+ (1,0) [0|0] "" Vector__XXX

BO_ 783 OCS1P_debugCushionMutCNTComp: 6 Vector__XXX
 SG_ OCS1P_deltaFreqCushionMut : 32|16@1- (1,0) [0|0] "" Vector__XXX
 SG_ OCS1P_cushionMutCNTFreqComp : 0|16@1+ (1,0) [0|0] "" Vector__XXX

BO_ 803 VCRIGHT_CPULoad: 5 Vector__XXX
 SG_ VCRIGHT_CPULoad1000msTask : 32|8@1+ (1,0) [0|0] "" Vector__XXX
 SG_ VCRIGHT_CPULoad100msTask : 24|8@1+ (1,0) [0|0] "" Vector__XXX
 SG_ VCRIGHT_CPULoad10msTask : 16|8@1+ (1,0) [0|0] "" Vector__XXX
 SG_ VCRIGHT_CPULoad1msTask : 8|8@1+ (1,0) [0|0] "" Vector__XXX
 SG_ VCRIGHT_CPULoadTotal : 0|8@1+ (1,0) [0|0] "" Vector__XXX

BO_ 804 UI_gpsTime: 8 Vector__XXX
 SG_ UI_gpsTime : 0|64@1+ (1,0) [0|0] "" Vector__XXX

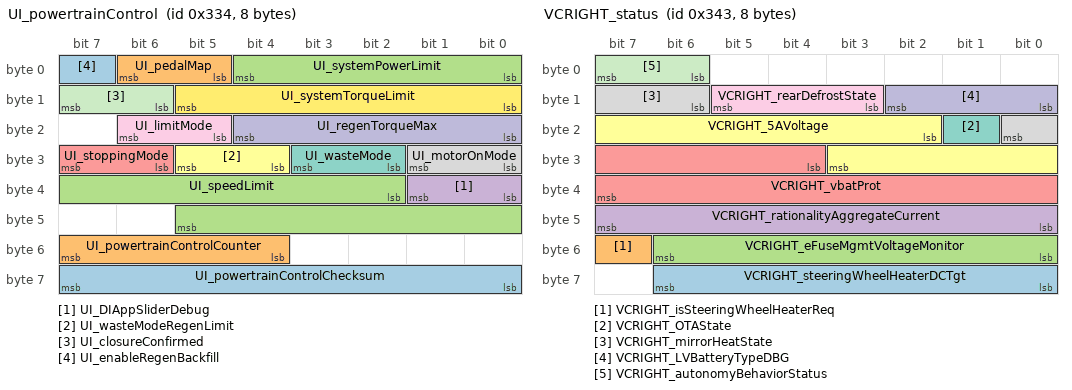
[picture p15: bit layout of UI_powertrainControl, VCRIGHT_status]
BO_ 820 UI_powertrainControl: 8 Vector__XXX
 SG_ UI_powertrainControlChecksum : 56|8@1+ (1,0) [0|0] "" Vector__XXX
 SG_ UI_powertrainControlCounter : 52|4@1+ (1,0) [0|0] "" Vector__XXX
 SG_ UI_speedLimit : 34|12@1+ (0.1,0) [0|0] "" Vector__XXX
 SG_ UI_DIAppSliderDebug : 32|2@1+ (1,0) [0|0] "" Vector__XXX
 SG_ UI_stoppingMode : 30|2@1+ (1,0) [0|0] "" Vector__XXX
 SG_ UI_wasteModeRegenLimit : 28|2@1+ (1,0) [0|0] "" Vector__XXX
 SG_ UI_wasteMode : 26|2@1+ (1,0) [0|0] "" Vector__XXX
 SG_ UI_motorOnMode : 24|2@1+ (1,0) [0|0] "" Vector__XXX
 SG_ UI_limitMode : 21|2@1+ (1,0) [0|0] "" Vector__XXX
 SG_ UI_regenTorqueMax : 16|5@1+ (5,0) [0|0] "" Vector__XXX
 SG_ UI_closureConfirmed : 14|2@1+ (1,0) [0|0] "" Vector__XXX
 SG_ UI_systemTorqueLimit : 8|6@1+ (150,1000) [0|0] "" Vector__XXX
 SG_ UI_enableRegenBackfill : 7|1@1+ (1,0) [0|0] "" Vector__XXX
 SG_ UI_pedalMap : 5|2@1+ (1,0) [0|0] "" Vector__XXX
 SG_ UI_systemPowerLimit : 0|5@1+ (20,20) [0|0] "" Vector__XXX

BO_ 829 CP_plcInfo: 8 Vector__XXX
 SG_ CP_plcPibCrc : 32|32@1+ (1,0) [0|0] "" Vector__XXX
 SG_ CP_plcFwCrc : 0|32@1+ (1,0) [0|0] "" Vector__XXX

BO_ 835 VCRIGHT_status: 8 Vector__XXX
 SG_ VCRIGHT_steeringWheelHeaterDCTgt : 56|7@1+ (0.01,0) [0|0] "" Vector__XXX
 SG_ VCRIGHT_isSteeringWheelHeaterReq : 55|1@1+ (1,0) [0|0] "" Vector__XXX
 SG_ VCRIGHT_eFuseMgmtVoltageMonitor : 48|7@1+ (0.125,0) [0|0] "" Vector__XXX
 SG_ VCRIGHT_rationalityAggregateCurrent : 40|8@1+ (0.5,0) [0|0] "" Vector__XXX
 SG_ VCRIGHT_vbatProt : 28|12@1+ (0.005443676098,0) [0|0] "" Vector__XXX
 SG_ VCRIGHT_5AVoltage : 18|10@1+ (0.005443676098,0) [0|0] "" Vector__XXX
 SG_ VCRIGHT_OTAState : 17|1@1+ (1,0) [0|0] "" Vector__XXX
 SG_ VCRIGHT_mirrorHeatState : 14|3@1+ (1,0) [0|0] "" Vector__XXX
 SG_ VCRIGHT_rearDefrostState : 11|3@1+ (1,0) [0|0] "" Vector__XXX
 SG_ VCRIGHT_LVBatteryTypeDBG : 8|3@1+ (1,0) [0|0] "" Vector__XXX
 SG_ VCRIGHT_autonomyBehaviorStatus : 6|2@1+ (1,0) [0|0] "" Vector__XXX

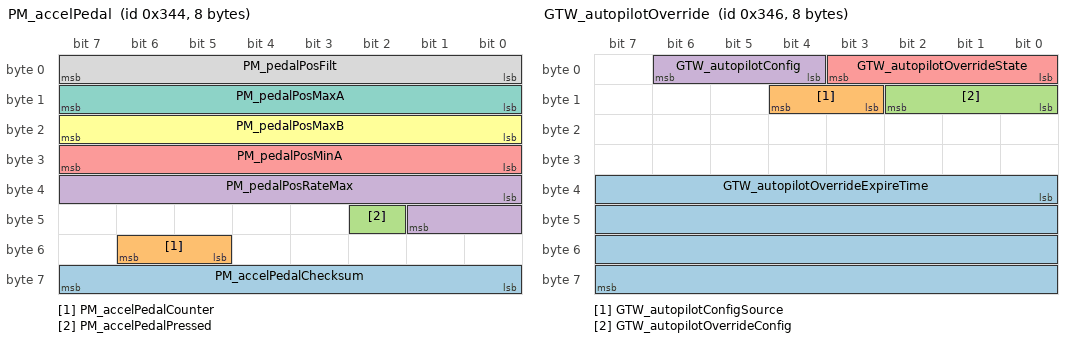
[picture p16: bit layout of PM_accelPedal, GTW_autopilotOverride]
BO_ 836 PM_accelPedal: 8 Vector__XXX
 SG_ PM_accelPedalChecksum : 56|8@1+ (1,0) [0|0] "" Vector__XXX
 SG_ PM_accelPedalCounter : 53|2@1+ (1,0) [0|0] "" Vector__XXX
 SG_ PM_accelPedalPressed : 42|1@1+ (1,0) [0|0] "" Vector__XXX
 SG_ PM_pedalPosRateMax : 32|10@1+ (3,0) [0|0] "" Vector__XXX
 SG_ PM_pedalPosMinA : 24|8@1+ (0.4,0) [0|0] "" Vector__XXX
 SG_ PM_pedalPosMaxB : 16|8@1+ (0.4,0) [0|0] "" Vector__XXX
 SG_ PM_pedalPosMaxA : 8|8@1+ (0.4,0) [0|0] "" Vector__XXX
 SG_ PM_pedalPosFilt : 0|8@1+ (0.4,0) [0|0] "" Vector__XXX

BO_ 838 GTW_autopilotOverride: 8 Vector__XXX
 SG_ GTW_autopilotOverrideExpireTime : 32|32@1+ (1,0) [0|0] "" Vector__XXX
 SG_ GTW_autopilotConfigSource : 11|2@1+ (1,0) [0|0] "" Vector__XXX
 SG_ GTW_autopilotOverrideConfig : 8|3@1+ (1,0) [0|0] "" Vector__XXX
 SG_ GTW_autopilotConfig : 4|3@1+ (1,0) [0|0] "" Vector__XXX
 SG_ GTW_autopilotOverrideState : 0|4@1+ (1,0) [0|0] "" Vector__XXX

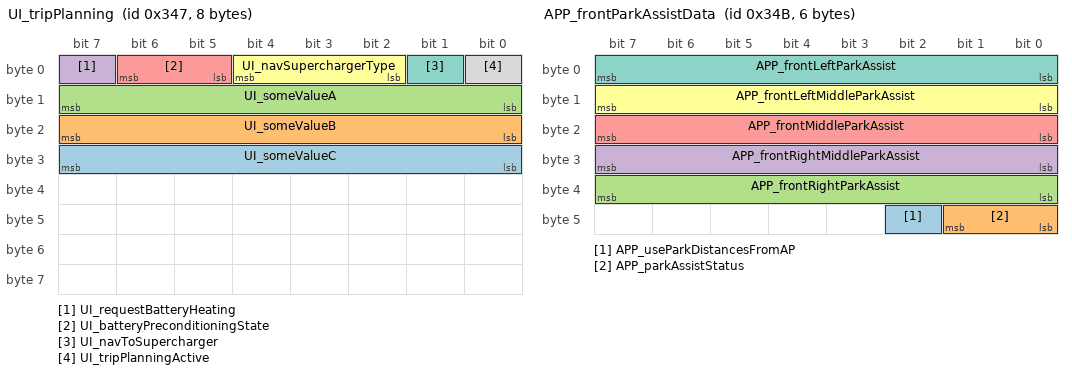
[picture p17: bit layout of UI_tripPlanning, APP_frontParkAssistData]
BO_ 839 UI_tripPlanning: 8 VEH
 SG_ UI_someValueC : 24|8@1+ (1,0) [0|255] ""  X
 SG_ UI_someValueB : 16|8@1+ (1,0) [0|255] ""  X
 SG_ UI_someValueA : 8|8@1+ (1,0) [0|255] ""  X
 SG_ UI_requestBatteryHeating : 7|1@1+ (1,0) [0|1] ""  X
 SG_ UI_batteryPreconditioningState : 5|2@1+ (1,0) [0|3] ""  X
 SG_ UI_navSuperchargerType : 2|3@1+ (1,0) [0|7] ""  X
 SG_ UI_navToSupercharger : 1|1@1+ (1,0) [0|1] ""  X
 SG_ UI_tripPlanningActive : 0|1@1+ (1,0) [0|1] ""  X

BO_ 842 VCSEC_NFCDebug: 8 Vector__XXX
 SG_ VCSEC_BPillarNFCStateReasonL m0 : 60|3@1+ (1,0) [0|0] "" Vector__XXX
 SG_ VCSEC_BPillarNFCStateReasonR m1 : 60|3@1+ (1,0) [0|0] "" Vector__XXX
 SG_ VCSEC_CenterNFCStateReason m2 : 60|4@1+ (1,0) [0|0] "" Vector__XXX
 SG_ VCSEC_BPillarNFCAntennaCalResultL m0 : 52|8@1+ (1,0) [0|0] "" Vector__XXX
 SG_ VCSEC_BPillarNFCAntennaCalResultR m1 : 52|8@1+ (1,0) [0|0] "" Vector__XXX
 SG_ VCSEC_CenterNFCAntennaCalResult m2 : 52|8@1+ (1,0) [0|0] "" Vector__XXX
 SG_ VCSEC_BPillarNFCDevLayerStateL m0 : 44|8@1+ (1,0) [0|0] "" Vector__XXX
 SG_ VCSEC_BPillarNFCDevLayerStateR m1 : 44|8@1+ (1,0) [0|0] "" Vector__XXX
 SG_ VCSEC_CenterNFCDevLayerState m2 : 44|8@1+ (1,0) [0|0] "" Vector__XXX
 SG_ VCSEC_BPillarNFCAmplitudeL m0 : 36|8@1+ (1,0) [0|0] "" Vector__XXX
 SG_ VCSEC_BPillarNFCAmplitudeR m1 : 36|8@1+ (1,0) [0|0] "" Vector__XXX
 SG_ VCSEC_CenterNFCAmplitude m2 : 36|8@1+ (1,0) [0|0] "" Vector__XXX
 SG_ VCSEC_BPillarNFCReaderStateL m0 : 28|2@1+ (1,0) [0|0] "" Vector__XXX
 SG_ VCSEC_BPillarNFCReaderStateR m1 : 28|2@1+ (1,0) [0|0] "" Vector__XXX
 SG_ VCSEC_CenterNFCReaderState m2 : 28|2@1+ (1,0) [0|0] "" Vector__XXX
 SG_ VCSEC_CenterNFCPhase m3 : 19|8@1+ (1,0) [0|0] "" Vector__XXX
 SG_ VCSEC_BPillarNFCWakeUpCounterL m0 : 12|16@1+ (1,0) [0|0] "" Vector__XXX
 SG_ VCSEC_BPillarNFCWakeUpCounterR m1 : 12|16@1+ (1,0) [0|0] "" Vector__XXX
 SG_ VCSEC_CenterNFCCardATQa m2 : 12|16@1+ (1,0) [0|0] "" Vector__XXX
 SG_ VCSEC_BPillarNFCPhaseR m3 : 11|8@1+ (1,0) [0|0] "" Vector__XXX
 SG_ VCSEC_BPillarNFCTrimSettingL m0 : 8|4@1+ (1,0) [0|0] "" Vector__XXX
 SG_ VCSEC_BPillarNFCTrimSettingR m1 : 8|4@1+ (1,0) [0|0] "" Vector__XXX
 SG_ VCSEC_CenterNFCTrimSetting m2 : 8|4@1+ (1,0) [0|0] "" Vector__XXX
 SG_ VCSEC_BPillarNFCCardUIDSizeL m0 : 4|4@1+ (1,0) [0|0] "" Vector__XXX
 SG_ VCSEC_BPillarNFCCardUIDSizeR m1 : 4|4@1+ (1,0) [0|0] "" Vector__XXX
 SG_ VCSEC_CenterNFCCardUIDSize m2 : 4|4@1+ (1,0) [0|0] "" Vector__XXX
 SG_ VCSEC_BPillarNFCCardCollisionL m0 : 3|1@1+ (1,0) [0|0] "" Vector__XXX
 SG_ VCSEC_BPillarNFCCardCollisionR m1 : 3|1@1+ (1,0) [0|0] "" Vector__XXX
 SG_ VCSEC_BPillarNFCPhaseL m3 : 3|8@1+ (1,0) [0|0] "" Vector__XXX
 SG_ VCSEC_CenterNFCCardCollision m2 : 3|1@1+ (1,0) [0|0] "" Vector__XXX
 SG_ VCSEC_NFCReaderIndexDebug M : 0|2@1+ (1,0) [0|0] "" Vector__XXX

BO_ 843 APP_frontParkAssistData: 6 Vector__XXX
 SG_ APP_useParkDistancesFromAP : 42|1@1+ (1,0) [0|0] "" Vector__XXX
 SG_ APP_parkAssistStatus : 40|2@1+ (1,0) [0|0] "" Vector__XXX
 SG_ APP_frontRightParkAssist : 32|8@1+ (1,0) [0|0] "" Vector__XXX
 SG_ APP_frontRightMiddleParkAssist : 24|8@1+ (1,0) [0|0] "" Vector__XXX
 SG_ APP_frontMiddleParkAssist : 16|8@1+ (1,0) [0|0] "" Vector__XXX
 SG_ APP_frontLeftMiddleParkAssist : 8|8@1+ (1,0) [0|0] "" Vector__XXX
 SG_ APP_frontLeftParkAssist : 0|8@1+ (1,0) [0|0] "" Vector__XXX

BO_ 847 OCS1P_debugCushionSelfCNTComp: 8 Vector__XXX
 SG_ OCS1P_deltaCapCushionSelf : 48|16@1- (0.0025,0) [0|0] "" Vector__XXX
 SG_ OCS1P_deltaFreqCushionSelf : 32|16@1- (1,0) [0|0] "" Vector__XXX
 SG_ OCS1P_cushionSelfCNTCap : 16|16@1+ (0.005,0) [0|0] "" Vector__XXX
 SG_ OCS1P_cushionSelfCNTFreqComp : 0|16@1+ (1,0) [0|0] "" Vector__XXX

BO_ 852 UI_uiHealthStatus: 6 Vector__XXX
 SG_ UI_rearDisplayCompositorOk : 31|1@1+ (1,0) [0|0] "" Vector__XXX
 SG_ UI_rearDisplayWindowManagerOk : 30|1@1+ (1,0) [0|0] "" Vector__XXX
 SG_ UI_rearDisplayHardwareOk : 29|1@1+ (1,0) [0|0] "" Vector__XXX
 SG_ UI_rearDisplayCrtcOk : 28|1@1+ (1,0) [0|0] "" Vector__XXX
 SG_ UI_rearDisplaySM : 25|3@1+ (1,0) [0|0] "" Vector__XXX
 SG_ UI_rearDisplayPowerOn : 24|1@1+ (1,0) [0|0] "" Vector__XXX
 SG_ UI_rearDisplayRunning : 23|1@1+ (1,0) [0|0] "" Vector__XXX
 SG_ UI_autonomyDASServerStatus : 21|2@1+ (1,0) [0|0] "" Vector__XXX
 SG_ UI_autonomyQtCarRearStatus : 19|2@1+ (1,0) [0|0] "" Vector__XXX
 SG_ UI_autonomyQtCarStatus : 17|2@1+ (1,0) [0|0] "" Vector__XXX
 SG_ UI_autonomyConnectivtyHWOk : 16|1@1+ (1,0) [0|0] "" Vector__XXX
 SG_ UI_autonomyConnectivityStatus : 14|2@1+ (1,0) [0|0] "" Vector__XXX
 SG_ UI_autonomyRearDispStatus : 12|2@1+ (1,0) [0|0] "" Vector__XXX
 SG_ UI_autonomyCenterDispStatus : 10|2@1+ (1,0) [0|0] "" Vector__XXX
 SG_ UI_apVisualizationOk : 9|1@1+ (1,0) [0|0] "" Vector__XXX
 SG_ UI_centerDisplayCompositorOk : 8|1@1+ (1,0) [0|0] "" Vector__XXX
 SG_ UI_centerDisplayWindowManagerOk : 7|1@1+ (1,0) [0|0] "" Vector__XXX
 SG_ UI_centerDisplayHardwareOk : 6|1@1+ (1,0) [0|0] "" Vector__XXX
 SG_ UI_centerDisplayCrtcOk : 5|1@1+ (1,0) [0|0] "" Vector__XXX
 SG_ UI_centerDisplayPowerOn : 4|1@1+ (1,0) [0|0] "" Vector__XXX
 SG_ UI_centerDisplaySM : 1|3@1+ (1,0) [0|0] "" Vector__XXX
 SG_ UI_centerDisplayRunning : 0|1@1+ (1,0) [0|0] "" Vector__XXX

BO_ 853 UI_vehicleControlThermal: 7 Vector__XXX
 SG_ UI_enableAutopilotAirPurge : 49|1@1+ (1,0) [0|0] "" Vector__XXX
 SG_ UI_enableHVACAPFanHeaterControl : 48|1@1+ (1,0) [0|0] "" Vector__XXX
 SG_ UI_enableThermalPowerBudget : 46|1@1+ (1,0) [0|0] "" Vector__XXX
 SG_ UI_isAtTeslaFacility : 45|1@1+ (1,0) [0|0] "" Vector__XXX
 SG_ UI_disablePhoneChargingPads : 43|1@1+ (1,0) [0|0] "" Vector__XXX
 SG_ UI_enableHVACCompressorWasteHeat : 42|1@1+ (1,0) [0|0] "" Vector__XXX
 SG_ UI_enableDefaultApTempTarget : 41|1@1+ (1,0) [0|0] "" Vector__XXX
 SG_ UI_enableConservativeBatteryHeating : 40|1@1+ (1,0) [0|0] "" Vector__XXX
 SG_ UI_allowConvenienceFeatures : 39|1@1+ (1,0) [0|0] "" Vector__XXX
 SG_ UI_convenienceFeatureLimit : 32|7@1+ (1,0) [0|0] "" Vector__XXX
 SG_ UI_geofencedLiftgateHeight : 24|8@1+ (1,0) [0|0] "" Vector__XXX
 SG_ UI_enableCoolantDasTarget : 23|1@1+ (1,0) [0|0] "" Vector__XXX
 SG_ UI_enableThermalDriverlessSelfTest : 22|1@1+ (1,0) [0|0] "" Vector__XXX
 SG_ UI_enableEXVFastCalibration : 21|1@1+ (1,0) [0|0] "" Vector__XXX
 SG_ UI_disableHvacCameraOnlyDefog : 20|1@1+ (1,0) [0|0] "" Vector__XXX
 SG_ UI_enableUserFacingLowFlowDeliveryAlert : 19|1@1+ (1,0) [0|0] "" Vector__XXX
 SG_ UI_enableLouverAutoDetection : 18|1@1+ (1,0) [0|0] "" Vector__XXX
 SG_ UI_enableCOP1CabinHeatingBatteryHeating : 17|1@1+ (1,0) [0|0] "" Vector__XXX
 SG_ UI_enableCOP1BatteryHeating : 16|1@1+ (1,0) [0|0] "" Vector__XXX
 SG_ UI_enableIncreasedEvapRampRate : 15|1@1+ (1,0) [0|0] "" Vector__XXX
 SG_ UI_enableCOP1HighSHOperation : 14|1@1+ (1,0) [0|0] "" Vector__XXX
 SG_ UI_enableCompLiquidPumpOut : 13|1@1+ (1,0) [0|0] "" Vector__XXX
 SG_ UI_disableHVPTThermalLoads : 12|1@1+ (1,0) [0|0] "" Vector__XXX
 SG_ UI_inletActiveCoolTarget : 5|7@1+ (1,0) [0|0] "" Vector__XXX
 SG_ UI_coolantFlowRequest : 0|5@1+ (1,0) [0|0] "" Vector__XXX

BO_ 863 BMS_gridFormControl: 1 Vector__XXX
 SG_ BMS_gridFormOutletRequest : 2|2@1+ (1,0) [0|0] "" Vector__XXX
 SG_ BMS_weldCheckCpRequest : 1|1@1+ (1,0) [0|0] "" Vector__XXX
 SG_ BMS_gridFormCpRequest : 0|1@1+ (1,0) [0|0] "" Vector__XXX

BO_ 865 VCFRONT_CPULoad: 5 Vector__XXX
 SG_ VCFRONT_CPULoad1000msTask : 32|8@1+ (1,0) [0|0] "" Vector__XXX
 SG_ VCFRONT_CPULoad100msTask : 24|8@1+ (1,0) [0|0] "" Vector__XXX
 SG_ VCFRONT_CPULoad10msTask : 16|8@1+ (1,0) [0|0] "" Vector__XXX
 SG_ VCFRONT_CPULoad1msTask : 8|8@1+ (1,0) [0|0] "" Vector__XXX
 SG_ VCFRONT_CPULoadTotal : 0|8@1+ (1,0) [0|0] "" Vector__XXX

BO_ 866 VCLEFT_crashStatus: 3 Vector__XXX
 SG_ VCLEFT_crashUnlockOverrideSet : 16|1@1+ (1,0) [0|0] "" Vector__XXX
 SG_ VCLEFT_crashNumSwitchesDisabled : 8|8@1+ (1,0) [0|0] "" Vector__XXX
 SG_ VCLEFT_crashState : 4|2@1+ (1,0) [0|0] "" Vector__XXX
 SG_ VCLEFT_crashDetectedType : 0|2@1+ (1,0) [0|0] "" Vector__XXX

BO_ 868 PCS_thermalControl: 4 Vector__XXX
 SG_ PCS_coolantTempEstimated : 18|11@1- (0.1,40) [0|0] "" Vector__XXX
 SG_ PCS_chgNoFlowTetheringStatus : 16|2@1+ (1,0) [0|0] "" Vector__XXX
 SG_ PCS_tempInletTargetCoolActive : 9|7@1+ (1,0) [0|0] "" Vector__XXX
 SG_ PCS_flowRequest : 0|9@1+ (0.1,0) [0|0] "" Vector__XXX

BO_ 870 CMPD_info: 8 Vector__XXX
 SG_ CMPD_infoComponentId m10 : 48|16@1+ (1,0) [0|0] "" Vector__XXX
 SG_ CMPD_infoSubUsageId m11 : 48|16@1+ (1,0) [0|0] "" Vector__XXX
 SG_ CMPD_infoBootCrc m20 : 32|32@1+ (1,0) [0|0] "" Vector__XXX
 SG_ CMPD_infoHardwareId m10 : 32|16@1+ (1,0) [0|0] "" Vector__XXX
 SG_ CMPD_infoUsageId m11 : 32|16@1+ (1,0) [0|0] "" Vector__XXX
 SG_ CMPD_infoAppCrc m13 : 39|32@0+ (1,0) [0|0] "" Vector__XXX
 SG_ CMPD_infoAssemblyId m11 : 24|8@1+ (1,0) [0|0] "" Vector__XXX
 SG_ CMPD_infoBuildConfigId m10 : 16|16@1+ (1,0) [0|0] "" Vector__XXX
 SG_ CMPD_infoPcbaId m11 : 16|8@1+ (1,0) [0|0] "" Vector__XXX
 SG_ CMPD_infoBootUdsProtoVersion m20 : 8|8@1+ (1,0) [0|0] "" Vector__XXX
 SG_ CMPD_infoBuildType m10 : 8|8@1+ (1,0) [0|0] "" Vector__XXX
 SG_ CMPD_infoPlatformType m13 : 8|8@1+ (1,0) [0|0] "" Vector__XXX
 SG_ CMPD_infoIndex M : 0|8@1+ (1,0) [0|0] "" Vector__XXX

BO_ 871 DI_alertMatrix1: 8 Vector__XXX
 SG_ DI_a064_pmsrmUnitMiaWithHvDown : 63|1@1+ (1,0) [0|0] "" Vector__XXX
 SG_ DI_a063_systemGracefulPowerOff : 62|1@1+ (1,0) [0|0] "" Vector__XXX
 SG_ DI_a062_systemLimpMode : 61|1@1+ (1,0) [0|0] "" Vector__XXX
 SG_ DI_a061_canHardwareBusE : 60|1@1+ (1,0) [0|0] "" Vector__XXX
 SG_ DI_a060_canOverrunBusE : 59|1@1+ (1,0) [0|0] "" Vector__XXX
 SG_ DI_a059_canDataBusE : 58|1@1+ (1,0) [0|0] "" Vector__XXX
 SG_ DI_a058_canHardwareBusD : 57|1@1+ (1,0) [0|0] "" Vector__XXX
 SG_ DI_a057_canOverrunBusD : 56|1@1+ (1,0) [0|0] "" Vector__XXX
 SG_ DI_a056_canDataBusD : 55|1@1+ (1,0) [0|0] "" Vector__XXX
 SG_ DI_a055_canHardwareBusC : 54|1@1+ (1,0) [0|0] "" Vector__XXX
 SG_ DI_a054_canOverrunBusC : 53|1@1+ (1,0) [0|0] "" Vector__XXX
 SG_ DI_a053_canDataBusC : 52|1@1+ (1,0) [0|0] "" Vector__XXX
 SG_ DI_a052_dirMIA : 51|1@1+ (1,0) [0|0] "" Vector__XXX
 SG_ DI_a051_batteryOvercurrent : 50|1@1+ (1,0) [0|0] "" Vector__XXX
 SG_ DI_a048_ecuLogAvailable : 47|1@1+ (1,0) [0|0] "" Vector__XXX
 SG_ DI_a043_pmrMIA : 42|1@1+ (1,0) [0|0] "" Vector__XXX
 SG_ DI_a042_pmfMIA : 41|1@1+ (1,0) [0|0] "" Vector__XXX
 SG_ DI_a041_driverBrakeApplyStuck : 40|1@1+ (1,0) [0|0] "" Vector__XXX
 SG_ DI_a040_difMIA : 39|1@1+ (1,0) [0|0] "" Vector__XXX
 SG_ DI_a036_sysStandbyUnitLimitedWait : 35|1@1+ (1,0) [0|0] "" Vector__XXX
 SG_ DI_a031_closureAccelerationLimit : 30|1@1+ (1,0) [0|0] "" Vector__XXX
 SG_ DI_a027_steeringAngleOffsetService : 26|1@1+ (1,0) [0|0] "" Vector__XXX
 SG_ DI_a026_parkPressedWithHighAPedal : 25|1@1+ (1,0) [0|0] "" Vector__XXX
 SG_ DI_a025_regenBackfillUnavailable : 24|1@1+ (1,0) [0|0] "" Vector__XXX
 SG_ DI_a024_holdNForNeutral : 23|1@1+ (1,0) [0|0] "" Vector__XXX
 SG_ DI_a023_carNotParked : 22|1@1+ (1,0) [0|0] "" Vector__XXX
 SG_ DI_a022_hw5vSupplyUV : 21|1@1+ (1,0) [0|0] "" Vector__XXX
 SG_ DI_a021_packOvervoltage : 20|1@1+ (1,0) [0|0] "" Vector__XXX
 SG_ DI_a019_hwAccelPedalPower : 18|1@1+ (1,0) [0|0] "" Vector__XXX
 SG_ DI_a018_hwLVSupplyUV : 17|1@1+ (1,0) [0|0] "" Vector__XXX
 SG_ DI_a017_hwPedalMonitor : 16|1@1+ (1,0) [0|0] "" Vector__XXX
 SG_ DI_a016_parkRequestByPM : 15|1@1+ (1,0) [0|0] "" Vector__XXX
 SG_ DI_a015_immobilizer : 14|1@1+ (1,0) [0|0] "" Vector__XXX
 SG_ DI_a013_eccError : 12|1@1+ (1,0) [0|0] "" Vector__XXX
 SG_ DI_a012_accel5VSupply : 11|1@1+ (1,0) [0|0] "" Vector__XXX
 SG_ DI_a010_unintendedReset : 9|1@1+ (1,0) [0|0] "" Vector__XXX
 SG_ DI_a005_stalkPanicked : 4|1@1+ (1,0) [0|0] "" Vector__XXX
 SG_ DI_a002_parkButtonDuringStalkReq : 1|1@1+ (1,0) [0|0] "" Vector__XXX
 SG_ DI_a001_frunkSpeedLimitActive : 0|1@1+ (1,0) [0|0] "" Vector__XXX

BO_ 893 CP_thermalStatus: 8 Vector__XXX
 SG_ CP_pinTemp3Velocity m0 : 53|10@1- (0.15748,0) [0|0] "" Vector__XXX
 SG_ CP_pinTemp2Velocity m0 : 43|10@1- (0.15748,0) [0|0] "" Vector__XXX
 SG_ CP_pinTemp4Velocity m1 : 40|10@1- (0.15748,0) [0|0] "" Vector__XXX
 SG_ CP_pinTemp1Velocity m0 : 33|10@1- (0.15748,0) [0|0] "" Vector__XXX
 SG_ CP_pinTemperature4 m1 : 32|8@1+ (0.8039215686,-55) [0|0] "" Vector__XXX
 SG_ CP_acPinTemperature2 m0 : 25|8@1+ (0.8039215686,-55) [0|0] "" Vector__XXX
 SG_ CP_pinTemperature3 m1 : 24|8@1+ (0.8039215686,-55) [0|0] "" Vector__XXX
 SG_ CP_acPinTemperature m0 : 17|8@1+ (0.8039215686,-55) [0|0] "" Vector__XXX
 SG_ CP_pinTemperature2 m1 : 16|8@1+ (0.8039215686,-55) [0|0] "" Vector__XXX
 SG_ CP_dcPinTemperature2 m0 : 9|8@1+ (0.8039215686,-55) [0|0] "" Vector__XXX
 SG_ CP_pinTemperature1 m1 : 8|8@1+ (0.8039215686,-55) [0|0] "" Vector__XXX
 SG_ CP_dcPinTemperature m0 : 1|8@1+ (0.8039215686,-55) [0|0] "" Vector__XXX
 SG_ CP_thermalStatusSelect M : 0|1@1+ (1,0) [0|0] "" Vector__XXX

BO_ 898 VCLEFT_CPULoad: 5 Vector__XXX
 SG_ VCLEFT_CPULoad1000msTask : 32|8@1+ (1,0) [0|0] "" Vector__XXX
 SG_ VCLEFT_CPULoad100msTask : 24|8@1+ (1,0) [0|0] "" Vector__XXX
 SG_ VCLEFT_CPULoad10msTask : 16|8@1+ (1,0) [0|0] "" Vector__XXX
 SG_ VCLEFT_CPULoad1msTask : 8|8@1+ (1,0) [0|0] "" Vector__XXX
 SG_ VCLEFT_CPULoadTotal : 0|8@1+ (1,0) [0|0] "" Vector__XXX

BO_ 902 PMR_alertMatrix1: 8 Vector__XXX
 SG_ PMR_a064_torqueIntervention : 63|1@1+ (1,0) [0|0] "" Vector__XXX
 SG_ PMR_a062_eccError : 61|1@1+ (1,0) [0|0] "" Vector__XXX
 SG_ PMR_a061_DIPMVersionMismatch : 60|1@1+ (1,0) [0|0] "" Vector__XXX
 SG_ PMR_a057_canDataBusB : 56|1@1+ (1,0) [0|0] "" Vector__XXX
 SG_ PMR_a056_canHardwareBusB : 55|1@1+ (1,0) [0|0] "" Vector__XXX
 SG_ PMR_a055_resolver : 54|1@1+ (1,0) [0|0] "" Vector__XXX
 SG_ PMR_a054_uiMIA : 53|1@1+ (1,0) [0|0] "" Vector__XXX
 SG_ PMR_a053_vcfrontMIA : 52|1@1+ (1,0) [0|0] "" Vector__XXX
 SG_ PMR_a045_motorMovementDetected : 44|1@1+ (1,0) [0|0] "" Vector__XXX
 SG_ PMR_a042_gtwMIA : 41|1@1+ (1,0) [0|0] "" Vector__XXX
 SG_ PMR_a040_pmMIA : 39|1@1+ (1,0) [0|0] "" Vector__XXX
 SG_ PMR_a039_disMIA : 38|1@1+ (1,0) [0|0] "" Vector__XXX
 SG_ PMR_a037_hvpMIA : 36|1@1+ (1,0) [0|0] "" Vector__XXX
 SG_ PMR_a036_preWatchdog : 35|1@1+ (1,0) [0|0] "" Vector__XXX
 SG_ PMR_a035_udsTransactionInitiated : 34|1@1+ (1,0) [0|0] "" Vector__XXX
 SG_ PMR_a034_trqCrossCheck : 33|1@1+ (1,0) [0|0] "" Vector__XXX
 SG_ PMR_a033_selfTest : 32|1@1+ (1,0) [0|0] "" Vector__XXX
 SG_ PMR_a032_registerConfigError : 31|1@1+ (1,0) [0|0] "" Vector__XXX
 SG_ PMR_a031_highStackUsage : 30|1@1+ (1,0) [0|0] "" Vector__XXX
 SG_ PMR_a028_torqueCmdError : 27|1@1+ (1,0) [0|0] "" Vector__XXX
 SG_ PMR_a027_torqueEstimationOutOfBounds : 26|1@1+ (1,0) [0|0] "" Vector__XXX
 SG_ PMR_a026_diHeartBeatMIA : 25|1@1+ (1,0) [0|0] "" Vector__XXX
 SG_ PMR_a025_unintendedReset : 24|1@1+ (1,0) [0|0] "" Vector__XXX
 SG_ PMR_a019_statorTempIrrational : 18|1@1+ (1,0) [0|0] "" Vector__XXX
 SG_ PMR_a018_encoderIrrational : 17|1@1+ (1,0) [0|0] "" Vector__XXX
 SG_ PMR_a017_brakeMIA : 16|1@1+ (1,0) [0|0] "" Vector__XXX
 SG_ PMR_a013_canHardwareBusA : 12|1@1+ (1,0) [0|0] "" Vector__XXX
 SG_ PMR_a012_canDataBusA : 11|1@1+ (1,0) [0|0] "" Vector__XXX
 SG_ PMR_a011_phaseCurrentIrrational : 10|1@1+ (1,0) [0|0] "" Vector__XXX
 SG_ PMR_a010_diMIA : 9|1@1+ (1,0) [0|0] "" Vector__XXX
 SG_ PMR_a008_memoryError : 7|1@1+ (1,0) [0|0] "" Vector__XXX
 SG_ PMR_a005_torqueInNeutralOrPark : 4|1@1+ (1,0) [0|0] "" Vector__XXX
 SG_ PMR_a004_excessiveDecelTorque : 3|1@1+ (1,0) [0|0] "" Vector__XXX
 SG_ PMR_a003_excessiveReversalTorque : 2|1@1+ (1,0) [0|0] "" Vector__XXX
 SG_ PMR_a002_excessiveAccelTorque : 1|1@1+ (1,0) [0|0] "" Vector__XXX
 SG_ PMR_a001_absoluteTorque : 0|1@1+ (1,0) [0|0] "" Vector__XXX

BO_ 907 APP_rearParkAssistData: 5 Vector__XXX
 SG_ APP_rearRightParkAssist : 32|8@1+ (1,0) [0|0] "" Vector__XXX
 SG_ APP_rearRightMiddleParkAssist : 24|8@1+ (1,0) [0|0] "" Vector__XXX
 SG_ APP_rearMiddleParkAssist : 16|8@1+ (1,0) [0|0] "" Vector__XXX
 SG_ APP_rearLeftMiddleParkAssist : 8|8@1+ (1,0) [0|0] "" Vector__XXX
 SG_ APP_rearLeftParkAssist : 0|8@1+ (1,0) [0|0] "" Vector__XXX

BO_ 912 UI_gridFormControl: 2 Vector__XXX
 SG_ UI_powershareRequest : 10|2@1+ (1,0) [0|0] "" Vector__XXX
 SG_ UI_v2lFeatureRequest : 9|1@1+ (1,0) [0|0] "" Vector__XXX
 SG_ UI_dischargeTerminationPct : 0|8@1+ (1,0) [0|0] "" Vector__XXX

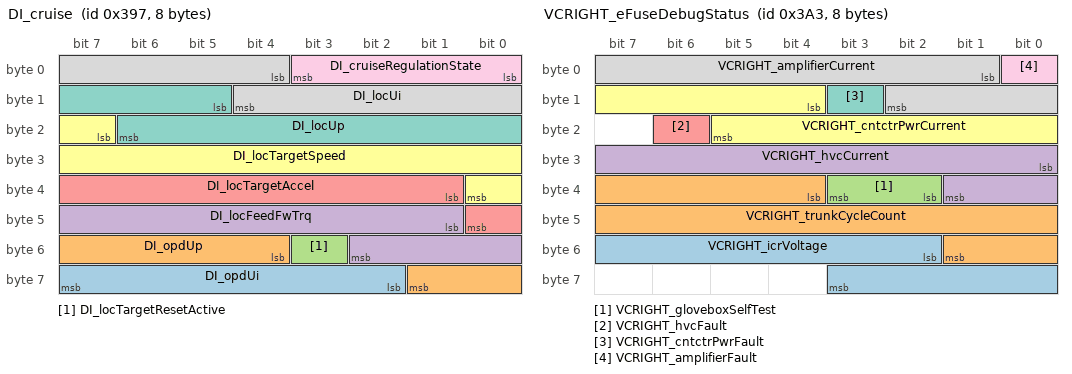
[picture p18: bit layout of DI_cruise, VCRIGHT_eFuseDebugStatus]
BO_ 919 DI_cruise: 8 Vector__XXX
 SG_ DI_opdUi : 58|6@1- (40,0) [0|0] "" Vector__XXX
 SG_ DI_opdUp : 52|6@1- (40,0) [0|0] "" Vector__XXX
 SG_ DI_locTargetResetActive : 51|1@1+ (1,0) [0|0] "" Vector__XXX
 SG_ DI_locFeedFwTrq : 41|10@1- (19.569471624266146,0) [0|0] "" Vector__XXX
 SG_ DI_locTargetAccel : 33|8@1- (0.1094488188976378,-1.5322834645669292) [0|0] "" Vector__XXX
 SG_ DI_locTargetSpeed : 23|10@1- (0.25,20) [0|0] "" Vector__XXX
 SG_ DI_locUp : 13|10@1- (19.569471624266146,0) [0|0] "" Vector__XXX
 SG_ DI_locUi : 4|9@1- (19.607843137254903,0) [0|0] "" Vector__XXX
 SG_ DI_cruiseRegulationState : 0|4@1+ (1,0) [0|0] "" Vector__XXX

BO_ 922 VCSEC_RSSI: 8 Vector__XXX
 SG_ VCSEC_RSSI2ConnectionType m1 : 61|2@1+ (1,0) [0|0] "" Vector__XXX
 SG_ VCSEC_BLEDevicePresence0 m0 : 59|5@1+ (1,0) [0|0] "" Vector__XXX
 SG_ VCSEC_RSSI1ConnectionType m1 : 59|2@1+ (1,0) [0|0] "" Vector__XXX
 SG_ VCSEC_UnknownBLEDevicePresent m0 : 58|1@1+ (1,0) [0|0] "" Vector__XXX
 SG_ VCSEC_RSSI0ConnectionType m1 : 57|2@1+ (1,0) [0|0] "" Vector__XXX
 SG_ VCSEC_BLEDevicePresence3 m1 : 52|5@1+ (1,0) [0|0] "" Vector__XXX
 SG_ VCSEC_rearBLEAntennaRSSI1 m0 : 50|8@1- (1,0) [0|0] "" Vector__XXX
 SG_ VCSEC_BLEDevicePresence2 m1 : 47|5@1+ (1,0) [0|0] "" Vector__XXX
 SG_ VCSEC_BLEDevicePresence1 m1 : 42|5@1+ (1,0) [0|0] "" Vector__XXX
 SG_ VCSEC_rightBLEAntennaRSSI1 m0 : 42|8@1- (1,0) [0|0] "" Vector__XXX
 SG_ VCSEC_centerBLEAntennaRSSI2 m1 : 34|8@1- (1,0) [0|0] "" Vector__XXX
 SG_ VCSEC_leftBLEAntennaRSSI1 m0 : 34|8@1- (1,0) [0|0] "" Vector__XXX
 SG_ VCSEC_centerBLEAntennaRSSI0 m0 : 26|8@1- (1,0) [0|0] "" Vector__XXX
 SG_ VCSEC_rearBLEAntennaRSSI2 m1 : 26|8@1- (1,0) [0|0] "" Vector__XXX
 SG_ VCSEC_rearBLEAntennaRSSI0 m0 : 18|8@1- (1,0) [0|0] "" Vector__XXX
 SG_ VCSEC_rightBLEAntennaRSSI2 m1 : 18|8@1- (1,0) [0|0] "" Vector__XXX
 SG_ VCSEC_leftBLEAntennaRSSI2 m1 : 10|8@1- (1,0) [0|0] "" Vector__XXX
 SG_ VCSEC_rightBLEAntennaRSSI0 m0 : 10|8@1- (1,0) [0|0] "" Vector__XXX
 SG_ VCSEC_centerBLEAntennaRSSI1 m1 : 2|8@1- (1,0) [0|0] "" Vector__XXX
 SG_ VCSEC_leftBLEAntennaRSSI0 m0 : 2|8@1- (1,0) [0|0] "" Vector__XXX
 SG_ VCSEC_RSSIIndex M : 0|2@1+ (1,0) [0|0] "" Vector__XXX

BO_ 923 DAS_status_39B: 8 Vector__XXX
 SG_ DAS_statusChecksum : 56|8@1+ (1,0) [0|0] "" Vector__XXX
 SG_ DAS_statusCounter : 52|4@1+ (1,0) [0|0] "" Vector__XXX
 SG_ DAS_summonAvailable : 51|1@1+ (1,0) [0|0] "" Vector__XXX
 SG_ DAS_autoLaneChangeState : 46|5@1+ (1,0) [0|0] "" Vector__XXX
 SG_ DAS_autopilotHandsOnState : 42|4@1+ (1,0) [0|0] "" Vector__XXX
 SG_ DAS_fleetSpeedState : 40|2@1+ (1,0) [0|0] "" Vector__XXX
 SG_ DAS_laneDepartureWarning : 37|3@1+ (1,0) [0|0] "" Vector__XXX
 SG_ DAS_sideCollisionInhibit : 36|1@1+ (1,0) [0|0] "" Vector__XXX
 SG_ DAS_sideCollisionWarning : 34|2@1+ (1,0) [0|0] "" Vector__XXX
 SG_ DAS_sideCollisionAvoid : 32|2@1+ (1,0) [0|0] "" Vector__XXX
 SG_ DAS_lssState : 29|3@1+ (1,0) [0|0] "" Vector__XXX
 SG_ DAS_summonRvsLeashReached : 28|1@1+ (1,0) [0|0] "" Vector__XXX
 SG_ DAS_summonFwdLeashReached : 27|1@1+ (1,0) [0|0] "" Vector__XXX
 SG_ DAS_autoparkActive : 26|1@1+ (1,0) [0|0] "" Vector__XXX
 SG_ DAS_autoParked : 25|1@1+ (1,0) [0|0] "" Vector__XXX
 SG_ DAS_autoparkReady : 24|1@1+ (1,0) [0|0] "" Vector__XXX
 SG_ DAS_forwardCollisionWarning : 22|2@1+ (1,0) [0|0] "" Vector__XXX
 SG_ DAS_heaterState : 21|1@1+ (1,0) [0|0] "" Vector__XXX
 SG_ DAS_visionOnlySpeedLimit : 16|5@1+ (5,0) [0|0] "" Vector__XXX
 SG_ DAS_summonClearedGate : 15|1@1+ (1,0) [0|0] "" Vector__XXX
 SG_ DAS_summonObstacle : 14|1@1+ (1,0) [0|0] "" Vector__XXX
 SG_ DAS_suppressSpeedWarning : 13|1@1+ (1,0) [0|0] "" Vector__XXX
 SG_ DAS_fusedSpeedLimit : 8|5@1+ (5,0) [0|0] "" Vector__XXX
 SG_ DAS_blindSpotRearRight : 6|2@1+ (1,0) [0|0] "" Vector__XXX
 SG_ DAS_blindSpotRearLeft : 4|2@1+ (1,0) [0|0] "" Vector__XXX
 SG_ DAS_autopilotState : 0|4@1+ (1,0) [0|0] "" Vector__XXX

BO_ 931 VCRIGHT_eFuseDebugStatus: 8 Vector__XXX
 SG_ VCRIGHT_icrVoltage : 50|10@1+ (0.02,0) [0|0] "" Vector__XXX
 SG_ VCRIGHT_trunkCycleCount : 36|14@1+ (10,0) [0|0] "" Vector__XXX
 SG_ VCRIGHT_gloveboxSelfTest : 34|2@1+ (1,0) [0|0] "" Vector__XXX
 SG_ VCRIGHT_hvcCurrent : 24|10@1+ (0.1,0) [0|0] "" Vector__XXX
 SG_ VCRIGHT_hvcFault : 22|1@1+ (1,0) [0|0] "" Vector__XXX
 SG_ VCRIGHT_cntctrPwrCurrent : 12|10@1+ (0.1,0) [0|0] "" Vector__XXX
 SG_ VCRIGHT_cntctrPwrFault : 11|1@1+ (1,0) [0|0] "" Vector__XXX
 SG_ VCRIGHT_amplifierCurrent : 1|10@1+ (0.1,0) [0|0] "" Vector__XXX
 SG_ VCRIGHT_amplifierFault : 0|1@1+ (1,0) [0|0] "" Vector__XXX

BO_ 935 DIR_alertMatrix1: 8 Vector__XXX
 SG_ DIR_a064_torqueIntervention : 63|1@1+ (1,0) [0|0] "" Vector__XXX
 SG_ DIR_a062_systemLimpMode : 61|1@1+ (1,0) [0|0] "" Vector__XXX
 SG_ DIR_a061_heatsinkSensor : 60|1@1+ (1,0) [0|0] "" Vector__XXX
 SG_ DIR_a060_heatsinkUT : 59|1@1+ (1,0) [0|0] "" Vector__XXX
 SG_ DIR_a059_heatsinkOT : 58|1@1+ (1,0) [0|0] "" Vector__XXX
 SG_ DIR_a058_ambientSensor : 57|1@1+ (1,0) [0|0] "" Vector__XXX
 SG_ DIR_a057_ambientUT : 56|1@1+ (1,0) [0|0] "" Vector__XXX
 SG_ DIR_a056_ambientOT : 55|1@1+ (1,0) [0|0] "" Vector__XXX
 SG_ DIR_a055_trqCrossCheck : 54|1@1+ (1,0) [0|0] "" Vector__XXX
 SG_ DIR_a054_driveInverterOT : 53|1@1+ (1,0) [0|0] "" Vector__XXX
 SG_ DIR_a053_unexpectedLatchState : 52|1@1+ (1,0) [0|0] "" Vector__XXX
 SG_ DIR_a052_dirMIA : 51|1@1+ (1,0) [0|0] "" Vector__XXX
 SG_ DIR_a050_noStatorSensor : 49|1@1+ (1,0) [0|0] "" Vector__XXX
 SG_ DIR_a049_statorSensorDiff : 48|1@1+ (1,0) [0|0] "" Vector__XXX
 SG_ DIR_a048_statorSensor2 : 47|1@1+ (1,0) [0|0] "" Vector__XXX
 SG_ DIR_a047_statorSensor1 : 46|1@1+ (1,0) [0|0] "" Vector__XXX
 SG_ DIR_a046_statorOT : 45|1@1+ (1,0) [0|0] "" Vector__XXX
 SG_ DIR_a045_outletSensor : 44|1@1+ (1,0) [0|0] "" Vector__XXX
 SG_ DIR_a044_outletUT : 43|1@1+ (1,0) [0|0] "" Vector__XXX
 SG_ DIR_a043_outletOT : 42|1@1+ (1,0) [0|0] "" Vector__XXX
 SG_ DIR_a042_inletSensor : 41|1@1+ (1,0) [0|0] "" Vector__XXX
 SG_ DIR_a041_sdcMIA : 40|1@1+ (1,0) [0|0] "" Vector__XXX
 SG_ DIR_a040_difMIA : 39|1@1+ (1,0) [0|0] "" Vector__XXX
 SG_ DIR_a038_busVsensor : 37|1@1+ (1,0) [0|0] "" Vector__XXX
 SG_ DIR_a037_busUV : 36|1@1+ (1,0) [0|0] "" Vector__XXX
 SG_ DIR_a036_busOV : 35|1@1+ (1,0) [0|0] "" Vector__XXX
 SG_ DIR_a035_phaseCurrentBalance : 34|1@1+ (1,0) [0|0] "" Vector__XXX
 SG_ DIR_a034_phaseBcurrentSensor : 33|1@1+ (1,0) [0|0] "" Vector__XXX
 SG_ DIR_a033_phaseAcurrentSensor : 32|1@1+ (1,0) [0|0] "" Vector__XXX
 SG_ DIR_a032_phaseBcurrentOffset : 31|1@1+ (1,0) [0|0] "" Vector__XXX
 SG_ DIR_a031_phaseAcurrentOffset : 30|1@1+ (1,0) [0|0] "" Vector__XXX
 SG_ DIR_a030_phaseCrms : 29|1@1+ (1,0) [0|0] "" Vector__XXX
 SG_ DIR_a029_phaseBrms : 28|1@1+ (1,0) [0|0] "" Vector__XXX
 SG_ DIR_a028_phaseArms : 27|1@1+ (1,0) [0|0] "" Vector__XXX
 SG_ DIR_a027_phaseCpeak : 26|1@1+ (1,0) [0|0] "" Vector__XXX
 SG_ DIR_a026_phaseBpeak : 25|1@1+ (1,0) [0|0] "" Vector__XXX
 SG_ DIR_a025_phaseApeak : 24|1@1+ (1,0) [0|0] "" Vector__XXX
 SG_ DIR_a024_selfTest : 23|1@1+ (1,0) [0|0] "" Vector__XXX
 SG_ DIR_a022_hw5vSupplyUV : 21|1@1+ (1,0) [0|0] "" Vector__XXX
 SG_ DIR_a021_hwBusOV : 20|1@1+ (1,0) [0|0] "" Vector__XXX
 SG_ DIR_a020_hwMotorEncoder : 19|1@1+ (1,0) [0|0] "" Vector__XXX
 SG_ DIR_a018_hwLVSupplyUV : 17|1@1+ (1,0) [0|0] "" Vector__XXX
 SG_ DIR_a017_hwPedalMonitor : 16|1@1+ (1,0) [0|0] "" Vector__XXX
 SG_ DIR_a016_safeStateApplied : 15|1@1+ (1,0) [0|0] "" Vector__XXX
 SG_ DIR_a015_mechSafeStateAnomaly : 14|1@1+ (1,0) [0|0] "" Vector__XXX
 SG_ DIR_a014_activeDamping : 13|1@1+ (1,0) [0|0] "" Vector__XXX
 SG_ DIR_a013_eccError : 12|1@1+ (1,0) [0|0] "" Vector__XXX
 SG_ DIR_a011_swPowerStageNotReady : 10|1@1+ (1,0) [0|0] "" Vector__XXX
 SG_ DIR_a010_unintendedReset : 9|1@1+ (1,0) [0|0] "" Vector__XXX
 SG_ DIR_a009_hwEncoderB : 8|1@1+ (1,0) [0|0] "" Vector__XXX
 SG_ DIR_a008_hwEncoderA : 7|1@1+ (1,0) [0|0] "" Vector__XXX
 SG_ DIR_a007_statorAnomalyDetected : 6|1@1+ (1,0) [0|0] "" Vector__XXX
 SG_ DIR_a006_hwPhaseCpeak : 5|1@1+ (1,0) [0|0] "" Vector__XXX
 SG_ DIR_a005_hwPhaseBpeak : 4|1@1+ (1,0) [0|0] "" Vector__XXX
 SG_ DIR_a004_hwPhaseApeak : 3|1@1+ (1,0) [0|0] "" Vector__XXX
 SG_ DIR_a003_hwPhaseCgateDrive : 2|1@1+ (1,0) [0|0] "" Vector__XXX
 SG_ DIR_a002_hwPhaseBgateDrive : 1|1@1+ (1,0) [0|0] "" Vector__XXX
 SG_ DIR_a001_hwPhaseAgateDrive : 0|1@1+ (1,0) [0|0] "" Vector__XXX

BO_ 936 VCLEFT_logging1Hz: 8 Vector__XXX
 SG_ VCLEFT_tpmsCurrent m2 : 61|3@1+ (0.01,0) [0|0] "" Vector__XXX
 SG_ VCLEFT_sideMirrorHeaterCurrent m1 : 60|4@1+ (0.5,0) [0|0] "" Vector__XXX
 SG_ VCLEFT_ocsCurrent m2 : 58|3@1+ (0.01,0) [0|0] "" Vector__XXX
 SG_ VCLEFT_sideMirrorCurrent m1 : 56|4@1+ (0.2,0) [0|0] "" Vector__XXX
 SG_ VCLEFT_vbatFused3Current m2 : 53|5@1+ (0.1,0) [0|0] "" Vector__XXX
 SG_ VCLEFT_dirDischargeCurrent m1 : 52|4@1+ (0.1,0) [0|0] "" Vector__XXX
 SG_ VCLEFT_sccmCurrent m1 : 48|4@1+ (0.05,0) [0|0] "" Vector__XXX
 SG_ VCLEFT_vbatFused0Current m2 : 48|5@1+ (0.1,0) [0|0] "" Vector__XXX
 SG_ VCLEFT_accessoryFeed2Current m2 : 43|5@1+ (0.2,0) [0|0] "" Vector__XXX
 SG_ VCLEFT_frontSeatHeatBackrestPwr m0 : 40|7@1+ (1,0) [0|0] "" Vector__XXX
 SG_ VCLEFT_swcCurrent m1 : 40|8@1+ (0.05,0) [0|0] "" Vector__XXX
 SG_ VCLEFT_accessoryFeed1Current m2 : 37|6@1+ (0.1,0) [0|0] "" Vector__XXX
 SG_ VCLEFT_bleBPillarRearHdlrCurrent m1 : 36|4@1+ (0.05,0) [0|0] "" Vector__XXX
 SG_ VCLEFT_trunkFoldFlatSwLEDCurrent m2 : 34|3@1+ (5,0) [0|0] "" Vector__XXX
 SG_ VCLEFT_usbPortsRearCurrentAvg m4 : 34|10@1+ (0.001,0) [0|0] "" Vector__XXX
 SG_ VCLEFT_frontSeatHeatCushionPwr m0 : 32|7@1+ (1,0) [0|0] "" Vector__XXX
 SG_ VCLEFT_lumbarEcuCurrent m1 : 32|4@1+ (0.1,0) [0|0] "" Vector__XXX
 SG_ VCLEFT_rearPuddleLEDCurrent m2 : 31|3@1+ (2,0) [0|0] "" Vector__XXX
 SG_ VCLEFT_frontPuddleLEDCurrent m2 : 28|3@1+ (2,0) [0|0] "" Vector__XXX
 SG_ VCLEFT_mapPocketLEDsCurrent m2 : 25|3@1+ (10,0) [0|0] "" Vector__XXX
 SG_ VCLEFT_rcmCurrent m1 : 24|7@1+ (0.025,0) [0|0] "" Vector__XXX
 SG_ VCLEFT_rgbLedIPFROutput m3 : 24|1@1+ (1,0) [0|0] "" Vector__XXX
 SG_ VCLEFT_swcResistance m0 : 24|7@1+ (0.025,0) [0|0] "" Vector__XXX
 SG_ VCLEFT_usbPortsCurrentAvg m4 : 24|10@1+ (0.001,0) [0|0] "" Vector__XXX
 SG_ VCLEFT_rgbLedIPFLOutput m3 : 23|1@1+ (1,0) [0|0] "" Vector__XXX
 SG_ VCLEFT_intDoorHandleLEDCurrent m2 : 22|3@1+ (2,0) [0|0] "" Vector__XXX
 SG_ VCLEFT_windowSwitchLEDCurrent m2 : 19|3@1+ (10,0) [0|0] "" Vector__XXX
 SG_ VCLEFT_phoneChargingFR m0 : 17|1@1+ (1,0) [0|0] "" Vector__XXX
 SG_ VCLEFT_phoneChargingFL m0 : 16|1@1+ (1,0) [0|0] "" Vector__XXX
 SG_ VCLEFT_tlcCurrent m1 : 16|6@1+ (0.5,0) [0|0] "" Vector__XXX
 SG_ VCLEFT_trunkInteriorLEDCurrent m2 : 15|4@1+ (5,0) [0|0] "" Vector__XXX
 SG_ VCLEFT_12vSocketRearCurrentAvg m4 : 13|10@1+ (0.01,0) [0|0] "" Vector__XXX
 SG_ VCLEFT_rgbLedIPFRCurrent m3 : 13|10@1+ (0.0004887585532746823,0) [0|0] "" Vector__XXX
 SG_ VCLEFT_stopReverseTurnLightCurrent m2 : 11|4@1+ (0.1,0) [0|0] "" Vector__XXX
 SG_ VCLEFT_chargePortCurrent m1 : 8|6@1+ (0.05,0) [0|0] "" Vector__XXX
 SG_ VCLEFT_tohcPCBATemperature m0 : 8|8@1+ (1,-40) [0|0] "" Vector__XXX
 SG_ VCLEFT_turnTailStopLightCurrent m2 : 7|4@1+ (0.1,0) [0|0] "" Vector__XXX
 SG_ VCLEFT_12vSocketFrontCurrentAvg m4 : 3|10@1+ (0.01,0) [0|0] "" Vector__XXX
 SG_ VCLEFT_rgbLedIPFLCurrent m3 : 3|10@1+ (0.0004887585532746823,0) [0|0] "" Vector__XXX
 SG_ VCLEFT_tailLightCurrent m2 : 3|4@1+ (0.1,0) [0|0] "" Vector__XXX
 SG_ VCLEFT_logging1HzIndex M : 0|3@1+ (1,0) [0|0] "" Vector__XXX

BO_ 939 APP_driverMonitorStatus: 5 Vector__XXX
 SG_ APP_ADDWSystemStatus : 28|2@1+ (1,0) [0|0] "" Vector__XXX
 SG_ APP_cabinLowLuxHyst : 27|1@1+ (1,0) [0|0] "" Vector__XXX
 SG_ APP_cabinCamDarkHyst : 26|1@1+ (1,0) [0|0] "" Vector__XXX
 SG_ APP_handsOnInputRequired : 25|1@1+ (1,0) [0|0] "" Vector__XXX
 SG_ APP_driverSeatUnoccupied : 24|1@1+ (1,0) [0|0] "" Vector__XXX
 SG_ APP_driverHandsNotReady : 23|1@1+ (1,0) [0|0] "" Vector__XXX
 SG_ APP_driverLowEyeVisibility : 22|1@1+ (1,0) [0|0] "" Vector__XXX
 SG_ APP_driverLeaningBack : 21|1@1+ (1,0) [0|0] "" Vector__XXX
 SG_ APP_cabinCamInconsistent : 20|1@1+ (1,0) [0|0] "" Vector__XXX
 SG_ APP_cabinLowLux : 19|1@1+ (1,0) [0|0] "" Vector__XXX
 SG_ APP_driverSunglassesUseHyst : 18|1@1+ (1,0) [0|0] "" Vector__XXX
 SG_ APP_driverHeadCappedHyst : 17|1@1+ (1,0) [0|0] "" Vector__XXX
 SG_ APP_driverLowNominal : 16|1@1+ (1,0) [0|0] "" Vector__XXX
 SG_ APP_driverStateUnknownHyst : 15|1@1+ (1,0) [0|0] "" Vector__XXX
 SG_ APP_driverNotLively : 14|1@1+ (1,0) [0|0] "" Vector__XXX
 SG_ APP_driverStateUnknown : 13|1@1+ (1,0) [0|0] "" Vector__XXX
 SG_ APP_cabinCamDark : 12|1@1+ (1,0) [0|0] "" Vector__XXX
 SG_ APP_cabinCamBlinded : 11|1@1+ (1,0) [0|0] "" Vector__XXX
 SG_ APP_handsOnDetectedSource : 8|3@1+ (1,0) [0|0] "" Vector__XXX
 SG_ APP_handsOnDetected : 5|1@1+ (1,0) [0|0] "" Vector__XXX
 SG_ APP_attnBasedDriverMonitorOn : 4|1@1+ (1,0) [0|0] "" Vector__XXX
 SG_ APP_attnMonitorVersion : 1|3@1+ (1,0) [0|0] "" Vector__XXX
 SG_ APP_cabinCamTelemetryOn : 0|1@1+ (1,0) [0|0] "" Vector__XXX

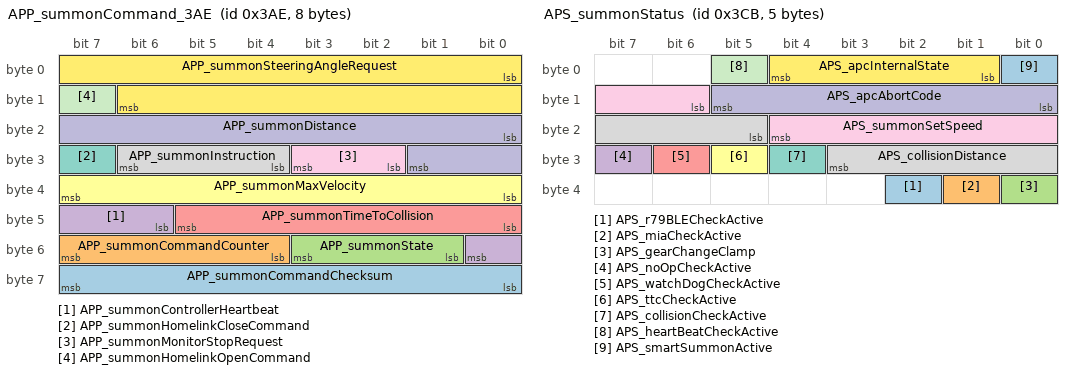
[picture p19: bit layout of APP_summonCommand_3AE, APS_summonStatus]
BO_ 942 APP_summonCommand_3AE: 8 Vector__XXX
 SG_ APP_summonCommandChecksum : 56|8@1+ (1,0) [0|0] "" Vector__XXX
 SG_ APP_summonCommandCounter : 52|4@1+ (1,0) [0|0] "" Vector__XXX
 SG_ APP_summonState : 49|3@1+ (1,0) [0|0] "" Vector__XXX
 SG_ APP_summonControllerHeartbeat : 46|3@1+ (1,0) [0|0] "" Vector__XXX
 SG_ APP_summonTimeToCollision : 40|6@1+ (0.1,0) [0|0] "" Vector__XXX
 SG_ APP_summonMaxVelocity : 32|8@1+ (0.05,0) [0|0] "" Vector__XXX
 SG_ APP_summonHomelinkCloseCommand : 31|1@1+ (1,0) [0|0] "" Vector__XXX
 SG_ APP_summonInstruction : 28|3@1+ (1,0) [0|0] "" Vector__XXX
 SG_ APP_summonMonitorStopRequest : 26|2@1+ (1,0) [0|0] "" Vector__XXX
 SG_ APP_summonDistance : 16|10@1+ (0.02,0) [0|0] "" Vector__XXX
 SG_ APP_summonHomelinkOpenCommand : 15|1@1+ (1,0) [0|0] "" Vector__XXX
 SG_ APP_summonSteeringAngleRequest : 0|15@1+ (0.1,-1638.35) [0|0] "" Vector__XXX

BO_ 943 OCS1P_debugSeatbackSelfCNTComp: 8 Vector__XXX
 SG_ OCS1P_deltaCapSeatbackSelf : 48|16@1- (0.0025,0) [0|0] "" Vector__XXX
 SG_ OCS1P_deltaFreqSeatbackSelf : 32|16@1- (1,0) [0|0] "" Vector__XXX
 SG_ OCS1P_seatbackSelfCNTCap : 16|16@1+ (0.005,0) [0|0] "" Vector__XXX
 SG_ OCS1P_seatbackSelfCNTFreqComp : 0|16@1+ (1,0) [0|0] "" Vector__XXX

BO_ 955 UI_power: 3 Vector__XXX
 SG_ UI_dSocAlertThreshold : 17|5@1+ (0.1,-3) [0|0] "" Vector__XXX
 SG_ UI_dSocAlertEnable : 16|1@1+ (1,0) [0|0] "" Vector__XXX
 SG_ UI_powerIdeal : 8|8@1+ (1,0) [0|0] "" Vector__XXX
 SG_ UI_powerExpected : 0|8@1+ (1,0) [0|0] "" Vector__XXX

BO_ 956 UI_tpmsRCPsetting_3BC: 4 Vector__XXX
 SG_ UI_setRCPRear : 24|8@1+ (0.025,0) [0|0] "" Vector__XXX
 SG_ UI_setRCPFront : 16|8@1+ (0.025,0) [0|0] "" Vector__XXX

BO_ 963 VCRIGHT_switchStatus: 8 Vector__XXX
 SG_ VCRIGHT_3RowRightBuckleSwitch m0 : 62|2@1+ (1,0) [0|0] "" Vector__XXX
 SG_ VCRIGHT_3RowLeftBuckleSwitch m0 : 60|2@1+ (1,0) [0|0] "" Vector__XXX
 SG_ VCRIGHT_hvacHeatingAllowedRight m1 : 59|1@1+ (1,0) [0|0] "" Vector__XXX
 SG_ VCRIGHT_3RowRightOccupancySwitch m0 : 58|2@1+ (1,0) [0|0] "" Vector__XXX
 SG_ VCRIGHT_3RowLeftOccupancySwitch m0 : 56|2@1+ (1,0) [0|0] "" Vector__XXX
 SG_ VCRIGHT_frontSeatResistiveOccupancy m1 : 54|2@1+ (1,0) [0|0] "" Vector__XXX
 SG_ VCRIGHT_rearRightOccupancySwitch m0 : 54|2@1+ (1,0) [0|0] "" Vector__XXX
 SG_ VCRIGHT_liftgateShutfaceSwitchPressed m0 : 53|1@1+ (1,0) [0|0] "" Vector__XXX
 SG_ VCRIGHT_btnWindowSwPackAutoDwnRR m0 : 52|1@1+ (1,0) [0|0] "" Vector__XXX
 SG_ VCRIGHT_btnWindowSwPackDownRR m0 : 51|1@1+ (1,0) [0|0] "" Vector__XXX
 SG_ VCRIGHT_btnWindowSwPackAutoUpRR m0 : 50|1@1+ (1,0) [0|0] "" Vector__XXX
 SG_ VCRIGHT_btnWindowSwPackUpRR m0 : 49|1@1+ (1,0) [0|0] "" Vector__XXX
 SG_ VCRIGHT_trunkExtReleasePressed m0 : 48|1@1+ (1,0) [0|0] "" Vector__XXX
 SG_ VCRIGHT_gloveboxLightCurrent m1 : 47|5@1+ (2,0) [0|0] "" Vector__XXX
 SG_ VCRIGHT_rearRightBuckleSwitch m0 : 46|2@1+ (1,0) [0|0] "" Vector__XXX
 SG_ VCRIGHT_rearCenterBuckleSwitch m0 : 44|2@1+ (1,0) [0|0] "" Vector__XXX
 SG_ VCRIGHT_frontOccupancySwitch m0 : 42|2@1+ (1,0) [0|0] "" Vector__XXX
 SG_ VCRIGHT_frontBuckleSwitch m0 : 40|2@1+ (1,0) [0|0] "" Vector__XXX
 SG_ VCRIGHT_rearHandlePWM m1 : 40|7@1+ (1,0) [0|0] "" Vector__XXX
 SG_ VCRIGHT_btnWindowSwPackAutoDwnLR m0 : 39|1@1+ (1,0) [0|0] "" Vector__XXX
 SG_ VCRIGHT_hvacHeatingAllowedLeft m1 : 39|1@1+ (1,0) [0|0] "" Vector__XXX
 SG_ VCRIGHT_btnWindowSwPackDownLR m0 : 38|1@1+ (1,0) [0|0] "" Vector__XXX
 SG_ VCRIGHT_btnWindowSwPackAutoUpLR m0 : 37|1@1+ (1,0) [0|0] "" Vector__XXX
 SG_ VCRIGHT_btnWindowSwPackUpLR m0 : 36|1@1+ (1,0) [0|0] "" Vector__XXX
 SG_ VCRIGHT_btnWindowSwPackAutoDwnLF m0 : 35|1@1+ (1,0) [0|0] "" Vector__XXX
 SG_ VCRIGHT_btnWindowSwPackDownLF m0 : 34|1@1+ (1,0) [0|0] "" Vector__XXX
 SG_ VCRIGHT_btnWindowSwPackAutoUpLF m0 : 33|1@1+ (1,0) [0|0] "" Vector__XXX
 SG_ VCRIGHT_btnWindowSwPackUpLF m0 : 32|1@1+ (1,0) [0|0] "" Vector__XXX
 SG_ VCRIGHT_frontHandlePWM m1 : 32|7@1+ (1,0) [0|0] "" Vector__XXX
 SG_ VCRIGHT_btnWindowAutoDownRR m0 : 31|1@1+ (1,0) [0|0] "" Vector__XXX
 SG_ VCRIGHT_btnWindowDownRR m0 : 30|1@1+ (1,0) [0|0] "" Vector__XXX
 SG_ VCRIGHT_btnWindowAutoUpRR m0 : 29|1@1+ (1,0) [0|0] "" Vector__XXX
 SG_ VCRIGHT_btnWindowUpRR m0 : 28|1@1+ (1,0) [0|0] "" Vector__XXX
 SG_ VCRIGHT_2RowSeatBackrestFoldSwitch m1 : 27|1@1+ (1,0) [0|0] "" Vector__XXX
 SG_ VCRIGHT_btnWindowAutoDownRF m0 : 27|1@1+ (1,0) [0|0] "" Vector__XXX
 SG_ VCRIGHT_2RowSeatReclineSwitch m1 : 26|1@1+ (1,0) [0|0] "" Vector__XXX
 SG_ VCRIGHT_btnWindowDownRF m0 : 26|1@1+ (1,0) [0|0] "" Vector__XXX
 SG_ VCRIGHT_btnWindowAutoUpRF m0 : 25|1@1+ (1,0) [0|0] "" Vector__XXX
 SG_ VCRIGHT_btnWindowUpRF m0 : 24|1@1+ (1,0) [0|0] "" Vector__XXX
 SG_ VCRIGHT_frontSeatLumbarOut m1 : 24|2@1+ (1,0) [0|0] "" Vector__XXX
 SG_ VCRIGHT_frontSeatLumbarIn m1 : 22|2@1+ (1,0) [0|0] "" Vector__XXX
 SG_ VCRIGHT_frontSeatLumbarUp m1 : 20|2@1+ (1,0) [0|0] "" Vector__XXX
 SG_ VCRIGHT_frontSeatLumbarDown m1 : 18|2@1+ (1,0) [0|0] "" Vector__XXX
 SG_ VCRIGHT_frontSeatBackrestForward m1 : 16|2@1+ (1,0) [0|0] "" Vector__XXX
 SG_ VCRIGHT_frontSeatBackrestBack m1 : 14|2@1+ (1,0) [0|0] "" Vector__XXX
 SG_ VCRIGHT_frontSeatLiftUp m1 : 12|2@1+ (1,0) [0|0] "" Vector__XXX
 SG_ VCRIGHT_frontSeatLiftDown m1 : 10|2@1+ (1,0) [0|0] "" Vector__XXX
 SG_ VCRIGHT_frontSeatTiltUp m1 : 8|2@1+ (1,0) [0|0] "" Vector__XXX
 SG_ VCRIGHT_frontSeatTiltDown m1 : 6|2@1+ (1,0) [0|0] "" Vector__XXX
 SG_ VCRIGHT_frontSeatTrackForward m1 : 4|2@1+ (1,0) [0|0] "" Vector__XXX
 SG_ VCRIGHT_frontSeatTrackBack m1 : 2|2@1+ (1,0) [0|0] "" Vector__XXX
 SG_ VCRIGHT_trunkExtReleasePressedPersist m1 : 1|1@1+ (1,0) [0|0] "" Vector__XXX
 SG_ VCRIGHT_switchStatusIndex M : 0|1@1+ (1,0) [0|0] "" Vector__XXX

BO_ 971 APS_summonStatus: 5 Vector__XXX
 SG_ APS_r79BLECheckActive : 34|1@1+ (1,0) [0|0] "" Vector__XXX
 SG_ APS_miaCheckActive : 33|1@1+ (1,0) [0|0] "" Vector__XXX
 SG_ APS_gearChangeClamp : 32|1@1+ (1,0) [0|0] "" Vector__XXX
 SG_ APS_noOpCheckActive : 31|1@1+ (1,0) [0|0] "" Vector__XXX
 SG_ APS_watchDogCheckActive : 30|1@1+ (1,0) [0|0] "" Vector__XXX
 SG_ APS_ttcCheckActive : 29|1@1+ (1,0) [0|0] "" Vector__XXX
 SG_ APS_collisionCheckActive : 28|1@1+ (1,0) [0|0] "" Vector__XXX
 SG_ APS_collisionDistance : 21|7@1+ (0.05,0) [0|0] "" Vector__XXX
 SG_ APS_summonSetSpeed : 14|7@1+ (0.1,0) [0|0] "" Vector__XXX
 SG_ APS_apcAbortCode : 8|6@1+ (1,0) [0|0] "" Vector__XXX
 SG_ APS_heartBeatCheckActive : 5|1@1+ (1,0) [0|0] "" Vector__XXX
 SG_ APS_apcInternalState : 1|4@1+ (1,0) [0|0] "" Vector__XXX
 SG_ APS_smartSummonActive : 0|1@1+ (1,0) [0|0] "" Vector__XXX

CM_ BO_ 49 "ESP32-DualCAN Model3_CH. Seen on this car: 8-byte frames; fit good (bits covered 92%, mux 100%, ranges 100%).";
VAL_ 49 EPAS3P_state 0 "STANDBY" 1 "DRIVE" 2 "SUPPORT" 3 "CHARGE" 4 "FEIM" 5 "CLEAR_FAULT" 6 "FAULT" 7 "WELD" 8 "TEST" 9 "SNA" 10 "DIAG" ;
CM_ BO_ 81 "ESP32-DualCAN Model3_CH. Seen on this car: 8-byte frames; fit good (bits covered 92%, mux 100%, ranges 100%).";
VAL_ 81 EPAS3S_state 0 "STANDBY" 1 "DRIVE" 2 "SUPPORT" 3 "CHARGE" 4 "FEIM" 5 "CLEAR_FAULT" 6 "FAULT" 7 "WELD" 8 "TEST" 9 "SNA" 10 "DIAG" ;
CM_ BO_ 82 "ESP32-DualCAN Model3_CH. Seen on this car: 8-byte frames; fit ok (bits covered 100%, mux 100%, ranges 100%).";
VAL_ 82 EPAS3P_eacStatus 0 "INHIBITED" 1 "AVAILABLE" 2 "ACTIVE" 3 "FAULT" 4 "LKA_ELK_AVAILABLE" 5 "LKA_ACTIVE" 6 "ELK_AVAILABLE" 7 "ELK_ACTIVE" ;
VAL_ 82 EPAS3P_handsOnLevel 0 "0" 1 "1" 2 "2" 3 "3" ;
VAL_ 82 EPAS3P_torsionBarTorque 4094 "UNDEFINABLE_DATA" 4095 "SNA" ;
VAL_ 82 EPAS3P_eacErrorCode 0 "EAC_ERROR_IDLE" 1 "EAC_ERROR_MIN_SPEED" 2 "EAC_ERROR_MAX_SPEED" 3 "EAC_ERROR_HANDS_ON" 4 "EAC_ERROR_TMP_FAULT" 5 "EAR_ERROR_MAX_STEER_DELTA" 6 "EAC_ERROR_HIGH_ANGLE_REQ" 7 "EAC_ERROR_HIGH_ANGLE_RATE_REQ" 8 "EAC_ERROR_HIGH_ANGLE_SAFETY" 9 "EAC_ERROR_HIGH_ANGLE_RATE_SAFETY" 10 "EAC_ERROR_HIGH_MMOT_SAFETY" 11 "EAC_ERROR_HIGH_TORSION_SAFETY" 12 "EAC_ERROR_LOW_ASSIST" 13 "EAC_ERROR_PINION_VEL_DIFF" 14 "EAC_EXTERNAL_MONITOR_INHIBIT" 15 "SNA" ;
VAL_ 82 EPAS3P_steeringRackForce 1022 "NOT_IN_SPEC" 1023 "SNA" ;
VAL_ 82 EPAS3P_steeringFault 0 "NO_FAULT" 1 "FAULT" ;
VAL_ 82 EPAS3P_steeringReduced 0 "NORMAL_ASSIST" 1 "REDUCED_ASSIST" ;
VAL_ 82 EPAS3P_internalSASQF 0 "UNDEFINABLE_ACCURACY" 1 "IN_SPEC" ;
VAL_ 82 EPAS3P_currentTuneMode 0 "DM_COMFORT" 1 "DM_STANDARD" 2 "DM_SPORT" 3 "RWD_COMFORT" 4 "RWD_STANDARD" 5 "RWD_SPORT" ;
CM_ BO_ 290 "ESP32-DualCAN Model3_VEH. Seen on this car: 8-byte frames; fit good (bits covered 100%, mux 100%, ranges 100%).";
VAL_ 290 VCLEFT_rearDoorState 0 "UNKNOWN" 1 "CLOSED" 2 "WAIT_FOR_SHORT_DROP" 3 "RELEASING_LATCH" 4 "OPEN" 5 "AJAR" 6 "INIT" ;
VAL_ 290 VCLEFT_frontDoorState 0 "UNKNOWN" 1 "CLOSED" 2 "WAIT_FOR_SHORT_DROP" 3 "RELEASING_LATCH" 4 "OPEN" 5 "AJAR" 6 "INIT" ;
CM_ BO_ 296 "ESP32-DualCAN Model3_VEH. Seen on this car: 6-byte frames; fit ok (bits covered 100%, mux 100%, ranges 100%).";
VAL_ 296 DI_proximity 0 "SNA" 1 "DISCONNECTED" 2 "UNLATCHED" 3 "LATCHED" ;
VAL_ 296 DI_vehicleSpeedLimitReason 0 "NONE" 1 "DRIVE_UNIT_LIMIT" 2 "FACTORY_LOW_BRAKE_FLUID" 3 "FACTORY_MODE" 4 "SERVICE_MODE" 5 "MAX_CAR_CONFIG" 6 "SPINDOWN_LEARNING" 7 "TRAILER_MODE" 8 "TAS" 9 "LOAD_SHED" 10 "FRUNK_OPEN" 11 "USER" ;
VAL_ 296 DI_vehicleSpeedLimit 511 "SNA" ;
VAL_ 296 DI_vehicleSpeedLimitType 0 "NONE" 1 "USER" 2 "POWERTRAIN" ;
CM_ BO_ 305 "ESP32-DualCAN Model3_CH. Seen on this car: 8-byte frames; fit good (bits covered 100%, mux 100%, ranges 100%, checksum 100%).";
CM_ BO_ 313 "ESP32-DualCAN Model3_VEH. Seen on this car: 1-byte frames; fit poor (bits covered 0%, mux 100%, ranges 100%).";
CM_ BO_ 321 "ESP32-DualCAN Model3_CH. Seen on this car: 8-byte frames; fit good (bits covered 100%, mux 100%, ranges 100%, checksum 100%).";
CM_ BO_ 326 "ESP32-DualCAN Model3_CH. Seen on this car: 8-byte frames; fit good (bits covered 88%, mux 100%, ranges 100%, checksum 100%).";
CM_ BO_ 329 "ESP32-DualCAN Model3_CH. Seen on this car: 8-byte frames; fit good (bits covered 100%, mux 100%, ranges 100%, checksum 100%).";
VAL_ 329 IBST_brakeTorqueTarget 8191 "SNA" ;
CM_ BO_ 337 "Unknown 1 Hz status: only bits 48-49 change.";
CM_ BO_ 454 "ESP32-DualCAN Model3_CH. Seen on this car: 6-byte frames; fit ok (bits covered 100%, mux 100%, ranges 100%).";
CM_ BO_ 473 "ESP32-DualCAN Model3_VEH. Seen on this car: 3-byte frames; fit poor (bits covered 0%, mux 100%, ranges 100%).; 5 signals past the 3 bytes this car sends were left out";
CM_ BO_ 474 "ESP32-DualCAN Model3_VEH. Seen on this car: 8-byte frames; fit good (bits covered 100%, mux 100%, ranges 100%).";
CM_ BO_ 485 "ESP32-DualCAN Model3_VEH. Seen on this car: 8-byte frames; fit good (bits covered 100%, mux 100%, ranges 100%, checksum 100%).";
VAL_ 485 PM_hvilSystemStatus 0 "DISABLED" 1 "OPEN" 2 "CLOSED" 3 "SNA" ;
VAL_ 485 PM_autoparkState 0 "UNAVAILABLE" 1 "STANDBY" 2 "STARTED" 3 "ACTIVE" 4 "COMPLETE" 5 "PAUSED" 6 "ABORTED" 7 "RESUMED" 8 "UNPARK_COMPLETE" 9 "SELFPARK_STARTED" 15 "SNA" ;
VAL_ 485 PM_cruiseState 0 "UNAVAILABLE" 1 "STANDBY" 2 "ENABLED" 3 "STANDSTILL" 4 "OVERRIDE" 5 "FAULT" 6 "PRE_FAULT" 7 "PRE_CANCEL" ;
CM_ BO_ 504 "ESP32-DualCAN Model3_VEH. Seen on this car: 4-byte frames; fit poor (bits covered 0%, mux 100%, ranges 100%).";
VAL_ 504 VCLEFT_DBG_LM_SelfTest_Status 0 "IDLE" 1 "RX" ;
VAL_ 504 VCLEFT_DBG_USS_SelfTest_Status 0 "IDLE" 1 "RX" ;
VAL_ 504 VCLEFT_DBG_Eeprom_ST_Status 0 "IDLE" 1 "RX" ;
VAL_ 504 VCLEFT_DBG_Siren_ST_Status 0 "IDLE" 1 "RX" ;
VAL_ 504 VCLEFT_DBG_LM_Alarm_Status 0 "IDLE" 1 "RX" ;
VAL_ 504 VCLEFT_DBG_USS_Alarm_Status 0 "IDLE" 1 "RX" ;
VAL_ 504 VCLEFT_DBG_Veh_Settings_Status 0 "IDLE" 1 "RX" ;
VAL_ 504 VCLEFT_DBG_SelfTest_Status 0 "IDLE" 1 "RX" ;
VAL_ 504 VCLEFT_DBG_Suspensions_Status 0 "IDLE" 1 "RX" ;
VAL_ 504 VCLEFT_DBG_Window_Status 0 "IDLE" 1 "RX" ;
VAL_ 504 VCLEFT_DBG_Heater_Status 0 "IDLE" 1 "RX" ;
VAL_ 504 VCLEFT_DBG_Air_Cond_Status 0 "IDLE" 1 "RX" ;
VAL_ 504 VCLEFT_DBG_System_Status 0 "IDLE" 1 "RX" ;
CM_ BO_ 505 "ESP32-DualCAN Model3_VEH. Seen on this car: 8-byte frames; fit good (bits covered 100%, mux 100%, ranges 100%).";
VAL_ 505 VCSEC_chargeportRequestReason 0 "NONE" 1 "RKE" 2 "UHF" ;
VAL_ 505 VCSEC_snapshotRequested 0 "NONE" 1 "HANDLE_PULL_WITHOUT_AUTH" 2 "AUTHED_WITHOUT_HANDLE_PULL" 3 "AUTO_PRESENT_DOOR_CLOSE_TIMEOUT" 4 "AUTO_PRESENT_DOOR_CLOSE_WITHOUT_PEDESTRIAN_DETECTED" 5 "INTRUSION_DETECTED" 6 "TRIGGER_6" 7 "TRIGGER_7" 8 "TRIGGER_8" 9 "TRIGGER_9" 10 "TRIGGER_10" 11 "TRIGGER_11" 12 "TRIGGER_12" 13 "TRIGGER_13" 14 "TRIGGER_14" 15 "TRIGGER_15" ;
VAL_ 505 VCSEC_closeAllStatus 0 "NOT_AVAILABLE" 1 "AVAILABLE" 2 "CANCELABLE" ;
VAL_ 505 VCSEC_rearTrunkRequestReason 0 "REASON_NONE" 1 "REASON_RKE" 2 "REASON_CLOSE_ALL" 3 "REASON_AUTO_PRESENT" 4 "KEYFOB_UNLOCK_OPEN" 5 "UI_STOP_ALL" ;
VAL_ 505 VCSEC_rearRightRequestReason 0 "REASON_NONE" 1 "REASON_RKE" 2 "REASON_CLOSE_ALL" 3 "REASON_AUTO_PRESENT" 4 "KEYFOB_UNLOCK_OPEN" 5 "UI_STOP_ALL" ;
VAL_ 505 VCSEC_rearLeftRequestReason 0 "REASON_NONE" 1 "REASON_RKE" 2 "REASON_CLOSE_ALL" 3 "REASON_AUTO_PRESENT" 4 "KEYFOB_UNLOCK_OPEN" 5 "UI_STOP_ALL" ;
VAL_ 505 VCSEC_frontRightRequestReason 0 "REASON_NONE" 1 "REASON_RKE" 2 "REASON_CLOSE_ALL" 3 "REASON_AUTO_PRESENT" 4 "KEYFOB_UNLOCK_OPEN" 5 "UI_STOP_ALL" ;
VAL_ 505 VCSEC_frontLeftRequestReason 0 "REASON_NONE" 1 "REASON_RKE" 2 "REASON_CLOSE_ALL" 3 "REASON_AUTO_PRESENT" 4 "KEYFOB_UNLOCK_OPEN" 5 "UI_STOP_ALL" ;
VAL_ 505 VCSEC_rearTrunkClosureRequest 0 "NONE" 1 "MOVE" 2 "STOP" 3 "OPEN" 4 "QUICK_OPEN" 5 "OPEN_REDUCED" 6 "CLOSE" ;
VAL_ 505 VCSEC_rearRightClosureRequest 0 "NONE" 1 "MOVE" 2 "STOP" 3 "OPEN" 4 "QUICK_OPEN" 5 "OPEN_REDUCED" 6 "CLOSE" ;
VAL_ 505 VCSEC_rearLeftClosureRequest 0 "NONE" 1 "MOVE" 2 "STOP" 3 "OPEN" 4 "QUICK_OPEN" 5 "OPEN_REDUCED" 6 "CLOSE" ;
VAL_ 505 VCSEC_frontRightClosureRequest 0 "NONE" 1 "MOVE" 2 "STOP" 3 "OPEN" 4 "QUICK_OPEN" 5 "OPEN_REDUCED" 6 "CLOSE" ;
VAL_ 505 VCSEC_frontLeftClosureRequest 0 "NONE" 1 "MOVE" 2 "STOP" 3 "OPEN" 4 "QUICK_OPEN" 5 "OPEN_REDUCED" 6 "CLOSE" ;
VAL_ 505 VCSEC_chargePortRequest 0 "NONE" 1 "OPEN" 2 "CLOSE" 3 "SNA" ;
CM_ BO_ 506 "ESP32-DualCAN Model3_VEH. Seen on this car: 3-byte frames; fit poor (bits covered 0%, mux 100%, ranges 100%).";
CM_ BO_ 507 "ESP32-DualCAN Model3_VEH. Seen on this car: 8-byte frames; fit weak (bits covered 0%, mux 100%, ranges 100%).";
VAL_ 507 VCLEFT_TLCState_Reverse 0 "OFF_WITHOUT_LOAD" 1 "OFF_WITH_LOAD" 2 "ON_WITHOUT_LOAD" 3 "ON_WITH_LOAD" 4 "FAULT" 5 "SNA" ;
VAL_ 507 VCLEFT_TLCState_Fog 0 "OFF_WITHOUT_LOAD" 1 "OFF_WITH_LOAD" 2 "ON_WITHOUT_LOAD" 3 "ON_WITH_LOAD" 4 "FAULT" 5 "SNA" ;
VAL_ 507 VCLEFT_TLCState_Stop 0 "OFF_WITHOUT_LOAD" 1 "OFF_WITH_LOAD" 2 "ON_WITHOUT_LOAD" 3 "ON_WITH_LOAD" 4 "FAULT" 5 "SNA" ;
VAL_ 507 VCLEFT_TLCState_Tail 0 "OFF_WITHOUT_LOAD" 1 "OFF_WITH_LOAD" 2 "ON_WITHOUT_LOAD" 3 "ON_WITH_LOAD" 4 "FAULT" 5 "SNA" ;
VAL_ 507 VCLEFT_TLCState_RightTurn 0 "OFF_WITHOUT_LOAD" 1 "OFF_WITH_LOAD" 2 "ON_WITHOUT_LOAD" 3 "ON_WITH_LOAD" 4 "FAULT" 5 "SNA" ;
VAL_ 507 VCLEFT_TLCState_LeftTurn 0 "OFF_WITHOUT_LOAD" 1 "OFF_WITH_LOAD" 2 "ON_WITHOUT_LOAD" 3 "ON_WITH_LOAD" 4 "FAULT" 5 "SNA" ;
VAL_ 507 VCLEFT_TLCRightTurnVoltage 255 "SNA" ;
VAL_ 507 VCLEFT_TLCLeftTurnVoltage 255 "SNA" ;
VAL_ 507 VCLEFT_TLCTemperature 4294967168 "SNA" ;
VAL_ 507 VCLEFT_TLCStatusIndex 0 "0" 1 "1" 2 "INVALID" ;
CM_ BO_ 521 "ESP32-DualCAN Model3_CH. Seen on this car: 8-byte frames; fit ok (bits covered 100%, mux 0%, ranges 100%, checksum 100%).";
VAL_ 521 DAS_pedalControl_accelPedalPos 255 "SNA" ;
VAL_ 521 DAS_gearRequest 0 "IDLE_SNA" 1 "PARK" 2 "REVERSE" 3 "NEUTRAL" 4 "DRIVE" ;
CM_ BO_ 549 "ESP32-DualCAN Model3_VEH. Seen on this car: 4-byte frames; fit ok (bits covered 100%, mux 100%, ranges 100%).";
VAL_ 549 VCRIGHT_icrLVState 0 "OFF" 1 "ON" 2 "GOING_DOWN" 3 "FAULT" ;
VAL_ 549 VCRIGHT_parkLVState 0 "OFF" 1 "ON" 2 "GOING_DOWN" 3 "FAULT" ;
VAL_ 549 VCRIGHT_vehiclePowerStateDBG 0 "INIT" 1 "LOW_POWER_AWAKE" 2 "CONDITIONING" 3 "ACCESSORY" 4 "ACCESSORY_PLUS" 5 "DRIVE" 6 "OTA" 7 "WAIT_FOR_HIGH_POWER" 8 "TURN_ON_LV" 9 "SYSTEM_CHECKS" 10 "LV_ON" 11 "JUMP_START" 12 "LV_SHUTDOWN" 13 "GO_QUIET" 14 "SLEEP_SHUTDOWN" 15 "LOW_POWER_STANDBY" 16 "RESET" ;
VAL_ 549 VCRIGHT_eFuseLockoutStatus 0 "IDLE" 1 "PENDING" 2 "ACTIVE" ;
VAL_ 549 VCRIGHT_lumbarLVState 0 "OFF" 1 "ON" 2 "GOING_DOWN" 3 "FAULT" ;
VAL_ 549 VCRIGHT_rcmLVState 0 "OFF" 1 "ON" 2 "GOING_DOWN" 3 "FAULT" ;
VAL_ 549 VCRIGHT_hvcLVState 0 "OFF" 1 "ON" 2 "GOING_DOWN" 3 "FAULT" ;
VAL_ 549 VCRIGHT_tunerLVState 0 "OFF" 1 "ON" 2 "GOING_DOWN" 3 "FAULT" ;
VAL_ 549 VCRIGHT_premAudioLVState 0 "OFF" 1 "ON" 2 "GOING_DOWN" 3 "FAULT" ;
VAL_ 549 VCRIGHT_ocsLVState 0 "OFF" 1 "ON" 2 "GOING_DOWN" 3 "FAULT" ;
VAL_ 549 VCRIGHT_ptcLVState 0 "OFF" 1 "ON" 2 "GOING_DOWN" 3 "FAULT" ;
CM_ BO_ 551 "ESP32-DualCAN Model3_CH. Seen on this car: 8-byte frames; fit good (bits covered 100%, mux 100%, ranges 100%).";
CM_ BO_ 554 "ESP32-DualCAN Model3_VEH. Seen on this car: 4-byte frames; fit ok (bits covered 100%, mux 100%, ranges 100%).";
VAL_ 554 HVP_dcLinkVoltageFiltered 4294966746 "SNA" ;
VAL_ 554 HVP_pcsControlRequest 0 "SHUTDOWN" 1 "SUPPORT" 2 "PRECHARGE" 3 "DISCHARGE" ;
CM_ BO_ 555 "ESP32-DualCAN Model3_VEH. Seen on this car: 8-byte frames; fit good (bits covered 100%, mux 100%, ranges 100%).";
CM_ BO_ 561 "ESP32-DualCAN Model3_CH. Seen on this car: 8-byte frames; fit good (bits covered 100%, mux 100%, ranges 100%).";
CM_ BO_ 562 "ESP32-DualCAN Model3_VEH. Seen on this car: 8-byte frames; fit good (bits covered 100%, mux 100%, ranges 100%).";
CM_ BO_ 564 "ESP32-DualCAN Model3_VEH. Seen on this car: 8-byte frames; fit ok (bits covered 100%, mux 100%, ranges 100%, checksum 0%).";
VAL_ 564 DCDC_type 0 "US_TESLA" 1 "EURO_IEC" 2 "GB" 3 "IEC_CCS" ;
CM_ BO_ 565 "ESP32-DualCAN Model3_CH. Seen on this car: 4-byte frames; fit ok (bits covered 100%, mux 100%, ranges 100%).";
CM_ BO_ 576 "ESP32-DualCAN Model3_CH. Seen on this car: 2-byte frames; fit ok (bits covered 100%, mux 100%, ranges 100%, checksum 100%).";
CM_ BO_ 578 "ESP32-DualCAN Model3_VEH. Seen on this car: 4-byte frames; fit ok (bits covered 100%, mux 100%, ranges 100%).";
VAL_ 578 VCLEFT_vehiclePowerStateDBG 0 "INIT" 1 "LOW_POWER_AWAKE" 2 "CONDITIONING" 3 "ACCESSORY" 4 "ACCESSORY_PLUS" 5 "DRIVE" 6 "OTA" 7 "WAIT_FOR_HIGH_POWER" 8 "TURN_ON_LV" 9 "SYSTEM_CHECKS" 10 "LV_ON" 11 "JUMP_START" 12 "LV_SHUTDOWN" 13 "GO_QUIET" 14 "SLEEP_SHUTDOWN" 15 "LOW_POWER_STANDBY" 16 "RESET" ;
VAL_ 578 VCLEFT_lumbarLVState 0 "OFF" 1 "ON" 2 "GOING_DOWN" 3 "FAULT" ;
VAL_ 578 VCLEFT_rcmLVState 0 "OFF" 1 "ON" 2 "GOING_DOWN" 3 "FAULT" ;
CM_ BO_ 608 "Unknown 10 Hz: bit 0 flag, counter at 52; byte 7 = byte sum + 0x62.";
CM_ BO_ 633 "ESP32-DualCAN Model3_VEH. Seen on this car: 8-byte frames; fit ok (bits covered 100%, mux 100%, ranges 100%, checksum 0%).";
VAL_ 633 DIR_gateDriveSupplyState 0 "DOWN" 1 "RISING" 2 "UP" 3 "FALLING" ;
VAL_ 633 DIR_gateDriveState 0 "INIT" 1 "SELFTEST" 2 "CONFIGURING" 3 "CONFIGURED" 4 "NOT_CONFIGURED" ;
VAL_ 633 DIR_powerStageSafeState 0 "NONE" 1 "ALL_OFF" 2 "3PS_HIGH" 3 "3PS_LOW" ;
VAL_ 633 DIR_vBatQF 0 "NOT_QUALIFIED" 1 "QUALIFIED" ;
VAL_ 633 DIR_hvilSupplyState 0 "NOT_AVAILABLE" 1 "INACTIVE" 2 "ACTIVE" ;
VAL_ 633 DIR_hvilStatus 0 "DISABLED" 1 "OPEN" 2 "CLOSED" 3 "SNA" ;
CM_ BO_ 643 "ESP32-DualCAN Model3_VEH. Seen on this car: 6-byte frames; fit poor (bits covered 0%, mux 100%, ranges 100%).";
CM_ BO_ 649 "ESP32-DualCAN Model3_VEH. Seen on this car: 8-byte frames; fit good (bits covered 100%, mux 100%, ranges 100%).";
VAL_ 649 VCLEFT_hvacBlowerITerm 127 "SNA" ;
VAL_ 649 VCLEFT_hvacBlowerCBCCtrlState 0 "ERROR" 1 "IDLE" 2 "OFFLINE" 3 "ONLINE" 4 "COUNT" ;
VAL_ 649 VCLEFT_hvacBlowerCBCEstState 0 "ERROR" 1 "IDLE" 2 "ROVERL" 3 "RS" 4 "RAMPUP" 5 "IDRATED" 6 "RATEDFLUX_OL" 7 "RATEDFLUX" 8 "RAMPDOWN" 9 "LOCKROTOR" 10 "INDUCTANCE_EST" 11 "ROTOR_RESISTANCE" 12 "MOTOR_IDENTIFIED" 13 "ONLINE" 14 "COUNT" ;
VAL_ 649 VCLEFT_hvacBlower_IO_CBC_Status 0 "IDLE" 1 "RX" ;
VAL_ 649 VCLEFT_hvacBlowerIPhase2 255 "SNA" ;
VAL_ 649 VCLEFT_hvacBlowerIPhase1 255 "SNA" ;
VAL_ 649 VCLEFT_hvacBlowerIPhase0 255 "SNA" ;
VAL_ 649 VCLEFT_hvacBlowerRs 255 "SNA" ;
VAL_ 649 VCLEFT_logging10HzIndex 0 "Mux0" 1 "Mux1" ;
CM_ BO_ 654 "Alive message: checksum + counter only; no data seen (route 494, 2026-11-19). Byte sum + 0x90; bytes 2-7 constant.";
CM_ BO_ 655 "Alive message: checksum + counter only; no data seen (route 494, 2026-11-19). Byte sum + 0x91; bytes 2-7 constant.";
CM_ BO_ 660 "ESP32-DualCAN Model3_VEH. Seen on this car: 8-byte frames; fit good (bits covered 100%, mux 100%, ranges 100%).";
VAL_ 660 UI_windowRequest 0 "IDLE" 1 "GOTO_PERCENT" 2 "GOTO_VENT" 3 "GOTO_CLOSED" 5 "GOTO_CLOSED_CARWASH" 6 "GOTO_PERCENT_RELATIVE" ;
VAL_ 660 UI_packTempLoggingRequest 0 "FALSE" 1 "TRUE" ;
VAL_ 660 UI_lightFlashRequest 0 "INACTIVE" 1 "HOMELINK" 2 "MOBILE_APP" 3 "SENTRY" ;
CM_ BO_ 661 "ESP32-DualCAN Model3_VEH. Seen on this car: 8-byte frames; fit good (bits covered 100%, mux 100%, ranges 100%).";
CM_ BO_ 667 "ESP32-DualCAN Model3_VEH. Seen on this car: 5-byte frames; fit weak (bits covered 69%, mux 100%, ranges 100%).";
CM_ BO_ 670 "ESP32-DualCAN Model3_VEH. Seen on this car: 8-byte frames; fit good (bits covered 100%, mux 100%, ranges 100%, checksum 100%).";
CM_ BO_ 673 "ESP32-DualCAN Model3_VEH. Seen on this car: 6-byte frames; fit ok (bits covered 100%, mux 100%, ranges 100%).";
CM_ BO_ 678 "ESP32-DualCAN Model3_VEH. Seen on this car: 8-byte frames; fit good (bits covered 100%, mux 100%, ranges 100%).";
CM_ BO_ 682 "ESP32-DualCAN Model3_VEH. Seen on this car: 3-byte frames; fit ok (bits covered 100%, mux 100%, ranges 100%, checksum 100%).";
CM_ BO_ 703 "ESP32-DualCAN Model3_VEH. Seen on this car: 8-byte frames; fit good (bits covered 100%, mux 100%, ranges 100%).";
CM_ BO_ 706 "ESP32-DualCAN Model3_VEH. Seen on this car: 8-byte frames; fit good (bits covered 100%, mux 100%, ranges 100%).";
VAL_ 706 VCLEFT_windowPositionStateLR 0 "UNKNOWN" 1 "CLOSED" 2 "CRACKED" 3 "VENT" 4 "PARTIAL_OPEN" 5 "FULL_OPEN" 6 "CLOSED_TRIM_CLEAR" ;
VAL_ 706 VCLEFT_windowPositionStateLF 0 "UNKNOWN" 1 "CLOSED" 2 "CRACKED" 3 "VENT" 4 "PARTIAL_OPEN" 5 "FULL_OPEN" 6 "CLOSED_TRIM_CLEAR" ;
VAL_ 706 VCLEFT_windowCtrlUnavailableLR 0 "NONE" 1 "UNEXPECTED" 2 "SWITCH_PRESSED" 3 "PINCH" 4 "THERMAL_LIMIT" 5 "UNCALIBRATED" 6 "VEHICLE_IN_DRIVE" 7 "WINDOW_MOVING" ;
VAL_ 706 VCLEFT_windowControlStateLR 0 "IDLE" 1 "CLOSING" 2 "GOING_TO_POSITION" ;
VAL_ 706 VCLEFT_windowCtrlUnavailableLF 0 "NONE" 1 "UNEXPECTED" 2 "SWITCH_PRESSED" 3 "PINCH" 4 "THERMAL_LIMIT" 5 "UNCALIBRATED" 6 "VEHICLE_IN_DRIVE" 7 "WINDOW_MOVING" ;
VAL_ 706 VCLEFT_windowControlStateLF 0 "IDLE" 1 "CLOSING" 2 "GOING_TO_POSITION" ;
VAL_ 706 VCLEFT_windowStateLR 0 "STOPPED" 1 "MOVING_UP" 2 "MOVING_DOWN" 3 "BACKOFF" 4 "SHORT_DROP" 5 "SHORT_DROP_REVERSE" 6 "MOVING_AUTO_UP" 7 "MOVING_AUTO_DOWN" 8 "BACKDRIVE" ;
VAL_ 706 VCLEFT_windowStopReqReasonLR 0 "NONE" 1 "SWITCH_CANCEL_AUTO_MOVEMENT" 2 "SWITCH_RELEASED" 3 "REAR_LOCKOUT" 4 "THERMAL" 5 "STALL" 6 "STATE_TIMEOUT" 7 "FULL_OPEN_SOFT_STOP" 8 "EXTERNAL_REQUEST" ;
VAL_ 706 VCLEFT_windowStopReasonLR 0 "NONE" 1 "DOOR_OPEN_TRIM_PROTECT" 2 "NEW_REQUEST" 3 "TARGET_REACHED" 4 "STOP_REQUEST" 5 "FULL_OPEN_SOFT_STOP" 6 "STATE_TIMEOUT" ;
VAL_ 706 VCLEFT_windowThermalModeLR 0 "SNA" 1 "NORMAL" 2 "ALERT" 3 "CRITICAL" ;
VAL_ 706 VCLEFT_windowStopReqReasonLF 0 "NONE" 1 "SWITCH_CANCEL_AUTO_MOVEMENT" 2 "SWITCH_RELEASED" 3 "REAR_LOCKOUT" 4 "THERMAL" 5 "STALL" 6 "STATE_TIMEOUT" 7 "FULL_OPEN_SOFT_STOP" 8 "EXTERNAL_REQUEST" ;
VAL_ 706 VCLEFT_windowStopReasonLF 0 "NONE" 1 "DOOR_OPEN_TRIM_PROTECT" 2 "NEW_REQUEST" 3 "TARGET_REACHED" 4 "STOP_REQUEST" 5 "FULL_OPEN_SOFT_STOP" 6 "STATE_TIMEOUT" ;
VAL_ 706 VCLEFT_windowThermalModeLF 0 "SNA" 1 "NORMAL" 2 "ALERT" 3 "CRITICAL" ;
VAL_ 706 VCLEFT_windowStateLF 0 "STOPPED" 1 "MOVING_UP" 2 "MOVING_DOWN" 3 "BACKOFF" 4 "SHORT_DROP" 5 "SHORT_DROP_REVERSE" 6 "MOVING_AUTO_UP" 7 "MOVING_AUTO_DOWN" 8 "BACKDRIVE" ;
VAL_ 706 VCLEFT_windowStatusIndex 0 "Mux0" 1 "Mux1" ;
CM_ BO_ 707 "ESP32-DualCAN Model3_VEH. Seen on this car: 8-byte frames; fit good (bits covered 100%, mux 100%, ranges 100%).";
VAL_ 707 VCRIGHT_windowPositionStateRR 0 "UNKNOWN" 1 "CLOSED" 2 "CRACKED" 3 "VENT" 4 "PARTIAL_OPEN" 5 "FULL_OPEN" 6 "CLOSED_TRIM_CLEAR" ;
VAL_ 707 VCRIGHT_windowPositionStateRF 0 "UNKNOWN" 1 "CLOSED" 2 "CRACKED" 3 "VENT" 4 "PARTIAL_OPEN" 5 "FULL_OPEN" 6 "CLOSED_TRIM_CLEAR" ;
VAL_ 707 VCRIGHT_windowCtrlUnavailableRR 0 "NONE" 1 "UNEXPECTED" 2 "SWITCH_PRESSED" 3 "PINCH" 4 "THERMAL_LIMIT" 5 "UNCALIBRATED" 6 "VEHICLE_IN_DRIVE" 7 "WINDOW_MOVING" ;
VAL_ 707 VCRIGHT_windowControlStateRR 0 "IDLE" 1 "CLOSING" 2 "GOING_TO_POSITION" ;
VAL_ 707 VCRIGHT_windowCtrlUnavailableRF 0 "NONE" 1 "UNEXPECTED" 2 "SWITCH_PRESSED" 3 "PINCH" 4 "THERMAL_LIMIT" 5 "UNCALIBRATED" 6 "VEHICLE_IN_DRIVE" 7 "WINDOW_MOVING" ;
VAL_ 707 VCRIGHT_windowControlStateRF 0 "IDLE" 1 "CLOSING" 2 "GOING_TO_POSITION" ;
VAL_ 707 VCRIGHT_windowStateRR 0 "STOPPED" 1 "MOVING_UP" 2 "MOVING_DOWN" 3 "BACKOFF" 4 "SHORT_DROP" 5 "SHORT_DROP_REVERSE" 6 "MOVING_AUTO_UP" 7 "MOVING_AUTO_DOWN" 8 "BACKDRIVE" ;
VAL_ 707 VCRIGHT_windowStopReqReasonRR 0 "NONE" 1 "SWITCH_CANCEL_AUTO_MOVEMENT" 2 "SWITCH_RELEASED" 3 "REAR_LOCKOUT" 4 "THERMAL" 5 "STALL" 6 "STATE_TIMEOUT" 7 "FULL_OPEN_SOFT_STOP" 8 "EXTERNAL_REQUEST" ;
VAL_ 707 VCRIGHT_windowStopReasonRR 0 "NONE" 1 "DOOR_OPEN_TRIM_PROTECT" 2 "NEW_REQUEST" 3 "TARGET_REACHED" 4 "STOP_REQUEST" 5 "FULL_OPEN_SOFT_STOP" 6 "STATE_TIMEOUT" ;
VAL_ 707 VCRIGHT_windowThermalModeRR 0 "SNA" 1 "NORMAL" 2 "ALERT" 3 "CRITICAL" ;
VAL_ 707 VCRIGHT_windowStopReqReasonRF 0 "NONE" 1 "SWITCH_CANCEL_AUTO_MOVEMENT" 2 "SWITCH_RELEASED" 3 "REAR_LOCKOUT" 4 "THERMAL" 5 "STALL" 6 "STATE_TIMEOUT" 7 "FULL_OPEN_SOFT_STOP" 8 "EXTERNAL_REQUEST" ;
VAL_ 707 VCRIGHT_windowStopReasonRF 0 "NONE" 1 "DOOR_OPEN_TRIM_PROTECT" 2 "NEW_REQUEST" 3 "TARGET_REACHED" 4 "STOP_REQUEST" 5 "FULL_OPEN_SOFT_STOP" 6 "STATE_TIMEOUT" ;
VAL_ 707 VCRIGHT_windowThermalModeRF 0 "SNA" 1 "NORMAL" 2 "ALERT" 3 "CRITICAL" ;
VAL_ 707 VCRIGHT_windowStateRF 0 "STOPPED" 1 "MOVING_UP" 2 "MOVING_DOWN" 3 "BACKOFF" 4 "SHORT_DROP" 5 "SHORT_DROP_REVERSE" 6 "MOVING_AUTO_UP" 7 "MOVING_AUTO_DOWN" 8 "BACKDRIVE" ;
VAL_ 707 VCRIGHT_windowStatusIndex 0 "Mux0" 1 "Mux1" ;
CM_ BO_ 711 "ESP32-DualCAN Model3_VEH. Seen on this car: 8-byte frames; fit good (bits covered 100%, mux 100%, ranges 100%).";
CM_ BO_ 727 "ESP32-DualCAN Model3_VEH. Seen on this car: 4-byte frames; fit ok (bits covered 100%, mux 100%, ranges 100%).";
VAL_ 727 VCLEFT_pitchEstimate 4294967232 "SNA" ;
CM_ BO_ 728 "ESP32-DualCAN Model3_VEH. Seen on this car: 2-byte frames; fit poor (bits covered 0%, mux 100%, ranges 100%).";
VAL_ 728 ICR_nmWakeUpReason 0 "NONE" 1 "CAN_VEH" 2 "CAN_HVS" 3 "WANTTOCHARGE" 4 "CRITICALALERT" 5 "WANTTOWARM" ;
VAL_ 728 ICR_nmKeepAwakeReason 0 "NONE_SNA" 1 "CTRS_CLOSED" 2 "CRITICAL_ALERT" 3 "FC_CTR_CLEANING" 4 "HVP_ACTIVE" 5 "BMS_ACTIVE" 6 "CP_ACTIVE" ;
CM_ BO_ 738 "ESP32-DualCAN Model3_VEH. Seen on this car: 8-byte frames; fit good (bits covered 100%, mux 100%, ranges 100%).";
VAL_ 738 VCLEFT_frontSeatHeatTmpTarget 0 "OFF" ;
VAL_ 738 VCLEFT_frontSeatHeatTmp 0 "SNA" ;
VAL_ 738 VCLEFT_seatStatus2Index 0 "SEAT_HEAT_FRONT" 1 "SEAT_HEAT_REARL_BACKREST" 2 "OCCUPANCY" 3 "SEAT_HEAT_REARL" 4 "SEAT_HEAT_REARC" 5 "SEAT_HEAT_REARR_CUSHION" 6 "SEAT_2ROW_ACTUATOR" 7 "SEAT_SWITCH_VOLTAGES_1" 8 "SEAT_SWITCH_VOLTAGES_2" 9 "SEAT_2ROW_EASY_ENTRY" 10 "SEAT_STATUS_2_INDEX_COUNT" ;
CM_ BO_ 739 "ESP32-DualCAN Model3_VEH. Seen on this car: 7-byte frames; fit ok (bits covered 100%, mux 100%, ranges 100%).";
VAL_ 739 VCRIGHT_frontSeatHeatTmpTarget 0 "OFF" ;
VAL_ 739 VCRIGHT_frontSeatHeatTmp 0 "SNA" ;
VAL_ 739 VCRIGHT_seatStatus2Index 0 "SEAT_HEAT_FRONT" 1 "SEAT_HEAT_REARL_CUSHION" 2 "SEAT_HEAT_REARC" 3 "SEAT_HEAT_REARR" 4 "OCCUPANCY" 5 "SEAT_HEAT_REARR_BACKREST" 6 "SEAT_2ROW_ACTUATOR" 7 "SEAT_SWITCH_VOLTAGES_1" 8 "SEAT_SWITCH_VOLTAGES_2" 9 "SEAT_2ROW_EASY_ENTRY" 10 "OCS_IEE" 11 "SEAT_STATUS_2_INDEX_COUNT" ;
CM_ BO_ 748 "ESP32-DualCAN Model3_VEH. Seen on this car: 3-byte frames; fit ok (bits covered 100%, mux 100%, ranges 100%, checksum 100%).";
CM_ BO_ 760 "ESP32-DualCAN Model3_CH. Seen on this car: 8-byte frames; fit good (bits covered 100%, mux 100%, ranges 100%).";
VAL_ 760 UI_conditionalSpeedLimit 31 "SNA" ;
VAL_ 760 UI_userSpeedOffsetUnits 0 "MPH" 1 "KPH" ;
VAL_ 760 UI_mapSpeedLimitUnits 0 "MPH" 1 "KPH" ;
CM_ BO_ 761 "ESP32-DualCAN Model3_VEH. Seen on this car: 8-byte frames; fit good (bits covered 100%, mux 100%, ranges 100%).";
VAL_ 761 VCSEC_AdditionalAuthInfoIndex 0 "ACTIVE_KEY_SHA1" 1 "KEY_WITH_IN_SUMMON_RANGE_0" 2 "KEY_WITH_IN_SUMMON_RANGE_1" 3 "KEY_WITH_IN_SUMMON_RANGE_2" 4 "UNKNOWN_BLE_DEVICE_WITH_IN_SUMMON_RANGE" 5 "WALKUP_UNLOCK_BEHAVIOR" ;
VAL_ 761 VCSEC_activeKeyReason 0 "NONE" 1 "NFC_AUTH" 2 "RKE_AUTH" 3 "BLE_DEVICE_CLOSEST_TO_DOOR" 4 "RKE_ACTION" 5 "ONLY_AUTHED_DEVICE" 6 "AUTO_PRESENT_DOOR_COMMAND" ;
VAL_ 761 VCSEC_bleDisconnectionReason 0 "UNKNOWN_REASON_0" 5 "AUTHENTICATION_FAILURE" 8 "CONNECTION_SUPERVISION_TIMEOUT" 19 "REMOTE_USER_TERMINATED" 20 "REMOTE_DEVICE_LOW_RESOURCES" 21 "REMOTE_DEVICE_POWER_OFF" 22 "HOST_REQUESTED_TERMINATION" 26 "UNSUPPORTED_REMOTE_FEATURE" 34 "CONTROL_PACKET_TIMEOUT" 40 "CONTROL_PACKET_INSTANT_PASSED" 41 "KEY_PAIRING_NOT_SUPPORTED" 59 "UNACCEPTABLE_CONNECTION_INTERVAL" 61 "MIC_FAILURE" 62 "CONNECTION_FAILED_TO_ESTABLISH" 255 "UNKNOWN_REASON_FF" ;
CM_ BO_ 776 "ESP32-DualCAN Model3_VEH. Seen on this car: 8-byte frames; fit ok (bits covered 88%, mux 100%, ranges 100%, checksum 0%).";
VAL_ 776 OCS1P_occupantClassificationQF 0 "FAULTED" 1 "NOT_FAULTED" ;
VAL_ 776 OCS1P_occupantClassification 0 "EMPTY" 1 "INHIBIT" 2 "SMALL" 3 "LARGE" 4 "INIT" 5 "NOT_CONFIGURED" 7 "SNA" ;
CM_ BO_ 783 "ESP32-DualCAN Model3_CH. Seen on this car: 6-byte frames; fit poor (bits covered 0%, mux 100%, ranges 100%).";
CM_ BO_ 793 "ESP32-DualCAN Model3_VEH. Seen on this car: 8-byte frames; fit good (bits covered 100%, mux 100%, ranges 100%).";
VAL_ 793 VCSEC_infoAssemblyId 1 "ASSEMBLY1" 255 "ASSEMBLY_SNA" ;
VAL_ 793 VCSEC_infoBuildType 0 "UNKNOWN_BUILD" 1 "PLATFORM_BUILD" 2 "LOCAL_BUILD" 3 "TRACEABLE_CI_BUILD" 4 "MFG_BUILD" ;
VAL_ 793 VCSEC_infoIndex 0 "DEPRECATED_0" 1 "DEPRECATED_1" 2 "DEPRECATED_2" 3 "DEPRECATED_3" 4 "DEPRECATED_4" 5 "DEPRECATED_5" 6 "DEPRECATED_6" 7 "DEPRECATED_7" 8 "DEPRECATED_8" 9 "DEPRECATED_9" 10 "BUILD_HWID_COMPONENTID" 11 "PCBAID_ASSYID_USAGEID" 13 "APP_CRC" 14 "BOOTLOADER_SVN" 15 "BOOTLOADER_CRC" 16 "SUBCOMPONENT1" 17 "APP_GITHASH" 18 "BOOTLOADER_GITHASH" 19 "VERSION_DEPRECATED" 20 "UDS_PROTOCOL_BOOTCRC" 23 "SUBCOMPONENT2" 24 "SUBCOMPONENT3" 31 "SUBCOMPONENT4" 32 "SUBCOMPONENT5" 33 "SUBCOMPONENT6" 34 "SUBCOMPONENT7" 35 "SUBCOMPONENT8" 36 "SUBCOMPONENT9" 37 "SUBCOMPONENT10" 38 "SUBCOMPONENT11" 39 "SUBCOMPONENT12" 40 "SUBCOMPONENT13" 41 "SUBCOMPONENT14" 255 "END" ;
CM_ BO_ 794 "ESP32-DualCAN Model3_VEH. Seen on this car: 8-byte frames; fit good (bits covered 100%, mux 100%, ranges 100%, checksum 100%).";
VAL_ 794 VCRIGHT_occupantClassificationQF 0 "FAULTED" 1 "NOT_FAULTED" ;
VAL_ 794 VCRIGHT_occupantClassification 0 "EMPTY" 1 "INHIBIT" 2 "SMALL" 3 "LARGE" 4 "INIT" 5 "NOT_CONFIGURED" 7 "SNA" ;
VAL_ 794 VCRIGHT_seatTrackPosition 0 "FORWARD" 1 "REARWARD" 2 "NOT_CONFIGURED" 3 "FAULTED" 7 "SNA" ;
VAL_ 794 VCRIGHT_3RowRightOccupancyStatus 0 "UNOCCUPIED" 1 "OCCUPIED" 2 "OCCUPANCY_FAULTED" 3 "OCCUPANCY_SNA" ;
VAL_ 794 VCRIGHT_3RowLeftOccupancyStatus 0 "UNOCCUPIED" 1 "OCCUPIED" 2 "OCCUPANCY_FAULTED" 3 "OCCUPANCY_SNA" ;
VAL_ 794 VCRIGHT_3RowRightBuckleStatus 0 "UNLATCHED" 1 "LATCHED" 2 "FAULTED" 3 "SNA" ;
VAL_ 794 VCRIGHT_3RowLeftBuckleStatus 0 "UNLATCHED" 1 "LATCHED" 2 "FAULTED" 3 "SNA" ;
VAL_ 794 VCRIGHT_rearRightOccupancyStatus 0 "UNOCCUPIED" 1 "OCCUPIED" 2 "OCCUPANCY_FAULTED" 3 "OCCUPANCY_SNA" ;
VAL_ 794 VCRIGHT_rearRightBuckleStatus 0 "UNLATCHED" 1 "LATCHED" 2 "FAULTED" 3 "SNA" ;
VAL_ 794 VCRIGHT_rearCenterBuckleStatus 0 "UNLATCHED" 1 "LATCHED" 2 "FAULTED" 3 "SNA" ;
VAL_ 794 VCRIGHT_frontBuckleStatus 0 "UNLATCHED" 1 "LATCHED" 2 "FAULTED" 3 "SNA" ;
VAL_ 794 VCRIGHT_frontOccupancyStatus 0 "UNOCCUPIED" 1 "OCCUPIED" 2 "OCCUPANCY_FAULTED" 3 "NOT_CONFIGURED" 7 "OCCUPANCY_SNA" ;
CM_ BO_ 803 "ESP32-DualCAN Model3_VEH. Seen on this car: 5-byte frames; fit ok (bits covered 100%, mux 100%, ranges 100%).";
CM_ BO_ 804 "ESP32-DualCAN Model3_VEH. Seen on this car: 8-byte frames; fit good (bits covered 100%, mux 100%, ranges 100%).";
CM_ BO_ 820 "ESP32-DualCAN Model3_VEH. Seen on this car: 8-byte frames; fit ok (bits covered 82%, mux 100%, ranges 100%, checksum 100%).";
VAL_ 820 UI_speedLimit 511 "SNA" ;
VAL_ 820 UI_stoppingMode 0 "STANDARD" 1 "CREEP" 2 "HOLD" ;
VAL_ 820 UI_wasteModeRegenLimit 0 "MAX" 1 "30A" 2 "10A" 3 "0A" ;
VAL_ 820 UI_wasteMode 0 "NONE" 1 "PARTIAL" 2 "FULL" 3 "BURN_IN" ;
VAL_ 820 UI_motorOnMode 0 "NORMAL" 1 "FRONT_ONLY" 2 "REAR_ONLY" ;
VAL_ 820 UI_limitMode 0 "NORMAL" 1 "VALET" 2 "FACTORY" 3 "SERVICE" ;
VAL_ 820 UI_closureConfirmed 0 "NONE" 1 "FRUNK" 2 "PROX" 3 "FALCON" ;
VAL_ 820 UI_systemTorqueLimit 63 "SNA" ;
VAL_ 820 UI_pedalMap 0 "CHILL" 1 "SPORT" 2 "PERFORMANCE" ;
VAL_ 820 UI_systemPowerLimit 31 "SNA" ;
CM_ BO_ 829 "ESP32-DualCAN Model3_VEH. Seen on this car: 8-byte frames; fit weak (bits covered 0%, mux 100%, ranges 100%).";
CM_ BO_ 835 "ESP32-DualCAN Model3_VEH. Seen on this car: 8-byte frames; fit good (bits covered 100%, mux 100%, ranges 100%).";
VAL_ 835 VCRIGHT_mirrorHeatState 0 "SNA" 1 "ON" 2 "OFF" 3 "OFF_UNAVAILABLE" 4 "FAULT" ;
CM_ BO_ 836 "ESP32-DualCAN Model3_VEH. Seen on this car: 8-byte frames; fit good (bits covered 100%, mux 100%, ranges 100%, checksum 100%).";
CM_ BO_ 838 "ESP32-DualCAN Model3_CH. Seen on this car: 8-byte frames; fit weak (bits covered 0%, mux 100%, ranges 100%).";
VAL_ 838 GTW_autopilotOverrideState 0 "BASE" 1 "SUBSCRIPTION" 2 "TRIAL" ;
CM_ BO_ 839 "DashKit DBC. Seen on this car: 8-byte frames; fit ok (bits covered 58%, mux 100%, ranges 100%).";
CM_ BO_ 842 "ESP32-DualCAN Model3_VEH. Seen on this car: 8-byte frames; fit good (bits covered 100%, mux 100%, ranges 100%).";
CM_ BO_ 843 "ESP32-DualCAN Model3_CH. Seen on this car: 6-byte frames; fit ok (bits covered 100%, mux 100%, ranges 100%).";
CM_ BO_ 847 "ESP32-DualCAN Model3_CH. Seen on this car: 8-byte frames; fit good (bits covered 100%, mux 100%, ranges 100%).";
CM_ BO_ 852 "ESP32-DualCAN Model3_CH. Seen on this car: 6-byte frames; fit ok (bits covered 100%, mux 100%, ranges 100%).";
CM_ BO_ 853 "ESP32-DualCAN Model3_VEH. Seen on this car: 7-byte frames; fit ok (bits covered 100%, mux 100%, ranges 100%).";
CM_ BO_ 863 "ESP32-DualCAN Model3_VEH. Seen on this car: 1-byte frames; fit poor (bits covered 0%, mux 100%, ranges 100%).";
CM_ BO_ 865 "ESP32-DualCAN Model3_VEH. Seen on this car: 5-byte frames; fit ok (bits covered 100%, mux 100%, ranges 100%).";
CM_ BO_ 866 "ESP32-DualCAN Model3_VEH. Seen on this car: 3-byte frames; fit poor (bits covered 0%, mux 100%, ranges 100%).";
VAL_ 866 VCLEFT_crashState 0 "IDLE" 1 "MINOR_1" 2 "MINOR_2" 3 "SEVERE" ;
VAL_ 866 VCLEFT_crashDetectedType 0 "NONE" 1 "MINOR_1" 2 "MINOR_2" 3 "SEVERE" ;
CM_ BO_ 868 "ESP32-DualCAN Model3_VEH. Seen on this car: 4-byte frames; fit ok (bits covered 100%, mux 100%, ranges 100%).";
CM_ BO_ 870 "ESP32-DualCAN Model3_VEH. Seen on this car: 8-byte frames; fit ok (bits covered 100%, mux 100%, ranges 100%).";
VAL_ 870 CMPD_infoAssemblyId 1 "ASSEMBLY1" 255 "ASSEMBLY_SNA" ;
VAL_ 870 CMPD_infoBuildType 0 "UNKNOWN_BUILD" 1 "PLATFORM_BUILD" 2 "LOCAL_BUILD" 3 "TRACEABLE_CI_BUILD" 4 "MFG_BUILD" ;
VAL_ 870 CMPD_infoIndex 0 "DEPRECATED_0" 1 "DEPRECATED_1" 2 "DEPRECATED_2" 3 "DEPRECATED_3" 4 "DEPRECATED_4" 5 "DEPRECATED_5" 6 "DEPRECATED_6" 7 "DEPRECATED_7" 8 "DEPRECATED_8" 9 "DEPRECATED_9" 10 "BUILD_HWID_COMPONENTID" 11 "PCBAID_ASSYID_USAGEID" 13 "APP_CRC" 14 "BOOTLOADER_SVN" 15 "BOOTLOADER_CRC" 16 "SUBCOMPONENT" 17 "APP_GITHASH" 18 "BOOTLOADER_GITHASH" 19 "VERSION_DEPRECATED" 20 "UDS_PROTOCOL_BOOTCRC" 22 "VARIANTCRC" 25 "PACKAGE_PN_1_7" 26 "PACKAGE_PN_8_14" 27 "PACKAGE_PN_15_20" 29 "PACKAGE_SN_1_7" 30 "PACKAGE_SN_8_14" 31 "SUBCOMPONENT_GITHASH" 255 "END" ;
CM_ BO_ 871 "ESP32-DualCAN Model3_VEH. Seen on this car: 8-byte frames; fit ok (bits covered 50%, mux 100%, ranges 100%).";
CM_ BO_ 893 "ESP32-DualCAN Model3_VEH. Seen on this car: 8-byte frames; fit good (bits covered 100%, mux 100%, ranges 100%).";
VAL_ 893 CP_thermalStatusSelect 0 "0" 1 "1" ;
CM_ BO_ 898 "ESP32-DualCAN Model3_VEH. Seen on this car: 5-byte frames; fit ok (bits covered 100%, mux 100%, ranges 100%).";
CM_ BO_ 899 "ESP32-DualCAN Model3_CH. Seen on this car: 8-byte frames; fit ok (bits covered 100%, mux 100%, ranges 100%, checksum 0%).";
VAL_ 899 VCRIGHT_occupantClassificationQF 0 "FAULTED" 1 "NOT_FAULTED" ;
VAL_ 899 VCRIGHT_occupantClassification 0 "EMPTY" 1 "INHIBIT" 2 "SMALL" 3 "LARGE" 4 "INIT" 5 "NOT_CONFIGURED" 7 "SNA" ;
VAL_ 899 VCRIGHT_seatTrackPosition 0 "FORWARD" 1 "REARWARD" 2 "NOT_CONFIGURED" 3 "FAULTED" 7 "SNA" ;
VAL_ 899 VCRIGHT_3RowRightOccupancyStatus 0 "UNOCCUPIED" 1 "OCCUPIED" 2 "OCCUPANCY_FAULTED" 3 "OCCUPANCY_SNA" ;
VAL_ 899 VCRIGHT_3RowLeftOccupancyStatus 0 "UNOCCUPIED" 1 "OCCUPIED" 2 "OCCUPANCY_FAULTED" 3 "OCCUPANCY_SNA" ;
VAL_ 899 VCRIGHT_3RowRightBuckleStatus 0 "UNLATCHED" 1 "LATCHED" 2 "FAULTED" 3 "SNA" ;
VAL_ 899 VCRIGHT_3RowLeftBuckleStatus 0 "UNLATCHED" 1 "LATCHED" 2 "FAULTED" 3 "SNA" ;
VAL_ 899 VCRIGHT_rearRightOccupancyStatus 0 "UNOCCUPIED" 1 "OCCUPIED" 2 "OCCUPANCY_FAULTED" 3 "OCCUPANCY_SNA" ;
VAL_ 899 VCRIGHT_rearRightBuckleStatus 0 "UNLATCHED" 1 "LATCHED" 2 "FAULTED" 3 "SNA" ;
VAL_ 899 VCRIGHT_rearCenterBuckleStatus 0 "UNLATCHED" 1 "LATCHED" 2 "FAULTED" 3 "SNA" ;
VAL_ 899 VCRIGHT_frontBuckleStatus 0 "UNLATCHED" 1 "LATCHED" 2 "FAULTED" 3 "SNA" ;
VAL_ 899 VCRIGHT_frontOccupancyStatus 0 "UNOCCUPIED" 1 "OCCUPIED" 2 "OCCUPANCY_FAULTED" 3 "NOT_CONFIGURED" 7 "OCCUPANCY_SNA" ;
CM_ BO_ 902 "ESP32-DualCAN Model3_VEH. Seen on this car: 8-byte frames; fit ok (bits covered 67%, mux 100%, ranges 100%).";
CM_ BO_ 907 "ESP32-DualCAN Model3_CH. Seen on this car: 5-byte frames; fit ok (bits covered 100%, mux 100%, ranges 100%).";
CM_ BO_ 912 "ESP32-DualCAN Model3_VEH. Seen on this car: 2-byte frames; fit poor (bits covered 0%, mux 100%, ranges 100%).";
CM_ BO_ 919 "ESP32-DualCAN Model3_VEH. Seen on this car: 8-byte frames; fit good (bits covered 100%, mux 100%, ranges 100%).";
CM_ BO_ 922 "ESP32-DualCAN Model3_VEH. Seen on this car: 8-byte frames; fit good (bits covered 100%, mux 100%, ranges 100%).";
VAL_ 922 VCSEC_RSSI2ConnectionType 0 "NONE" 1 "PERIPHERAL" 2 "CENTRAL" ;
VAL_ 922 VCSEC_RSSI1ConnectionType 0 "NONE" 1 "PERIPHERAL" 2 "CENTRAL" ;
VAL_ 922 VCSEC_RSSI0ConnectionType 0 "NONE" 1 "PERIPHERAL" 2 "CENTRAL" ;
CM_ BO_ 923 "ESP32-DualCAN Model3_VEH. Seen on this car: 8-byte frames; fit good (bits covered 100%, mux 100%, ranges 100%, checksum 100%).";
VAL_ 923 DAS_autoLaneChangeState 0 "UNAVAILABLE_DISABLED" 1 "UNAVAILABLE_NO_LANES" 2 "UNAVAILABLE_SONICS_INVALID" 3 "UNAVAILABLE_TP_FOLLOW" 4 "UNAVAILABLE_EXITING_HIGHWAY" 5 "UNAVAILABLE_VEHICLE_SPEED" 6 "AVAILABLE_ONLY_L" 7 "AVAILABLE_ONLY_R" 8 "AVAILABLE_BOTH" 9 "IN_PROGRESS_L" 10 "IN_PROGRESS_R" 11 "WAITING_FOR_SIDE_OBST_TO_PASS_L" 12 "WAITING_FOR_SIDE_OBST_TO_PASS_R" 13 "WAITING_FOR_FWD_OBST_TO_PASS_L" 14 "WAITING_FOR_FWD_OBST_TO_PASS_R" 15 "ABORT_SIDE_OBSTACLE_PRESENT_L" 16 "ABORT_SIDE_OBSTACLE_PRESENT_R" 17 "ABORT_POOR_VIEW_RANGE" 18 "ABORT_LC_HEALTH_BAD" 19 "ABORT_BLINKER_TURNED_OFF" 20 "ABORT_OTHER_REASON" 21 "UNAVAILABLE_SOLID_LANE_LINE" 22 "BLOCKED_VEH_TTC_L" 23 "BLOCKED_VEH_TTC_AND_USS_L" 24 "BLOCKED_VEH_TTC_R" 25 "BLOCKED_VEH_TTC_AND_USS_R" 26 "BLOCKED_LANE_TYPE_L" 27 "BLOCKED_LANE_TYPE_R" 28 "WAITING_HANDS_ON" 29 "ABORT_TIMEOUT" 30 "ABORT_MISSION_PLAN_INVALID" 31 "SNA" ;
VAL_ 923 DAS_autopilotHandsOnState 0 "NOT_REQD" 1 "REQD_DETECTED" 2 "REQD_NOT_DETECTED" 3 "REQD_VISUAL" 4 "REQD_CHIME_1" 5 "REQD_CHIME_2" 6 "REQD_SLOWING" 7 "REQD_STRUCK_OUT" 8 "SUSPENDED" 9 "REQD_ESCALATED_CHIME_1" 10 "REQD_ESCALATED_CHIME_2" 15 "SNA" ;
VAL_ 923 DAS_fleetSpeedState 0 "UNAVAILABLE" 1 "AVAILABLE" 2 "ACTIVE" 3 "HOLD" ;
VAL_ 923 DAS_laneDepartureWarning 0 "NONE" 1 "LEFT_WARNING" 2 "RIGHT_WARNING" 3 "LEFT_WARNING_SEVERE" 4 "RIGHT_WARNING_SEVERE" 5 "SNA" ;
VAL_ 923 DAS_sideCollisionInhibit 0 "NO_INHIBIT" 1 "INHIBIT" ;
VAL_ 923 DAS_sideCollisionWarning 0 "NONE" 1 "WARN_LEFT" 2 "WARN_RIGHT" 3 "WARN_LEFT_RIGHT" ;
VAL_ 923 DAS_sideCollisionAvoid 0 "NONE" 1 "AVOID_LEFT" 2 "AVOID_RIGHT" 3 "SNA" ;
VAL_ 923 DAS_lssState 0 "FAULT" 1 "LDW" 2 "LKA" 3 "ELK" 4 "MONITOR" 5 "BLINDSPOT" 6 "ABORT" 7 "OFF" ;
VAL_ 923 DAS_autoparkReady 0 "UNAVAILABLE" 1 "READY" ;
VAL_ 923 DAS_forwardCollisionWarning 0 "NONE" 1 "FORWARD_COLLISION_WARNING" 3 "SNA" ;
VAL_ 923 DAS_heaterState 0 "OFF_SNA" 1 "ON" ;
VAL_ 923 DAS_visionOnlySpeedLimit 0 "UNKNOWN_SNA" 31 "NONE" ;
VAL_ 923 DAS_suppressSpeedWarning 0 "Do_Not_Suppress" 1 "Suppress_Speed_Warning" ;
VAL_ 923 DAS_fusedSpeedLimit 0 "UNKNOWN_SNA" 31 "NONE" ;
VAL_ 923 DAS_blindSpotRearRight 0 "NO_WARNING" 1 "WARNING_LEVEL_1" 2 "WARNING_LEVEL_2" 3 "SNA" ;
VAL_ 923 DAS_blindSpotRearLeft 0 "NO_WARNING" 1 "WARNING_LEVEL_1" 2 "WARNING_LEVEL_2" 3 "SNA" ;
VAL_ 923 DAS_autopilotState 0 "DISABLED" 1 "UNAVAILABLE" 2 "AVAILABLE" 3 "ACTIVE_NOMINAL" 4 "ACTIVE_RESTRICTED" 5 "ACTIVE_NAV" 6 "ACTIVE_FSD" 8 "ABORTING" 9 "ABORTED" 14 "FAULT" 15 "SNA" ;
CM_ BO_ 931 "ESP32-DualCAN Model3_VEH. Seen on this car: 8-byte frames; fit good (bits covered 100%, mux 100%, ranges 100%).";
CM_ BO_ 935 "ESP32-DualCAN Model3_VEH. Seen on this car: 8-byte frames; fit good (bits covered 100%, mux 100%, ranges 100%).";
CM_ BO_ 936 "ESP32-DualCAN Model3_VEH. Seen on this car: 8-byte frames; fit good (bits covered 100%, mux 100%, ranges 100%).";
VAL_ 936 VCLEFT_logging1HzIndex 0 "HVAC_ACTUATOR_VOLTAGES" 1 "HVAC_ACTUATOR_ENDSTOP" 2 "HVAC_ACTUATOR_ZEROSTOP" 3 "HVAC_ACTUATOR_OPERATION_MODE" 4 "END" ;
CM_ BO_ 939 "ESP32-DualCAN Model3_CH. Seen on this car: 5-byte frames; fit poor (bits covered 0%, mux 100%, ranges 100%).";
CM_ BO_ 942 "ESP32-DualCAN Model3_VEH. Seen on this car: 8-byte frames; fit ok (bits covered 100%, mux 100%, ranges 100%, checksum 0%).";
VAL_ 942 APP_summonState 0 "INIT" 1 "IDLE" 2 "ARMED" 3 "ACTIVE" 4 "COMPLETE" 5 "FAULT" 6 "UNAVAILABLE" ;
CM_ BO_ 943 "ESP32-DualCAN Model3_CH. Seen on this car: 8-byte frames; fit good (bits covered 100%, mux 100%, ranges 100%).";
CM_ BO_ 955 "ESP32-DualCAN Model3_VEH. Seen on this car: 3-byte frames; fit poor (bits covered 0%, mux 100%, ranges 100%).";
CM_ BO_ 956 "ESP32-DualCAN Model3_VEH. Seen on this car: 4-byte frames; fit poor (bits covered 0%, mux 100%, ranges 100%).";
CM_ BO_ 963 "ESP32-DualCAN Model3_VEH. Seen on this car: 8-byte frames; fit good (bits covered 100%, mux 100%, ranges 100%).";
VAL_ 963 VCRIGHT_rearRightOccupancySwitch 0 "SNA" 1 "OFF" 2 "ON" 3 "FAULT" ;
VAL_ 963 VCRIGHT_rearCenterBuckleSwitch 0 "SNA" 1 "OFF" 2 "ON" 3 "FAULT" ;
VAL_ 963 VCRIGHT_frontOccupancySwitch 0 "SNA" 1 "OFF" 2 "ON" 3 "FAULT" ;
VAL_ 963 VCRIGHT_frontBuckleSwitch 0 "SNA" 1 "OFF" 2 "ON" 3 "FAULT" ;
VAL_ 963 VCRIGHT_frontSeatLumbarOut 0 "SNA" 1 "OFF" 2 "ON" 3 "FAULT" ;
VAL_ 963 VCRIGHT_frontSeatLumbarIn 0 "SNA" 1 "OFF" 2 "ON" 3 "FAULT" ;
VAL_ 963 VCRIGHT_frontSeatLumbarUp 0 "SNA" 1 "OFF" 2 "ON" 3 "FAULT" ;
VAL_ 963 VCRIGHT_frontSeatLumbarDown 0 "SNA" 1 "OFF" 2 "ON" 3 "FAULT" ;
VAL_ 963 VCRIGHT_frontSeatBackrestForward 0 "SNA" 1 "OFF" 2 "ON" 3 "FAULT" ;
VAL_ 963 VCRIGHT_frontSeatBackrestBack 0 "SNA" 1 "OFF" 2 "ON" 3 "FAULT" ;
VAL_ 963 VCRIGHT_frontSeatLiftUp 0 "SNA" 1 "OFF" 2 "ON" 3 "FAULT" ;
VAL_ 963 VCRIGHT_frontSeatLiftDown 0 "SNA" 1 "OFF" 2 "ON" 3 "FAULT" ;
VAL_ 963 VCRIGHT_frontSeatTiltUp 0 "SNA" 1 "OFF" 2 "ON" 3 "FAULT" ;
VAL_ 963 VCRIGHT_frontSeatTiltDown 0 "SNA" 1 "OFF" 2 "ON" 3 "FAULT" ;
VAL_ 963 VCRIGHT_frontSeatTrackForward 0 "SNA" 1 "OFF" 2 "ON" 3 "FAULT" ;
VAL_ 963 VCRIGHT_frontSeatTrackBack 0 "SNA" 1 "OFF" 2 "ON" 3 "FAULT" ;
VAL_ 963 VCRIGHT_switchStatusIndex 0 "0" 1 "1" 2 "INVALID" ;
CM_ BO_ 969 "ESP32-DualCAN Model3_VEH. Seen on this car: 8-byte frames; fit good (bits covered 100%, mux 100%, ranges 100%).";
VAL_ 969 VCSEC_BLEEndpointInfoIndex 0 "BLELeftInfo" 1 "BLERightInfo" 2 "BLERearInfo" 3 "BLECenterInfo" 4 "BLELeftAppGithash" 5 "BLERightAppGithash" 6 "BLERearAppGithash" 7 "BLECenterAppGithash" 8 "BLEFrontInfo" 9 "BLESecondaryInfo" 10 "BLENFCCradleInfo" 11 "BLELeftRearInfo" 12 "BLERightRearInfo" 13 "BLEFrontAppGithash" 14 "BLESecondaryAppGithash" 15 "BLENFCCradleAppGithash" 16 "BLELeftRearAppGithash" 17 "BLERightRearAppGithash" 18 "UWBLeftInfo" 19 "UWBRightInfo" 20 "UWBRearLeftInfo" 21 "UWBRearRightInfo" 22 "UWBFrontInfo" 23 "UWBLeftAppGithash" 24 "UWBRightAppGithash" 25 "UWBRearLeftAppGithash" 26 "UWBRearRightAppGithash" 27 "UWBFrontAppGithash" ;
CM_ BO_ 971 "ESP32-DualCAN Model3_CH. Seen on this car: 5-byte frames; fit ok (bits covered 100%, mux 100%, ranges 100%).";
CM_ BO_ 1251 "ESP32-DualCAN Model3_VEH. Seen on this car: 8-byte frames; fit good (bits covered 100%, mux 100%, ranges 100%).";
VAL_ 1251 VCRIGHT_frontSeatBackState 0 "STOPPED" 1 "MOVING_UP" 2 "MOVING_DOWN" 3 "RECALLING" 4 "CALIBRATING" 5 "UNDEFINED" ;
VAL_ 1251 VCRIGHT_frontSeatLiftState 0 "STOPPED" 1 "MOVING_UP" 2 "MOVING_DOWN" 3 "RECALLING" 4 "CALIBRATING" 5 "UNDEFINED" ;
VAL_ 1251 VCRIGHT_frontSeatTiltState 0 "STOPPED" 1 "MOVING_UP" 2 "MOVING_DOWN" 3 "RECALLING" 4 "CALIBRATING" 5 "UNDEFINED" ;
VAL_ 1251 VCRIGHT_frontSeatTrackState 0 "STOPPED" 1 "MOVING_UP" 2 "MOVING_DOWN" 3 "RECALLING" 4 "CALIBRATING" 5 "UNDEFINED" ;
VAL_ 1251 VCRIGHT_lumbarBState 0 "STOPPED" 1 "MOVING_UP" 2 "MOVING_DOWN" 3 "RECALLING" 4 "CALIBRATING" 5 "UNDEFINED" ;
VAL_ 1251 VCRIGHT_lumbarAState 0 "STOPPED" 1 "MOVING_UP" 2 "MOVING_DOWN" 3 "RECALLING" 4 "CALIBRATING" 5 "UNDEFINED" ;
VAL_ 1251 VCRIGHT_seatStatusIndex 0 "TRACK" 1 "BACK" 2 "LIFT" 3 "TILT" 4 "LUMBAR" 5 "POSITION" ;
